VERSION ""

NS_ :

BS_:

BU_: VMCU TPM RCIOM FCIOM FAS ECUspare4 EBS EAS CCIOM BPMU APM

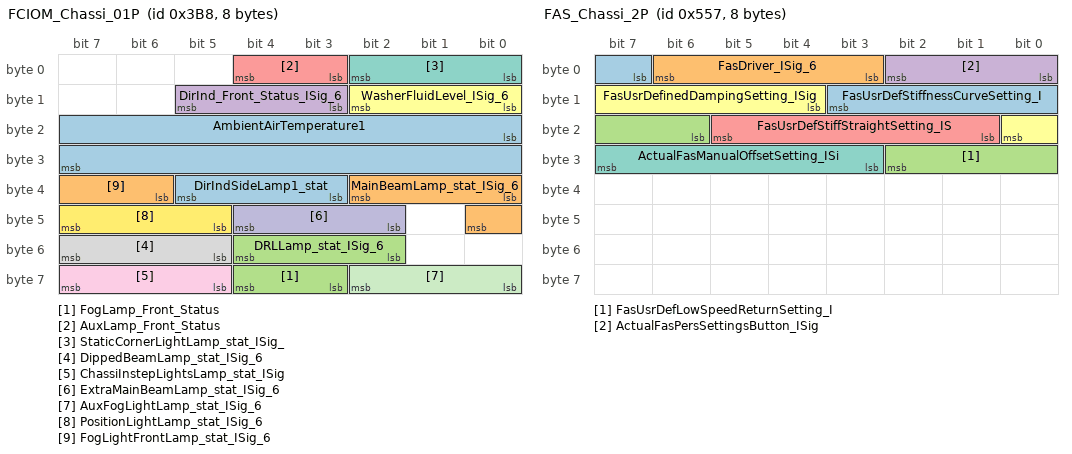
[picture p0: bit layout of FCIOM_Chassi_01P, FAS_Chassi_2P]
BO_ 952 FCIOM_Chassi_01P: 8 FCIOM
 SG_ DirIndSideLamp1_stat : 35|3@1+ (1,0) [0|0] ""  VMCU
 SG_ MainBeamLamp_stat_ISig_6 : 32|3@1+ (1,0) [0|0] ""  VMCU
 SG_ FogLamp_Front_Status : 59|2@1+ (1,0) [0|0] ""  VMCU
 SG_ DirInd_Front_Status_ISig_6 : 11|3@1+ (1,0) [0|0] ""  VMCU
 SG_ AuxLamp_Front_Status : 3|2@1+ (1,0) [0|0] ""  VMCU
 SG_ WasherFluidLevel_ISig_6 : 8|3@1+ (1,0) [0|0] ""  VMCU
 SG_ StaticCornerLightLamp_stat_ISig_ : 0|3@1+ (1,0) [0|0] ""  VMCU
 SG_ DippedBeamLamp_stat_ISig_6 : 53|3@1+ (1,0) [0|0] ""  VMCU
 SG_ ChassiInstepLightsLamp_stat_ISig : 61|3@1+ (1,0) [0|0] ""  VMCU
 SG_ ExtraMainBeamLamp_stat_ISig_6 : 42|3@1+ (1,0) [0|0] ""  VMCU
 SG_ AuxFogLightLamp_stat_ISig_6 : 56|3@1+ (1,0) [0|0] ""  VMCU
 SG_ PositionLightLamp_stat_ISig_6 : 45|3@1+ (1,0) [0|0] ""  VMCU
 SG_ AmbientAirTemperature1 : 16|16@1+ (0.03125,-273) [-273|1774.96875] "DegreeC"  VMCU
 SG_ FogLightFrontLamp_stat_ISig_6 : 38|3@1+ (1,0) [0|0] ""  VMCU
 SG_ DRLLamp_stat_ISig_6 : 50|3@1+ (1,0) [0|0] ""  VMCU

BO_ 1367 FAS_Chassi_2P: 8 FAS
 SG_ FasUsrDefStiffnessCurveSetting_I : 7|5@1+ (1,-10) [-10|21] ""  VMCU
 SG_ FasDriver_ISig_6 : 3|4@1+ (1,0) [0|0] ""  VMCU
 SG_ FasUsrDefLowSpeedReturnSetting_I : 22|5@1+ (1,-10) [-10|21] ""  VMCU
 SG_ ActualFasPersSettingsButton_ISig : 0|3@1+ (1,0) [0|0] ""  VMCU
 SG_ FasUsrDefStiffStraightSetting_IS : 17|5@1+ (1,-10) [-10|21] ""  VMCU
 SG_ FasUsrDefinedDampingSetting_ISig : 12|5@1+ (1,-10) [-10|21] ""  VMCU
 SG_ ActualFasManualOffsetSetting_ISi : 27|5@1+ (1,-10) [-10|21] ""  VMCU

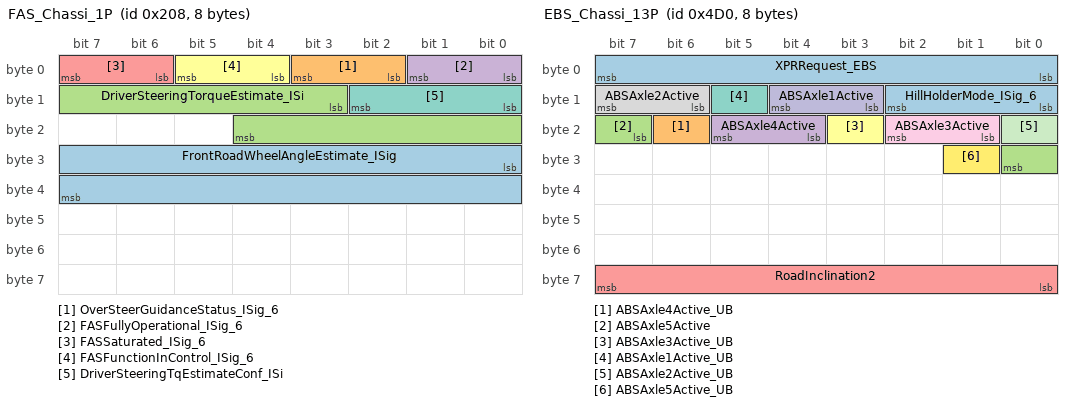
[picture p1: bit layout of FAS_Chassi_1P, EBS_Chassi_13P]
BO_ 520 FAS_Chassi_1P: 8 FAS
 SG_ FrontRoadWheelAngleEstimate_ISig : 24|16@1+ (5E-005,-1.6) [-1.6|1.67675] "rad"  VMCU
 SG_ OverSteerGuidanceStatus_ISig_6 : 2|2@1+ (1,0) [0|0] ""  VMCU
 SG_ DriverSteeringTorqueEstimate_ISi : 11|10@1+ (0.05,-25) [-25|26.15] "Nm"  VMCU
 SG_ FASFullyOperational_ISig_6 : 0|2@1+ (1,0) [0|0] ""  VMCU
 SG_ FASSaturated_ISig_6 : 6|2@1+ (1,0) [0|0] ""  VMCU
 SG_ FASFunctionInControl_ISig_6 : 4|2@1+ (1,0) [0|0] ""  VMCU
 SG_ DriverSteeringTqEstimateConf_ISi : 8|3@1+ (1,0) [0|0] ""  VMCU

BO_ 1232 EBS_Chassi_13P: 8 EBS
 SG_ XPRRequest_EBS : 0|8@1+ (1,0) [0|255] "NotApplicable"  APM
 SG_ ABSAxle4Active_UB : 22|1@1+ (1,0) [0|0] ""  APM
 SG_ ABSAxle5Active : 23|2@1+ (1,0) [0|0] ""  APM
 SG_ ABSAxle4Active : 20|2@1+ (1,0) [0|0] ""  APM
 SG_ RoadInclination2 : 56|8@1+ (0.2,-25) [-25|26] "percent"  VMCU
 SG_ ABSAxle3Active_UB : 19|1@1+ (1,0) [0|0] ""  APM
 SG_ ABSAxle1Active_UB : 13|1@1+ (1,0) [0|0] ""  APM
 SG_ ABSAxle2Active : 14|2@1+ (1,0) [0|0] ""  APM
 SG_ ABSAxle3Active : 17|2@1+ (1,0) [0|0] ""  APM
 SG_ ABSAxle1Active : 11|2@1+ (1,0) [0|0] ""  APM
 SG_ ABSAxle2Active_UB : 16|1@1+ (1,0) [0|0] ""  APM
 SG_ ABSAxle5Active_UB : 25|1@1+ (1,0) [0|0] ""  APM
 SG_ HillHolderMode_ISig_6 : 8|3@1+ (1,0) [0|0] ""  APM

BO_ 1507 EBS_Chassi_12P: 8 EBS
 SG_ ScndFrAxleLtRemainBrakeLining : 0|8@1+ (0.4,0) [0|102] "Percent"  VMCU
 SG_ ScndFrAxleRtRemainBrakeLining : 8|8@1+ (0.4,0) [0|102] "Percent"  VMCU

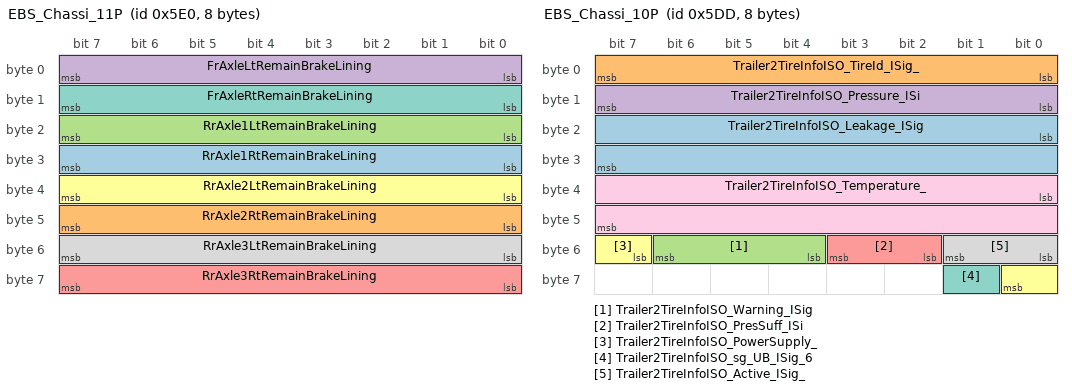
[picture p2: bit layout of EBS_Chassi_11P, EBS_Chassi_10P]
BO_ 1504 EBS_Chassi_11P: 8 EBS
 SG_ RrAxle1RtRemainBrakeLining : 24|8@1+ (0.4,0) [0|102] "Percent"  VMCU
 SG_ RrAxle2RtRemainBrakeLining : 40|8@1+ (0.4,0) [0|102] "Percent"  VMCU
 SG_ RrAxle1LtRemainBrakeLining : 16|8@1+ (0.4,0) [0|102] "Percent"  VMCU
 SG_ FrAxleLtRemainBrakeLining : 0|8@1+ (0.4,0) [0|102] "Percent"  VMCU
 SG_ RrAxle3RtRemainBrakeLining : 56|8@1+ (0.4,0) [0|102] "Percent"  VMCU
 SG_ RrAxle2LtRemainBrakeLining : 32|8@1+ (0.4,0) [0|102] "Percent"  VMCU
 SG_ FrAxleRtRemainBrakeLining : 8|8@1+ (0.4,0) [0|102] "Percent"  VMCU
 SG_ RrAxle3LtRemainBrakeLining : 48|8@1+ (0.4,0) [0|102] "Percent"  VMCU

BO_ 1501 EBS_Chassi_10P: 8 EBS
 SG_ Trailer2TireInfoISO_Leakage_ISig : 16|16@1+ (0.1,0) [0|6553.5] "Pa_per_s"  TPM
 SG_ Trailer2TireInfoISO_TireId_ISig_ : 0|8@1+ (1,0) [0|255] "NotApplicable"  TPM
 SG_ Trailer2TireInfoISO_Warning_ISig : 52|3@1+ (1,0) [0|0] ""  TPM
 SG_ Trailer2TireInfoISO_Pressure_ISi : 8|8@1+ (10,0) [0|2550] "kPa"  TPM
 SG_ Trailer2TireInfoISO_PresSuff_ISi : 50|2@1+ (1,0) [0|0] ""  TPM
 SG_ Trailer2TireInfoISO_PowerSupply_ : 55|2@1+ (1,0) [0|0] ""  TPM
 SG_ Trailer2TireInfoISO_sg_UB_ISig_6 : 57|1@1+ (1,0) [0|0] ""  TPM
 SG_ Trailer2TireInfoISO_Active_ISig_ : 48|2@1+ (1,0) [0|0] ""  TPM
 SG_ Trailer2TireInfoISO_Temperature_ : 32|16@1+ (0.03125,-273) [-273|1774.96875] "DegreeC"  TPM

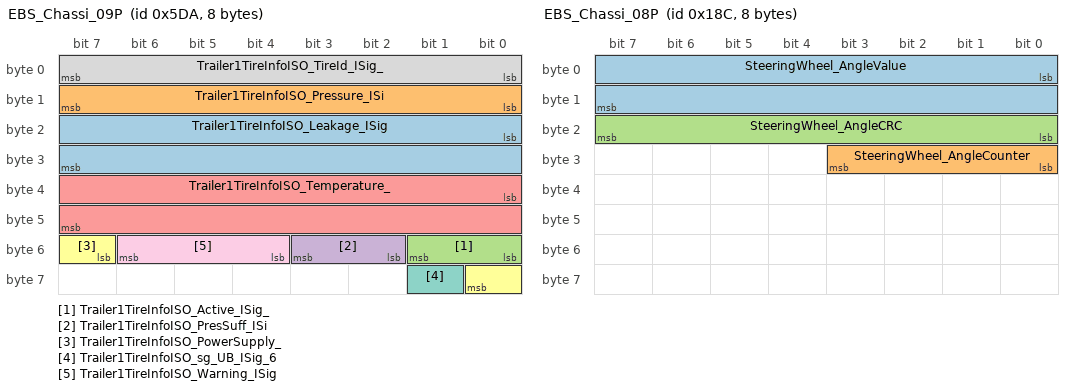
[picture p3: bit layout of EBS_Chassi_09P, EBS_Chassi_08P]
BO_ 1498 EBS_Chassi_09P: 8 EBS
 SG_ Trailer1TireInfoISO_Leakage_ISig : 16|16@1+ (0.1,0) [0|6553.5] "Pa_per_s"  TPM
 SG_ Trailer1TireInfoISO_Pressure_ISi : 8|8@1+ (10,0) [0|2550] "kPa"  TPM
 SG_ Trailer1TireInfoISO_Active_ISig_ : 48|2@1+ (1,0) [0|0] ""  TPM
 SG_ Trailer1TireInfoISO_PresSuff_ISi : 50|2@1+ (1,0) [0|0] ""  TPM
 SG_ Trailer1TireInfoISO_Temperature_ : 32|16@1+ (0.03125,-273) [-273|1774.96875] "DegreeC"  TPM
 SG_ Trailer1TireInfoISO_PowerSupply_ : 55|2@1+ (1,0) [0|0] ""  TPM
 SG_ Trailer1TireInfoISO_sg_UB_ISig_6 : 57|1@1+ (1,0) [0|0] ""  TPM
 SG_ Trailer1TireInfoISO_TireId_ISig_ : 0|8@1+ (1,0) [0|255] "NotApplicable"  TPM
 SG_ Trailer1TireInfoISO_Warning_ISig : 52|3@1+ (1,0) [0|0] ""  TPM

BO_ 396 EBS_Chassi_08P: 8 EBS
 SG_ SteeringWheel_AngleValue : 0|16@1+ (0.0009765625,-31.374) [-31.374|32.6250234375] "rad"  EAS
 SG_ SteeringWheel_AngleCounter : 24|4@1+ (1,0) [0|15] ""  EAS
 SG_ SteeringWheel_AngleCRC : 16|8@1+ (1,0) [0|255] ""  EAS

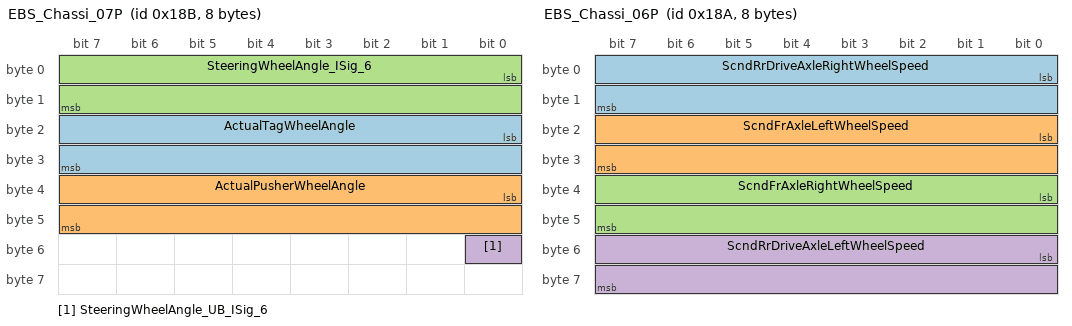
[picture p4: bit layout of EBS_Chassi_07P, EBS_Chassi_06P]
BO_ 395 EBS_Chassi_07P: 8 EBS
 SG_ ActualTagWheelAngle : 16|16@1+ (0.01,-50) [-50|605.35] "deg"  FAS
 SG_ ActualPusherWheelAngle : 32|16@1+ (0.01,-50) [-50|605.35] "deg"  FAS
 SG_ SteeringWheelAngle_ISig_6 : 0|16@1+ (0.0009765625,-31.374) [-31.374|32.6250234375] "rad"  RCIOM,FAS
 SG_ SteeringWheelAngle_UB_ISig_6 : 48|1@1+ (1,0) [0|0] ""  FAS,RCIOM

BO_ 394 EBS_Chassi_06P: 8 EBS
 SG_ ScndRrDriveAxleRightWheelSpeed : 0|16@1+ (0.00390625,0) [0|255.99609375] "Km_per_h"  CCIOM,VMCU,RCIOM
 SG_ ScndFrAxleLeftWheelSpeed : 16|16@1+ (0.00390625,0) [0|255.99609375] "Km_per_h"  FAS,VMCU
 SG_ ScndFrAxleRightWheelSpeed : 32|16@1+ (0.00390625,0) [0|255.99609375] "Km_per_h"  VMCU,FAS
 SG_ ScndRrDriveAxleLeftWheelSpeed : 48|16@1+ (0.00390625,0) [0|255.99609375] "Km_per_h"  CCIOM,VMCU,RCIOM

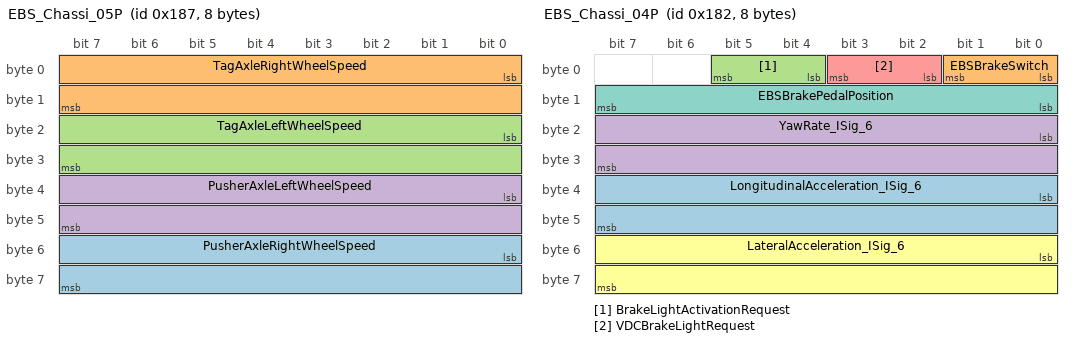
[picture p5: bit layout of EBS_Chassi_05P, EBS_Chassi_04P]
BO_ 391 EBS_Chassi_05P: 8 EBS
 SG_ PusherAxleRightWheelSpeed : 48|16@1+ (0.00390625,0) [0|255.99609375] "Km_per_h"  EAS,VMCU
 SG_ TagAxleRightWheelSpeed : 0|16@1+ (0.00390625,0) [0|255.99609375] "Km_per_h"  EAS,VMCU
 SG_ TagAxleLeftWheelSpeed : 16|16@1+ (0.00390625,0) [0|255.99609375] "Km_per_h"  EAS,VMCU
 SG_ PusherAxleLeftWheelSpeed : 32|16@1+ (0.00390625,0) [0|255.99609375] "Km_per_h"  EAS,VMCU

BO_ 386 EBS_Chassi_04P: 8 EBS
 SG_ LongitudinalAcceleration_ISig_6 : 32|16@1+ (0.00048828125,-15.687) [-15.687|16.31251171875] "m_per_s_squared"  VMCU,RCIOM
 SG_ EBSBrakeSwitch : 0|2@1+ (1,0) [0|0] ""  APM,VMCU
 SG_ BrakeLightActivationRequest : 4|2@1+ (1,0) [0|0] ""  RCIOM
 SG_ YawRate_ISig_6 : 16|16@1+ (0.000122,-3.92) [-3.92|4.07527] "Rad_per_s"  FAS
 SG_ VDCBrakeLightRequest : 2|2@1+ (1,0) [0|0] ""  RCIOM
 SG_ LateralAcceleration_ISig_6 : 48|16@1+ (0.00048828125,-15.687) [-15.687|16.31251171875] "m_per_s_squared"  VMCU,RCIOM,FAS
 SG_ EBSBrakePedalPosition : 8|8@1+ (0.4,0) [0|102] "Percent"  VMCU,APM

BO_ 824 EBS_Chassi_03P: 8 EBS
 SG_ TrailerEBSAmberWarning : 42|2@1+ (1,0) [0|0] ""  RCIOM
 SG_ HSAState_ISig_6 : 4|2@1+ (1,0) [0|0] ""  APM
 SG_ PusherLiftAxleLoweringInhibit : 8|2@1+ (1,0) [0|0] ""  RCIOM
 SG_ TrailersConnected_ISig_6 : 21|3@1+ (1,0) [0|7] "Count"  RCIOM
 SG_ YCBrakeControlActive_ISig_6 : 12|2@1+ (1,0) [0|0] ""  FAS,APM,EAS
 SG_ YCEngineControlActive_ISig_6 : 38|2@1+ (1,0) [0|0] ""  FAS
 SG_ StretchBrake_Stat_ISig_6 : 16|3@1+ (1,0) [0|0] ""  RCIOM
 SG_ Trailer1LiftAxle1Pos_ISig_6 : 14|2@1+ (1,0) [0|0] ""  RCIOM
 SG_ Trailer1LiftAxle2Pos_ISig_6 : 19|2@1+ (1,0) [0|0] ""  RCIOM
 SG_ SteeringWheelAngleComp : 48|16@1+ (0.0009765625,-31.374) [-31.374|32.6250234375] "rad"  FAS
 SG_ FrontParkBrakeOverrideStatus : 10|2@1+ (1,0) [0|0] ""  RCIOM
 SG_ BrakingSystemPressureLim_rqst : 34|2@1+ (1,0) [0|0] ""  CCIOM,APM
 SG_ ROPEngineControlActive_ISig_6 : 36|2@1+ (1,0) [0|0] ""  FAS
 SG_ TrailerControlPressure : 24|8@1+ (5,0) [0|1275] "kPa"  APM,VMCU
 SG_ Trailer1TractionHelp_ISig_6 : 32|2@1+ (1,0) [0|0] ""  RCIOM
 SG_ TagLiftAxleLoweringInhibit : 6|2@1+ (1,0) [0|0] ""  RCIOM
 SG_ ROPBrakeControlActive_ISig_6 : 0|2@1+ (1,0) [0|0] ""  FAS,APM
 SG_ SplitBoxDiffLockActvnFuncReq : 40|2@1+ (1,0) [0|0] ""  VMCU,CCIOM
 SG_ TrailerBrake_Stat : 2|2@1+ (1,0) [0|0] ""  VMCU,RCIOM

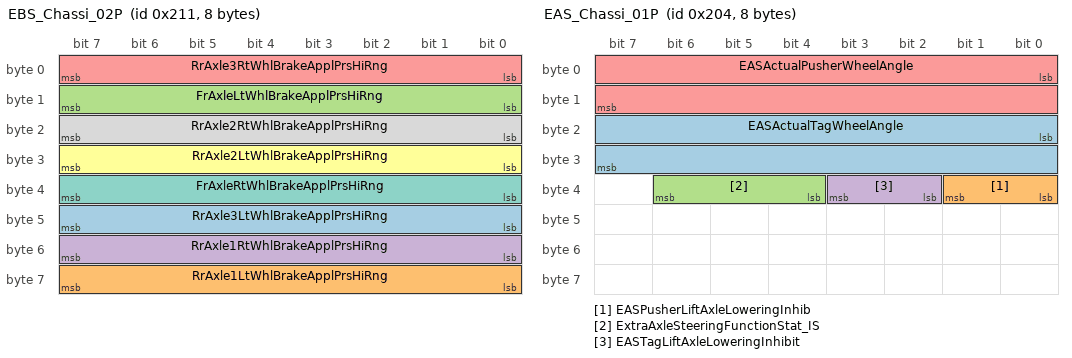
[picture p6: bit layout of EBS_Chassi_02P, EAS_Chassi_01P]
BO_ 529 EBS_Chassi_02P: 8 EBS
 SG_ RrAxle3LtWhlBrakeApplPrsHiRng : 40|8@1+ (5,0) [0|1275] "kPa"  FAS,APM,VMCU
 SG_ RrAxle1LtWhlBrakeApplPrsHiRng : 56|8@1+ (5,0) [0|1275] "kPa"  FAS,APM,VMCU
 SG_ FrAxleLtWhlBrakeApplPrsHiRng : 8|8@1+ (5,0) [0|1275] "kPa"  VMCU,FAS,APM
 SG_ RrAxle1RtWhlBrakeApplPrsHiRng : 48|8@1+ (5,0) [0|1275] "kPa"  VMCU,FAS,APM
 SG_ RrAxle3RtWhlBrakeApplPrsHiRng : 0|8@1+ (5,0) [0|1275] "kPa"  FAS,APM,VMCU
 SG_ RrAxle2LtWhlBrakeApplPrsHiRng : 24|8@1+ (5,0) [0|1275] "kPa"  APM,FAS,VMCU
 SG_ FrAxleRtWhlBrakeApplPrsHiRng : 32|8@1+ (5,0) [0|1275] "kPa"  FAS,VMCU,APM
 SG_ RrAxle2RtWhlBrakeApplPrsHiRng : 16|8@1+ (5,0) [0|1275] "kPa"  APM,VMCU,FAS

BO_ 516 EAS_Chassi_01P: 8 EAS
 SG_ EASActualTagWheelAngle : 16|16@1+ (0.01,-50) [-50|605.35] "deg"  FAS
 SG_ EASPusherLiftAxleLoweringInhib : 32|2@1+ (1,0) [0|0] ""  RCIOM
 SG_ ExtraAxleSteeringFunctionStat_IS : 36|3@1+ (1,0) [0|0] ""  VMCU
 SG_ EASTagLiftAxleLoweringInhibit : 34|2@1+ (1,0) [0|0] ""  RCIOM
 SG_ EASActualPusherWheelAngle : 0|16@1+ (0.01,-50) [-50|605.35] "deg"  FAS

BO_ 2672226850 DiagUUDTRespMsg5_F2_22_Chassi: 8 RCIOM
 SG_ DiagUUDTRespSig5_F2_22_ISig_6 : 0|64@1+ (1,0) [0|0] ""  VMCU

BO_ 2672226848 DiagUUDTRespMsg5_F2_20_Chassi: 8 CCIOM
 SG_ DiagUUDTRespSig5_F2_20_ISig_6 : 0|64@1+ (1,0) [0|0] ""  VMCU

BO_ 2672161314 DiagUUDTRespMsg4_F2_22_Chassi: 8 RCIOM
 SG_ DiagUUDTRespSig4_F2_22_ISig_6 : 0|64@1+ (1,0) [0|0] ""  VMCU

BO_ 2672161312 DiagUUDTRespMsg4_F2_20_Chassi: 8 CCIOM
 SG_ DiagUUDTRespSig4_F2_20_ISig_6 : 0|64@1+ (1,0) [0|0] ""  VMCU

BO_ 2672095778 DiagUUDTRespMsg3_F2_22_Chassi: 8 RCIOM
 SG_ DiagUUDTRespSig3_F2_22_ISig_6 : 0|64@1+ (1,0) [0|0] ""  VMCU

BO_ 2672095776 DiagUUDTRespMsg3_F2_20_Chassi: 8 CCIOM
 SG_ DiagUUDTRespSig3_F2_20_ISig_6 : 0|64@1+ (1,0) [0|0] ""  VMCU

BO_ 2672030242 DiagUUDTRespMsg2_F2_22_Chassi: 8 RCIOM
 SG_ DiagUUDTRespSig2_F2_22_ISig_6 : 0|64@1+ (1,0) [0|0] ""  VMCU

BO_ 2672030240 DiagUUDTRespMsg2_F2_20_Chassi: 8 CCIOM
 SG_ DiagUUDTRespSig2_F2_20_ISig_6 : 0|64@1+ (1,0) [0|0] ""  VMCU

BO_ 2671964786 DiagUUDTRespMsg1_F2_72_Chas: 8 FCIOM
 SG_ DiagUUDTRespSig_F2_72_ISig_6 : 0|64@1+ (1,0) [0|0] ""  VMCU

BO_ 2671964785 DiagUUDTRespMsg1_F2_71_Chas: 8 FCIOM
 SG_ DiagUUDTRespSig_F2_71_ISig_6 : 0|64@1+ (1,0) [0|0] ""  VMCU

BO_ 2671964721 DiagUUDTRespMsg1_F2_31_Chassi: 8 EAS
 SG_ DiagUUDTRespSig_F2_31_ISig_6 : 0|64@1+ (1,0) [0|0] ""  VMCU

BO_ 2671964720 DiagUUDTRespMsg1_F2_30_Chassi: 8 FAS
 SG_ DiagUUDTRespSig_F2_30_ISig_6 : 0|64@1+ (1,0) [0|0] ""  VMCU

BO_ 2671964709 DiagUUDTRespMsg1_F2_25_Chassi: 8 TPM
 SG_ DiagUUDTRespSig_F2_25_ISig_6 : 0|64@1+ (1,0) [0|0] ""  VMCU

BO_ 2671964707 DiagUUDTRespMsg1_F2_23_Chassi: 8 APM
 SG_ DiagUUDTRespSig_F2_23_ISig_6 : 0|64@1+ (1,0) [0|0] ""  VMCU

BO_ 2671964706 DiagUUDTRespMsg1_F2_22_Chassi: 8 RCIOM
 SG_ DiagUUDTRespSig_F2_22_ISig_6 : 0|64@1+ (1,0) [0|0] ""  VMCU

BO_ 2671964705 DiagUUDTRespMsg1_F2_21_Chassi: 8 FCIOM
 SG_ DiagUUDTRespSig_F2_21_ISig_6 : 0|64@1+ (1,0) [0|0] ""  VMCU

BO_ 2671964704 DiagUUDTRespMsg1_F2_20_Chassi: 8 CCIOM
 SG_ DiagUUDTRespSig_F2_20_ISig_6 : 0|64@1+ (1,0) [0|0] ""  VMCU

BO_ 2671964698 DiagUUDTRespMsg1_F2_1A_Chassi: 8 BPMU
 SG_ DiagUUDTRespSig_F2_1A_ISig_6 : 0|64@1+ (1,0) [0|0] ""  VMCU

BO_ 2671834226 DiagRespMsgIntTGW2_F4_72_Chas: 8 FCIOM
 SG_ InternalTesterDiagSig_F4_72_ISig : 0|64@1+ (1,0) [0|0] ""  VMCU

BO_ 2671834225 DiagRespMsgIntTGW2_F4_71_Chas: 8 FCIOM
 SG_ InternalTesterDiagSig_F4_71_ISig : 0|64@1+ (1,0) [0|0] ""  VMCU

BO_ 2671834161 DiagRespMsgIntTGW2_F4_31_Chas: 8 EAS
 SG_ InternalTesterDiagSig_F4_31_ISig : 0|64@1+ (1,0) [0|0] ""  VMCU

BO_ 2671834160 DiagRespMsgIntTGW2_F4_30_Chas: 8 FAS
 SG_ InternalTesterDiagSig_F4_30_ISig : 0|64@1+ (1,0) [0|0] ""  VMCU

BO_ 2671834149 DiagRespMsgIntTGW2_F4_25_Chas: 8 TPM
 SG_ InternalTesterDiagSig_F4_25_ISig : 0|64@1+ (1,0) [0|0] ""  VMCU

BO_ 2671834147 DiagRespMsgIntTGW2_F4_23_Chas: 8 APM
 SG_ InternalTesterDiagSig_F4_23_ISig : 0|64@1+ (1,0) [0|0] ""  VMCU

BO_ 2671834146 DiagRespMsgIntTGW2_F4_22_Chas: 8 RCIOM
 SG_ InternalTesterDiagSig_F4_22_ISig : 0|64@1+ (1,0) [0|0] ""  VMCU

BO_ 2671834145 DiagRespMsgIntTGW2_F4_21_Chas: 8 FCIOM
 SG_ InternalTesterDiagSig_F4_21_ISig : 0|64@1+ (1,0) [0|0] ""  VMCU

BO_ 2671834144 DiagRespMsgIntTGW2_F4_20_Chas: 8 CCIOM
 SG_ InternalTesterDiagSig_F4_20_ISig : 0|64@1+ (1,0) [0|0] ""  VMCU

BO_ 2671834138 DiagRespMsgIntTGW2_F4_1A_Chas: 8 BPMU
 SG_ InternalTesterDiagSig_F4_1A_ISig : 0|64@1+ (1,0) [0|0] ""  VMCU

BO_ 2671833970 DiagRespMsgIntHMIIOM_F3_72_Chas: 8 FCIOM
 SG_ InternalTesterDiagSig_F3_72_ISig : 0|64@1+ (1,0) [0|0] ""  VMCU

BO_ 2671833969 DiagRespMsgIntHMIIOM_F3_71_Chas: 8 FCIOM
 SG_ InternalTesterDiagSig_F3_71_ISig : 0|64@1+ (1,0) [0|0] ""  VMCU

BO_ 2671833905 DiagRespMsgIntHMIIOM_F3_31_Chas: 8 EAS
 SG_ InternalTesterDiagSig_F3_31_ISig : 0|64@1+ (1,0) [0|0] ""  VMCU

BO_ 2671833904 DiagRespMsgIntHMIIOM_F3_30_Chas: 8 FAS
 SG_ InternalTesterDiagSig_F3_30_ISig : 0|64@1+ (1,0) [0|0] ""  VMCU

BO_ 2671833893 DiagRespMsgIntHMIIOM_F3_25_Chas: 8 TPM
 SG_ InternalTesterDiagSig_F3_25_ISig : 0|64@1+ (1,0) [0|0] ""  VMCU

BO_ 2671833891 DiagRespMsgIntHMIIOM_F3_23_Chas: 8 APM
 SG_ InternalTesterDiagSig_F3_23_ISig : 0|64@1+ (1,0) [0|0] ""  VMCU

BO_ 2671833890 DiagRespMsgIntHMIIOM_F3_22_Chas: 8 RCIOM
 SG_ InternalTesterDiagSig_F3_22_ISig : 0|64@1+ (1,0) [0|0] ""  VMCU

BO_ 2671833889 DiagRespMsgIntHMIIOM_F3_21_Chas: 8 FCIOM
 SG_ InternalTesterDiagSig_F3_21_ISig : 0|64@1+ (1,0) [0|0] ""  VMCU

BO_ 2671833888 DiagRespMsgIntHMIIOM_F3_20_Chas: 8 CCIOM
 SG_ InternalTesterDiagSig_F3_20_ISig : 0|64@1+ (1,0) [0|0] ""  VMCU

BO_ 2671833882 DiagRespMsgIntHMIIOM_F3_1A_Chas: 8 BPMU
 SG_ InternalTesterDiagSig_F3_1A_ISig : 0|64@1+ (1,0) [0|0] ""  VMCU

BO_ 2671801076 DiagReqMsgIntTGW2_72_F4_Chas: 8 VMCU
 SG_ InternalTesterDiagSig_72_F4_ISig : 0|64@1+ (1,0) [0|0] ""  FCIOM

BO_ 2671800820 DiagReqMsgIntTGW2_71_F4_Chas: 8 VMCU
 SG_ InternalTesterDiagSig_71_F4_ISig : 0|64@1+ (1,0) [0|0] ""  FCIOM

BO_ 2671784436 DiagReqMsgIntTGW2_31_F4_Chas: 8 VMCU
 SG_ InternalTesterDiagSig_31_F4_ISig : 0|64@1+ (1,0) [0|0] ""  EAS

BO_ 2671784180 DiagReqMsgIntTGW2_30_F4_Chas: 8 VMCU
 SG_ InternalTesterDiagSig_30_F4_ISig : 0|64@1+ (1,0) [0|0] ""  FAS

BO_ 2671781364 DiagReqMsgIntTGW2_25_F4_Chas: 8 VMCU
 SG_ InternalTesterDiagSig_25_F4_ISig : 0|64@1+ (1,0) [0|0] ""  TPM

BO_ 2671780852 DiagReqMsgIntTGW2_23_F4_Chas: 8 VMCU
 SG_ InternalTesterDiagSig_23_F4_ISig : 0|64@1+ (1,0) [0|0] ""  APM

BO_ 2671780596 DiagReqMsgIntTGW2_22_F4_Chas: 8 VMCU
 SG_ InternalTesterDiagSig_22_F4_ISig : 0|64@1+ (1,0) [0|0] ""  RCIOM

BO_ 2671780340 DiagReqMsgIntTGW2_21_F4_Chas: 8 VMCU
 SG_ InternalTesterDiagSig_21_F4_ISig : 0|64@1+ (1,0) [0|0] ""  FCIOM

BO_ 2671780084 DiagReqMsgIntTGW2_20_F4_Chas: 8 VMCU
 SG_ InternalTesterDiagSig_20_F4_ISig : 0|64@1+ (1,0) [0|0] ""  CCIOM

BO_ 2671778548 DiagReqMsgIntTGW2_1A_F4_Chas: 8 VMCU
 SG_ InternalTesterDiagSig_1A_F4_ISig : 0|64@1+ (1,0) [0|0] ""  BPMU

BO_ 2671801075 DiagReqMsgIntHMIIOM_72_F3_Chas: 8 VMCU
 SG_ InternalTesterDiagSig_72_F3_ISig : 0|64@1+ (1,0) [0|0] ""  FCIOM

BO_ 2671800819 DiagReqMsgIntHMIIOM_71_F3_Chas: 8 VMCU
 SG_ InternalTesterDiagSig_71_F3_ISig : 0|64@1+ (1,0) [0|0] ""  FCIOM

BO_ 2671784435 DiagReqMsgIntHMIIOM_31_F3_Chas: 8 VMCU
 SG_ InternalTesterDiagSig_31_F3_ISig : 0|64@1+ (1,0) [0|0] ""  EAS

BO_ 2671784179 DiagReqMsgIntHMIIOM_30_F3_Chas: 8 VMCU
 SG_ InternalTesterDiagSig_30_F3_ISig : 0|64@1+ (1,0) [0|0] ""  FAS

BO_ 2671781363 DiagReqMsgIntHMIIOM_25_F3_Chas: 8 VMCU
 SG_ InternalTesterDiagSig_25_F3_ISig : 0|64@1+ (1,0) [0|0] ""  TPM

BO_ 2671780851 DiagReqMsgIntHMIIOM_23_F3_Chas: 8 VMCU
 SG_ InternalTesterDiagSig_23_F3_ISig : 0|64@1+ (1,0) [0|0] ""  APM

BO_ 2671780595 DiagReqMsgIntHMIIOM_22_F3_Chas: 8 VMCU
 SG_ InternalTesterDiagSig_22_F3_ISig : 0|64@1+ (1,0) [0|0] ""  RCIOM

BO_ 2671780339 DiagReqMsgIntHMIIOM_21_F3_Chas: 8 VMCU
 SG_ InternalTesterDiagSig_21_F3_ISig : 0|64@1+ (1,0) [0|0] ""  FCIOM

BO_ 2671780083 DiagReqMsgIntHMIIOM_20_F3_Chas: 8 VMCU
 SG_ InternalTesterDiagSig_20_F3_ISig : 0|64@1+ (1,0) [0|0] ""  CCIOM

BO_ 2671778547 DiagReqMsgIntHMIIOM_1A_F3_Chas: 8 VMCU
 SG_ InternalTesterDiagSig_1A_F3_ISig : 0|64@1+ (1,0) [0|0] ""  BPMU

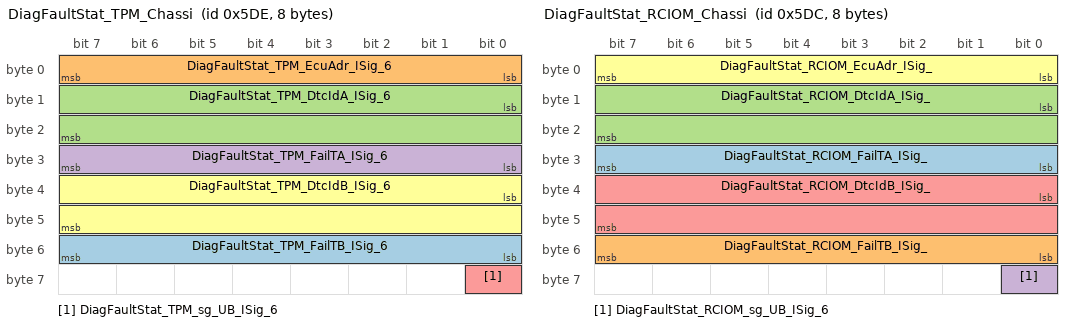
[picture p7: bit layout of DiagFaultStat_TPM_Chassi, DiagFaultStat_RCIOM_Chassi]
BO_ 1502 DiagFaultStat_TPM_Chassi: 8 TPM
 SG_ DiagFaultStat_TPM_FailTB_ISig_6 : 48|8@1+ (1,0) [0|255] ""  VMCU
 SG_ DiagFaultStat_TPM_EcuAdr_ISig_6 : 0|8@1+ (1,0) [0|255] ""  VMCU
 SG_ DiagFaultStat_TPM_DtcIdA_ISig_6 : 8|16@1+ (1,0) [0|65535] ""  VMCU
 SG_ DiagFaultStat_TPM_FailTA_ISig_6 : 24|8@1+ (1,0) [0|255] ""  VMCU
 SG_ DiagFaultStat_TPM_sg_UB_ISig_6 : 56|1@1+ (1,0) [0|0] ""  VMCU
 SG_ DiagFaultStat_TPM_DtcIdB_ISig_6 : 32|16@1+ (1,0) [0|65535] ""  VMCU

BO_ 1500 DiagFaultStat_RCIOM_Chassi: 8 RCIOM
 SG_ DiagFaultStat_RCIOM_FailTA_ISig_ : 24|8@1+ (1,0) [0|255] ""  VMCU
 SG_ DiagFaultStat_RCIOM_FailTB_ISig_ : 48|8@1+ (1,0) [0|255] ""  VMCU
 SG_ DiagFaultStat_RCIOM_DtcIdA_ISig_ : 8|16@1+ (1,0) [0|65535] ""  VMCU
 SG_ DiagFaultStat_RCIOM_sg_UB_ISig_6 : 56|1@1+ (1,0) [0|0] ""  VMCU
 SG_ DiagFaultStat_RCIOM_DtcIdB_ISig_ : 32|16@1+ (1,0) [0|65535] ""  VMCU
 SG_ DiagFaultStat_RCIOM_EcuAdr_ISig_ : 0|8@1+ (1,0) [0|255] ""  VMCU

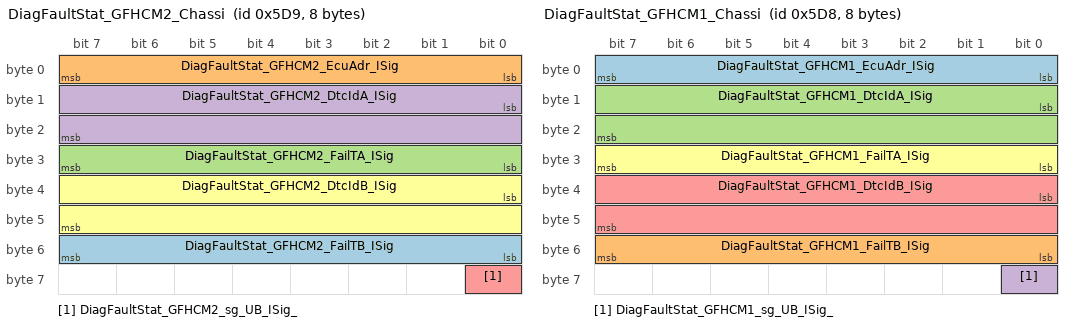
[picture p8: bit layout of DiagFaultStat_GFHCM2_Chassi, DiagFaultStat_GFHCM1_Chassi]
BO_ 1497 DiagFaultStat_GFHCM2_Chassi: 8 FCIOM
 SG_ DiagFaultStat_GFHCM2_FailTB_ISig : 48|8@1+ (1,0) [0|255] ""  VMCU
 SG_ DiagFaultStat_GFHCM2_EcuAdr_ISig : 0|8@1+ (1,0) [0|255] ""  VMCU
 SG_ DiagFaultStat_GFHCM2_FailTA_ISig : 24|8@1+ (1,0) [0|255] ""  VMCU
 SG_ DiagFaultStat_GFHCM2_DtcIdA_ISig : 8|16@1+ (1,0) [0|65535] ""  VMCU
 SG_ DiagFaultStat_GFHCM2_sg_UB_ISig_ : 56|1@1+ (1,0) [0|0] ""  VMCU
 SG_ DiagFaultStat_GFHCM2_DtcIdB_ISig : 32|16@1+ (1,0) [0|65535] ""  VMCU

BO_ 1496 DiagFaultStat_GFHCM1_Chassi: 8 FCIOM
 SG_ DiagFaultStat_GFHCM1_EcuAdr_ISig : 0|8@1+ (1,0) [0|255] ""  VMCU
 SG_ DiagFaultStat_GFHCM1_FailTB_ISig : 48|8@1+ (1,0) [0|255] ""  VMCU
 SG_ DiagFaultStat_GFHCM1_DtcIdA_ISig : 8|16@1+ (1,0) [0|65535] ""  VMCU
 SG_ DiagFaultStat_GFHCM1_sg_UB_ISig_ : 56|1@1+ (1,0) [0|0] ""  VMCU
 SG_ DiagFaultStat_GFHCM1_DtcIdB_ISig : 32|16@1+ (1,0) [0|65535] ""  VMCU
 SG_ DiagFaultStat_GFHCM1_FailTA_ISig : 24|8@1+ (1,0) [0|255] ""  VMCU

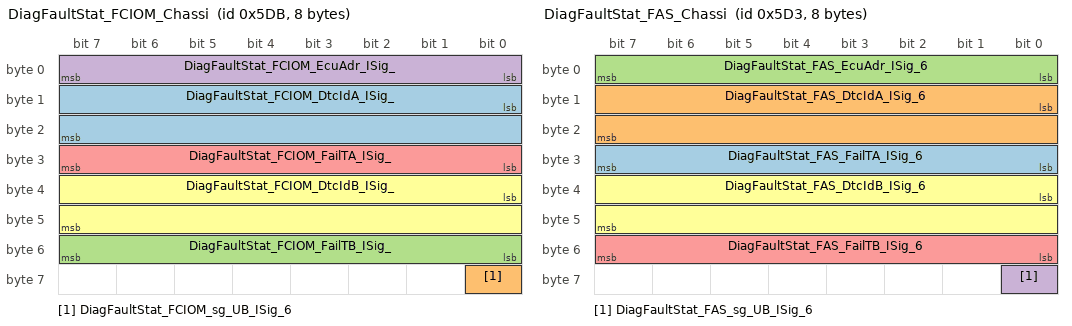
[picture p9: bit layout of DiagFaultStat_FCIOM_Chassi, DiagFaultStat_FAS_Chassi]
BO_ 1499 DiagFaultStat_FCIOM_Chassi: 8 FCIOM
 SG_ DiagFaultStat_FCIOM_DtcIdA_ISig_ : 8|16@1+ (1,0) [0|65535] ""  VMCU
 SG_ DiagFaultStat_FCIOM_sg_UB_ISig_6 : 56|1@1+ (1,0) [0|0] ""  VMCU
 SG_ DiagFaultStat_FCIOM_FailTB_ISig_ : 48|8@1+ (1,0) [0|255] ""  VMCU
 SG_ DiagFaultStat_FCIOM_EcuAdr_ISig_ : 0|8@1+ (1,0) [0|255] ""  VMCU
 SG_ DiagFaultStat_FCIOM_FailTA_ISig_ : 24|8@1+ (1,0) [0|255] ""  VMCU
 SG_ DiagFaultStat_FCIOM_DtcIdB_ISig_ : 32|16@1+ (1,0) [0|65535] ""  VMCU

BO_ 1491 DiagFaultStat_FAS_Chassi: 8 FAS
 SG_ DiagFaultStat_FAS_FailTA_ISig_6 : 24|8@1+ (1,0) [0|255] ""  VMCU
 SG_ DiagFaultStat_FAS_DtcIdA_ISig_6 : 8|16@1+ (1,0) [0|65535] ""  VMCU
 SG_ DiagFaultStat_FAS_EcuAdr_ISig_6 : 0|8@1+ (1,0) [0|255] ""  VMCU
 SG_ DiagFaultStat_FAS_sg_UB_ISig_6 : 56|1@1+ (1,0) [0|0] ""  VMCU
 SG_ DiagFaultStat_FAS_FailTB_ISig_6 : 48|8@1+ (1,0) [0|255] ""  VMCU
 SG_ DiagFaultStat_FAS_DtcIdB_ISig_6 : 32|16@1+ (1,0) [0|65535] ""  VMCU

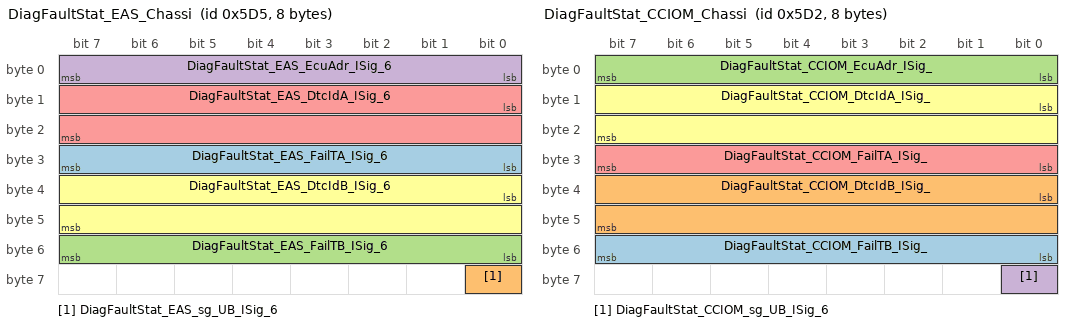
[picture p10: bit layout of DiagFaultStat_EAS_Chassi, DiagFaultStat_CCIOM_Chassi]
BO_ 1493 DiagFaultStat_EAS_Chassi: 8 EAS
 SG_ DiagFaultStat_EAS_FailTA_ISig_6 : 24|8@1+ (1,0) [0|255] ""  VMCU
 SG_ DiagFaultStat_EAS_sg_UB_ISig_6 : 56|1@1+ (1,0) [0|0] ""  VMCU
 SG_ DiagFaultStat_EAS_FailTB_ISig_6 : 48|8@1+ (1,0) [0|255] ""  VMCU
 SG_ DiagFaultStat_EAS_EcuAdr_ISig_6 : 0|8@1+ (1,0) [0|255] ""  VMCU
 SG_ DiagFaultStat_EAS_DtcIdA_ISig_6 : 8|16@1+ (1,0) [0|65535] ""  VMCU
 SG_ DiagFaultStat_EAS_DtcIdB_ISig_6 : 32|16@1+ (1,0) [0|65535] ""  VMCU

BO_ 1490 DiagFaultStat_CCIOM_Chassi: 8 CCIOM
 SG_ DiagFaultStat_CCIOM_FailTB_ISig_ : 48|8@1+ (1,0) [0|255] ""  VMCU
 SG_ DiagFaultStat_CCIOM_DtcIdB_ISig_ : 32|16@1+ (1,0) [0|65535] ""  VMCU
 SG_ DiagFaultStat_CCIOM_EcuAdr_ISig_ : 0|8@1+ (1,0) [0|255] ""  VMCU
 SG_ DiagFaultStat_CCIOM_sg_UB_ISig_6 : 56|1@1+ (1,0) [0|0] ""  VMCU
 SG_ DiagFaultStat_CCIOM_FailTA_ISig_ : 24|8@1+ (1,0) [0|255] ""  VMCU
 SG_ DiagFaultStat_CCIOM_DtcIdA_ISig_ : 8|16@1+ (1,0) [0|65535] ""  VMCU

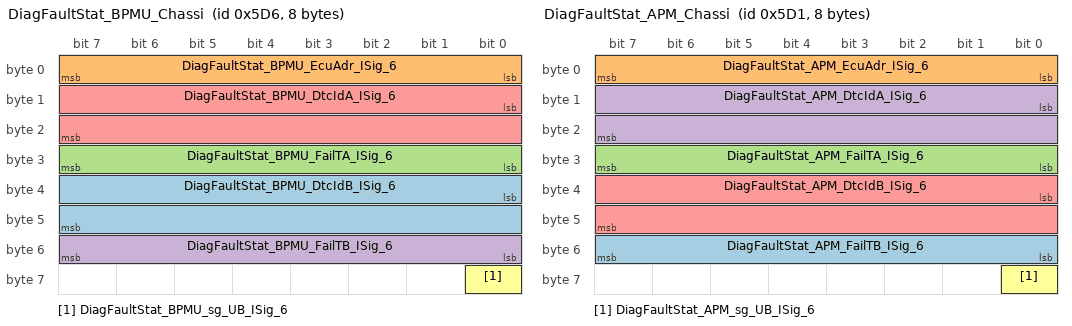
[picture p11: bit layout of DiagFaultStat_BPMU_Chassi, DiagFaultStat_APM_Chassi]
BO_ 1494 DiagFaultStat_BPMU_Chassi: 8 BPMU
 SG_ DiagFaultStat_BPMU_DtcIdB_ISig_6 : 32|16@1+ (1,0) [0|65535] ""  VMCU
 SG_ DiagFaultStat_BPMU_EcuAdr_ISig_6 : 0|8@1+ (1,0) [0|255] ""  VMCU
 SG_ DiagFaultStat_BPMU_FailTA_ISig_6 : 24|8@1+ (1,0) [0|255] ""  VMCU
 SG_ DiagFaultStat_BPMU_FailTB_ISig_6 : 48|8@1+ (1,0) [0|255] ""  VMCU
 SG_ DiagFaultStat_BPMU_DtcIdA_ISig_6 : 8|16@1+ (1,0) [0|65535] ""  VMCU
 SG_ DiagFaultStat_BPMU_sg_UB_ISig_6 : 56|1@1+ (1,0) [0|0] ""  VMCU

BO_ 1489 DiagFaultStat_APM_Chassi: 8 APM
 SG_ DiagFaultStat_APM_FailTB_ISig_6 : 48|8@1+ (1,0) [0|255] ""  VMCU
 SG_ DiagFaultStat_APM_EcuAdr_ISig_6 : 0|8@1+ (1,0) [0|255] ""  VMCU
 SG_ DiagFaultStat_APM_FailTA_ISig_6 : 24|8@1+ (1,0) [0|255] ""  VMCU
 SG_ DiagFaultStat_APM_DtcIdA_ISig_6 : 8|16@1+ (1,0) [0|65535] ""  VMCU
 SG_ DiagFaultStat_APM_DtcIdB_ISig_6 : 32|16@1+ (1,0) [0|65535] ""  VMCU
 SG_ DiagFaultStat_APM_sg_UB_ISig_6 : 56|1@1+ (1,0) [0|0] ""  VMCU

BO_ 1952 Debug9_RCIOM_Chassi: 8 RCIOM
 SG_ Debug_9_RCIOM : 0|64@1+ (1,0) [0|0] "" Vector__XXX

BO_ 1954 Debug9_FAS_Chassi: 8 FAS
 SG_ Debug_9_FAS : 0|64@1+ (1,0) [0|0] "" Vector__XXX

BO_ 1951 Debug9_CCIOM_Chassi: 8 CCIOM
 SG_ Debug_9_CCIOM : 0|64@1+ (1,0) [0|0] "" Vector__XXX

BO_ 1950 Debug9_BPMU_Chassi: 8 BPMU
 SG_ Debug_9_BPMU : 0|64@1+ (1,0) [0|0] "" Vector__XXX

BO_ 1953 Debug9_APM_Chassi: 8 APM
 SG_ Debug_9_APM : 0|64@1+ (1,0) [0|0] "" Vector__XXX

BO_ 1947 Debug8_RCIOM_Chassi: 8 RCIOM
 SG_ Debug_8_RCIOM : 0|64@1+ (1,0) [0|0] "" Vector__XXX

BO_ 1949 Debug8_FAS_Chassi: 8 Vector__XXX
 SG_ Debug_8_FAS : 0|64@1+ (1,0) [0|0] ""  FAS

BO_ 1946 Debug8_CCIOM_Chassi: 8 CCIOM
 SG_ Debug_8_CCIOM : 0|64@1+ (1,0) [0|0] "" Vector__XXX

BO_ 1945 Debug8_BPMU_Chassi: 8 BPMU
 SG_ Debug_8_BPMU : 0|64@1+ (1,0) [0|0] "" Vector__XXX

BO_ 1948 Debug8_APM_Chassi: 8 APM
 SG_ Debug_8_APM : 0|64@1+ (1,0) [0|0] "" Vector__XXX

BO_ 1942 Debug7_RCIOM_Chassi: 8 RCIOM
 SG_ Debug_7_RCIOM : 0|64@1+ (1,0) [0|0] "" Vector__XXX

BO_ 1944 Debug7_FAS_Chassi: 8 Vector__XXX
 SG_ Debug_7_FAS : 0|64@1+ (1,0) [0|0] ""  FAS

BO_ 1941 Debug7_CCIOM_Chassi: 8 CCIOM
 SG_ Debug_7_CCIOM : 0|64@1+ (1,0) [0|0] "" Vector__XXX

BO_ 1940 Debug7_BPMU_Chassi: 8 BPMU
 SG_ Debug_7_BPMU : 0|64@1+ (1,0) [0|0] "" Vector__XXX

BO_ 1943 Debug7_APM_Chassi: 8 APM
 SG_ Debug_7_APM : 0|64@1+ (1,0) [0|0] "" Vector__XXX

BO_ 1937 Debug6_TPM_Chassi: 8 TPM
 SG_ Debug_6_TPM : 0|64@1+ (1,0) [0|0] "" Vector__XXX

BO_ 1935 Debug6_RCIOM_Chassi: 8 RCIOM
 SG_ Debug_6_RCIOM : 0|64@1+ (1,0) [0|0] "" Vector__XXX

CM_ SG_ 1367 FasUsrDefStiffnessCurveSetting_I "21-29 spare
30 Error
31 NotAvailbale";
CM_ SG_ 1367 FasUsrDefLowSpeedReturnSetting_I "21-29 spare
30 Error
31 NotAvailbale";
CM_ SG_ 1367 FasUsrDefStiffStraightSetting_IS "21-29 spare
30 Error
31 NotAvailbale";
CM_ SG_ 1367 FasUsrDefinedDampingSetting_ISig "21-29 spare
30 Error
31 NotAvailbale";
CM_ SG_ 1501 Trailer2TireInfoISO_Leakage_ISig "64256-65023 Spare; 65024-65279 Error; 65280-65535 NotAvailable;";
CM_ SG_ 1501 Trailer2TireInfoISO_Pressure_ISi "251-253 Spare; 254 Error; 255 NotAvailable;";
CM_ SG_ 1501 Trailer2TireInfoISO_Temperature_ "64256-65023 Spare; 65024-65279 Error; 65280-65535 NotAvailable;";
CM_ SG_ 1498 Trailer1TireInfoISO_Leakage_ISig "64256-65023 Spare; 65024-65279 Error; 65280-65535 NotAvailable;";
CM_ SG_ 1498 Trailer1TireInfoISO_Pressure_ISi "251-253 Spare; 254 Error; 255 NotAvailable;";
CM_ SG_ 1498 Trailer1TireInfoISO_Temperature_ "64256-65023 Spare; 65024-65279 Error; 65280-65535 NotAvailable;";
CM_ SG_ 395 ActualTagWheelAngle "65024 - 65279 Error ; 65280 - 65535 Not Available";
CM_ SG_ 395 ActualPusherWheelAngle "65024 - 65279 Error ; 65280 - 65535 Not Available";
CM_ SG_ 395 SteeringWheelAngle_ISig_6 "65024 - 65279 Error ; 65280 - 65535 Not available";
CM_ SG_ 394 ScndRrDriveAxleRightWheelSpeed "65024 - 65279 Error ; 65280 - 65535 Not available";
CM_ SG_ 394 ScndFrAxleLeftWheelSpeed "65024 - 65279 Error ; 65280 - 65535 Not available";
CM_ SG_ 394 ScndFrAxleRightWheelSpeed "65024 - 65279 Error ; 65280 - 65535 Not available";
CM_ SG_ 394 ScndRrDriveAxleLeftWheelSpeed "65024 - 65279 Error ; 65280 - 65535 Not available";
CM_ SG_ 391 PusherAxleRightWheelSpeed "65024 - 65279 Error ; 65280 - 65535 Not available";
CM_ SG_ 391 TagAxleRightWheelSpeed "65024 - 65279 Error ; 65280 - 65535 Not available";
CM_ SG_ 391 TagAxleLeftWheelSpeed "65024 - 65279 Error ; 65280 - 65535 Not available";
CM_ SG_ 391 PusherAxleLeftWheelSpeed "65024 - 65279 Error ; 65280 - 65535 Not available";
CM_ SG_ 386 LongitudinalAcceleration_ISig_6 "65024 - 65279 Error ; 65280 - 65535 Not available";
CM_ SG_ 386 YawRate_ISig_6 "65024 - 65279 Error ; 65280 - 65535 Not available";
CM_ SG_ 386 LateralAcceleration_ISig_6 "65024 - 65279 Error ; 65280 - 65535 Not available";
CM_ SG_ 386 EBSBrakePedalPosition "254 Error ; 255 Not available";
CM_ SG_ 824 TrailersConnected_ISig_6 "6 Error ; 7 Not available";
CM_ SG_ 824 TrailerControlPressure "254 Error ; 255 Not available";
CM_ SG_ 529 RrAxle3LtWhlBrakeApplPrsHiRng "254 Error ; 255 Not available";
CM_ SG_ 529 RrAxle1LtWhlBrakeApplPrsHiRng "254 Error ; 255 Not available";
CM_ SG_ 529 FrAxleLtWhlBrakeApplPrsHiRng "254 Error ; 255 Not available";
CM_ SG_ 529 RrAxle1RtWhlBrakeApplPrsHiRng "254 Error ; 255 Not available";
CM_ SG_ 529 RrAxle3RtWhlBrakeApplPrsHiRng "254 Error ; 255 Not available";
CM_ SG_ 529 RrAxle2LtWhlBrakeApplPrsHiRng "254 Error ; 255 Not available";
CM_ SG_ 529 FrAxleRtWhlBrakeApplPrsHiRng "254 Error ; 255 Not available";
CM_ SG_ 529 RrAxle2RtWhlBrakeApplPrsHiRng "254 Error ; 255 Not available";
BA_DEF_ BO_  "GenMsgStartDelayTime" INT 0 0;
BA_DEF_ BO_  "GenMsgDelayTime" INT 0 0;
BA_DEF_ BO_  "GenMsgCycleTime" INT 0 0;
BA_DEF_ BO_  "GenMsgSendType" ENUM  "Cyclic","NotUsed","NotUsed","NotUsed","NotUsed","NotUsed","NotUsed","IfActive","NoMsgSendType","NotUsed";
BA_DEF_ SG_  "GenSigStartValue" INT 0 0;
BA_DEF_ SG_  "GenSigInactiveValue" INT 0 0;
BA_DEF_ SG_  "GenSigCycleTimeActive" INT 0 0;
BA_DEF_ SG_  "GenSigCycleTime" INT 0 0;
BA_DEF_ SG_  "GenSigSendType" ENUM  "Cyclic","OnWrite","OnWriteWithRepetition","OnChange","OnChangeWithRepetition","IfActive","IfActiveWithRepetition","NoSigSendType","NotUsed","NotUsed","NotUsed","NotUsed","NotUsed";
BA_DEF_ BO_  "VFrameFormat" ENUM  "StandardCAN","ExtendedCAN","reserved","J1939PG";
BA_DEF_ SG_  "SigType" ENUM  "Default","Range","RangeSigned","ASCII","Discrete","Control","ReferencePGN","DTC","StringDelimiter","StringLength","StringLengthControl";
BA_DEF_ SG_  "SeToolVersion_SIGNAL" STRING ;
BA_DEF_ SG_  "SeToolUniqueID_SIGNAL" STRING ;
BA_DEF_ SG_  "SeToolName_SIGNAL" STRING ;
BA_DEF_ SG_  "SeToolItemID_SIGNAL" STRING ;
BA_DEF_ SG_  "SeToolAncestorID_SIGNAL" STRING ;
BA_DEF_ SG_  "Platform_VMCU1_Sig" ENUM  "No","Yes";
BA_DEF_ BO_  "NmAsrMessage" ENUM  "No","Yes";
BA_DEF_ SG_  "NeedsUpdateBit" ENUM  "No","Yes";
BA_DEF_ SG_  "MmAnSignal" ENUM  "No","Yes";
BA_DEF_ SG_  "GenSigMaxLatency" INT 0 65535;
BA_DEF_ SG_  "GenSigILSupport" ENUM  "Yes","No";
BA_DEF_ BO_  "GenMsgRequestable" INT 0 1;
BA_DEF_ BO_  "GenMsgILSupport" ENUM  "No","Yes";
BA_DEF_ BO_  "DiagUUDTResponse" ENUM  "No","Yes";
BA_DEF_ BO_  "DiagState" ENUM  "No","Yes";
BA_DEF_ BO_  "DiagResponse" ENUM  "No","Yes";
BA_DEF_ BO_  "DiagRequest" ENUM  "No","Yes";
BA_DEF_ BO_  "DiagConnection" HEX 0 65535;
BA_DEF_ BO_  "CanTpFcFrameId" HEX 0 2147483647;
BA_DEF_ BO_  "CanTpBs" INT 0 255;
BA_DEF_ SG_  "SystemSignalLongSymbol" STRING ;
BA_DEF_REL_ BU_SG_REL_  "GenSigTimeoutTime" INT 0 65535;
BA_DEF_REL_ BU_SG_REL_  "GenSigFirstTimeoutTime" INT 0 65535;
BA_DEF_DEF_  "GenMsgStartDelayTime" 0;
BA_DEF_DEF_  "GenMsgDelayTime" 0;
BA_DEF_DEF_  "GenMsgCycleTime" 0;
BA_DEF_DEF_  "GenMsgSendType" "Cyclic";
BA_DEF_DEF_  "GenSigStartValue" 0;
BA_DEF_DEF_  "GenSigInactiveValue" 0;
BA_DEF_DEF_  "GenSigCycleTimeActive" 0;
BA_DEF_DEF_  "GenSigCycleTime" 0;
BA_DEF_DEF_  "GenSigSendType" "Cyclic";
BA_DEF_DEF_  "VFrameFormat" "ExtendedCAN";
BA_DEF_DEF_  "SigType" "Default";
BA_DEF_DEF_  "SeToolVersion_SIGNAL" "";
BA_DEF_DEF_  "SeToolUniqueID_SIGNAL" "";
BA_DEF_DEF_  "SeToolName_SIGNAL" "";
BA_DEF_DEF_  "SeToolItemID_SIGNAL" "";
BA_DEF_DEF_  "SeToolAncestorID_SIGNAL" "";
BA_DEF_DEF_  "Platform_VMCU1_Sig" "No";
BA_DEF_DEF_  "NmAsrMessage" "No";
BA_DEF_DEF_  "NeedsUpdateBit" "No";
BA_DEF_DEF_  "MmAnSignal" "No";
BA_DEF_DEF_  "GenSigMaxLatency" 0;
BA_DEF_DEF_  "GenSigILSupport" "Yes";
BA_DEF_DEF_  "GenMsgRequestable" 1;
BA_DEF_DEF_  "GenMsgILSupport" "Yes";
BA_DEF_DEF_  "DiagUUDTResponse" "No";
BA_DEF_DEF_  "DiagState" "No";
BA_DEF_DEF_  "DiagResponse" "No";
BA_DEF_DEF_  "DiagRequest" "No";
BA_DEF_DEF_  "DiagConnection" 0;
BA_DEF_DEF_  "CanTpFcFrameId" 2147483647;
BA_DEF_DEF_  "CanTpBs" 255;
BA_DEF_DEF_REL_ "GenSigTimeoutTime" 0;
BA_DEF_DEF_REL_ "GenSigFirstTimeoutTime" 0;
BA_DEF_DEF_  "SystemSignalLongSymbol" "";
BA_ "VFrameFormat" BO_ 952 0;
BA_ "GenMsgCycleTime" BO_ 952 50;
BA_ "GenMsgStartDelayTime" BO_ 952 10;
BA_ "VFrameFormat" BO_ 1367 0;
BA_ "GenMsgCycleTime" BO_ 1367 1000;
BA_ "GenMsgStartDelayTime" BO_ 1367 50;
BA_ "VFrameFormat" BO_ 520 0;
BA_ "GenMsgCycleTime" BO_ 520 20;
BA_ "GenMsgStartDelayTime" BO_ 520 10;
BA_ "VFrameFormat" BO_ 1232 0;
BA_ "GenMsgCycleTime" BO_ 1232 100;
BA_ "VFrameFormat" BO_ 1507 0;
BA_ "GenMsgCycleTime" BO_ 1507 1000;
BA_ "GenMsgStartDelayTime" BO_ 1507 100;
BA_ "VFrameFormat" BO_ 1504 0;
BA_ "GenMsgCycleTime" BO_ 1504 1000;
BA_ "GenMsgStartDelayTime" BO_ 1504 85;
BA_ "VFrameFormat" BO_ 1501 0;
BA_ "GenMsgCycleTime" BO_ 1501 1000;
BA_ "GenMsgStartDelayTime" BO_ 1501 65;
BA_ "VFrameFormat" BO_ 1498 0;
BA_ "GenMsgCycleTime" BO_ 1498 1000;
BA_ "GenMsgStartDelayTime" BO_ 1498 45;
BA_ "VFrameFormat" BO_ 396 0;
BA_ "GenMsgCycleTime" BO_ 396 10;
BA_ "VFrameFormat" BO_ 395 0;
BA_ "GenMsgCycleTime" BO_ 395 10;
BA_ "GenMsgStartDelayTime" BO_ 395 5;
BA_ "VFrameFormat" BO_ 394 0;
BA_ "GenMsgCycleTime" BO_ 394 10;
BA_ "VFrameFormat" BO_ 391 0;
BA_ "GenMsgCycleTime" BO_ 391 10;
BA_ "GenMsgStartDelayTime" BO_ 391 5;
BA_ "VFrameFormat" BO_ 386 0;
BA_ "GenMsgCycleTime" BO_ 386 10;
BA_ "VFrameFormat" BO_ 824 0;
BA_ "GenMsgCycleTime" BO_ 824 30;
BA_ "VFrameFormat" BO_ 529 0;
BA_ "GenMsgCycleTime" BO_ 529 20;
BA_ "GenMsgStartDelayTime" BO_ 529 15;
BA_ "VFrameFormat" BO_ 516 0;
BA_ "GenMsgCycleTime" BO_ 516 20;
BA_ "DiagConnection" BO_ 2672226850 61986;
BA_ "DiagUUDTResponse" BO_ 2672226850 1;
BA_ "GenMsgILSupport" BO_ 2672226850 0;
BA_ "GenMsgSendType" BO_ 2672226850 8;
BA_ "DiagConnection" BO_ 2672226848 61984;
BA_ "DiagUUDTResponse" BO_ 2672226848 1;
BA_ "GenMsgILSupport" BO_ 2672226848 0;
BA_ "GenMsgSendType" BO_ 2672226848 8;
BA_ "DiagConnection" BO_ 2672161314 61986;
BA_ "DiagUUDTResponse" BO_ 2672161314 1;
BA_ "GenMsgILSupport" BO_ 2672161314 0;
BA_ "GenMsgSendType" BO_ 2672161314 8;
BA_ "DiagConnection" BO_ 2672161312 61984;
BA_ "DiagUUDTResponse" BO_ 2672161312 1;
BA_ "GenMsgILSupport" BO_ 2672161312 0;
BA_ "GenMsgSendType" BO_ 2672161312 8;
BA_ "DiagConnection" BO_ 2672095778 61986;
BA_ "DiagUUDTResponse" BO_ 2672095778 1;
BA_ "GenMsgILSupport" BO_ 2672095778 0;
BA_ "GenMsgSendType" BO_ 2672095778 8;
BA_ "DiagConnection" BO_ 2672095776 61984;
BA_ "DiagUUDTResponse" BO_ 2672095776 1;
BA_ "GenMsgILSupport" BO_ 2672095776 0;
BA_ "GenMsgSendType" BO_ 2672095776 8;
BA_ "DiagConnection" BO_ 2672030242 61986;
BA_ "DiagUUDTResponse" BO_ 2672030242 1;
BA_ "GenMsgILSupport" BO_ 2672030242 0;
BA_ "GenMsgSendType" BO_ 2672030242 8;
BA_ "DiagConnection" BO_ 2672030240 61984;
BA_ "DiagUUDTResponse" BO_ 2672030240 1;
BA_ "GenMsgILSupport" BO_ 2672030240 0;
BA_ "GenMsgSendType" BO_ 2672030240 8;
BA_ "DiagConnection" BO_ 2671964786 62066;
BA_ "DiagUUDTResponse" BO_ 2671964786 1;
BA_ "GenMsgILSupport" BO_ 2671964786 0;
BA_ "GenMsgSendType" BO_ 2671964786 8;
BA_ "DiagConnection" BO_ 2671964785 62065;
BA_ "DiagUUDTResponse" BO_ 2671964785 1;
BA_ "GenMsgILSupport" BO_ 2671964785 0;
BA_ "GenMsgSendType" BO_ 2671964785 8;
BA_ "DiagConnection" BO_ 2671964721 62001;
BA_ "DiagUUDTResponse" BO_ 2671964721 1;
BA_ "GenMsgILSupport" BO_ 2671964721 0;
BA_ "GenMsgSendType" BO_ 2671964721 8;
BA_ "DiagConnection" BO_ 2671964720 62000;
BA_ "DiagUUDTResponse" BO_ 2671964720 1;
BA_ "GenMsgILSupport" BO_ 2671964720 0;
BA_ "GenMsgSendType" BO_ 2671964720 8;
BA_ "DiagConnection" BO_ 2671964709 61989;
BA_ "DiagUUDTResponse" BO_ 2671964709 1;
BA_ "GenMsgILSupport" BO_ 2671964709 0;
BA_ "GenMsgSendType" BO_ 2671964709 8;
BA_ "DiagConnection" BO_ 2671964707 61987;
BA_ "DiagUUDTResponse" BO_ 2671964707 1;
BA_ "GenMsgILSupport" BO_ 2671964707 0;
BA_ "GenMsgSendType" BO_ 2671964707 8;
BA_ "DiagConnection" BO_ 2671964706 61986;
BA_ "DiagUUDTResponse" BO_ 2671964706 1;
BA_ "GenMsgILSupport" BO_ 2671964706 0;
BA_ "GenMsgSendType" BO_ 2671964706 8;
BA_ "DiagConnection" BO_ 2671964705 61985;
BA_ "DiagUUDTResponse" BO_ 2671964705 1;
BA_ "GenMsgILSupport" BO_ 2671964705 0;
BA_ "GenMsgSendType" BO_ 2671964705 8;
BA_ "DiagConnection" BO_ 2671964704 61984;
BA_ "DiagUUDTResponse" BO_ 2671964704 1;
BA_ "GenMsgILSupport" BO_ 2671964704 0;
BA_ "GenMsgSendType" BO_ 2671964704 8;
BA_ "DiagConnection" BO_ 2671964698 61978;
BA_ "DiagUUDTResponse" BO_ 2671964698 1;
BA_ "GenMsgILSupport" BO_ 2671964698 0;
BA_ "GenMsgSendType" BO_ 2671964698 8;
BA_ "DiagConnection" BO_ 2671834226 62578;
BA_ "DiagResponse" BO_ 2671834226 1;
BA_ "GenMsgILSupport" BO_ 2671834226 0;
BA_ "GenMsgSendType" BO_ 2671834226 8;
BA_ "DiagConnection" BO_ 2671834225 62577;
BA_ "DiagResponse" BO_ 2671834225 1;
BA_ "GenMsgILSupport" BO_ 2671834225 0;
BA_ "GenMsgSendType" BO_ 2671834225 8;
BA_ "DiagConnection" BO_ 2671834161 62513;
BA_ "DiagResponse" BO_ 2671834161 1;
BA_ "GenMsgILSupport" BO_ 2671834161 0;
BA_ "GenMsgSendType" BO_ 2671834161 8;
BA_ "DiagConnection" BO_ 2671834160 62512;
BA_ "DiagResponse" BO_ 2671834160 1;
BA_ "GenMsgILSupport" BO_ 2671834160 0;
BA_ "GenMsgSendType" BO_ 2671834160 8;
BA_ "DiagConnection" BO_ 2671834149 62501;
BA_ "DiagResponse" BO_ 2671834149 1;
BA_ "GenMsgILSupport" BO_ 2671834149 0;
BA_ "GenMsgSendType" BO_ 2671834149 8;
BA_ "DiagConnection" BO_ 2671834147 62499;
BA_ "DiagResponse" BO_ 2671834147 1;
BA_ "GenMsgILSupport" BO_ 2671834147 0;
BA_ "GenMsgSendType" BO_ 2671834147 8;
BA_ "DiagConnection" BO_ 2671834146 62498;
BA_ "DiagResponse" BO_ 2671834146 1;
BA_ "GenMsgILSupport" BO_ 2671834146 0;
BA_ "GenMsgSendType" BO_ 2671834146 8;
BA_ "DiagConnection" BO_ 2671834145 62497;
BA_ "DiagResponse" BO_ 2671834145 1;
BA_ "GenMsgILSupport" BO_ 2671834145 0;
BA_ "GenMsgSendType" BO_ 2671834145 8;
BA_ "DiagConnection" BO_ 2671834144 62496;
BA_ "DiagResponse" BO_ 2671834144 1;
BA_ "GenMsgILSupport" BO_ 2671834144 0;
BA_ "GenMsgSendType" BO_ 2671834144 8;
BA_ "DiagConnection" BO_ 2671834138 62490;
BA_ "DiagResponse" BO_ 2671834138 1;
BA_ "GenMsgILSupport" BO_ 2671834138 0;
BA_ "GenMsgSendType" BO_ 2671834138 8;
BA_ "DiagConnection" BO_ 2671833970 62322;
BA_ "DiagResponse" BO_ 2671833970 1;
BA_ "GenMsgILSupport" BO_ 2671833970 0;
BA_ "GenMsgSendType" BO_ 2671833970 8;
BA_ "DiagConnection" BO_ 2671833969 62321;
BA_ "DiagResponse" BO_ 2671833969 1;
BA_ "GenMsgILSupport" BO_ 2671833969 0;
BA_ "GenMsgSendType" BO_ 2671833969 8;
BA_ "DiagConnection" BO_ 2671833905 62257;
BA_ "DiagResponse" BO_ 2671833905 1;
BA_ "GenMsgILSupport" BO_ 2671833905 0;
BA_ "GenMsgSendType" BO_ 2671833905 8;
BA_ "DiagConnection" BO_ 2671833904 62256;
BA_ "DiagResponse" BO_ 2671833904 1;
BA_ "GenMsgILSupport" BO_ 2671833904 0;
BA_ "GenMsgSendType" BO_ 2671833904 8;
BA_ "DiagConnection" BO_ 2671833893 62245;
BA_ "DiagResponse" BO_ 2671833893 1;
BA_ "GenMsgILSupport" BO_ 2671833893 0;
BA_ "GenMsgSendType" BO_ 2671833893 8;
BA_ "DiagConnection" BO_ 2671833891 62243;
BA_ "DiagResponse" BO_ 2671833891 1;
BA_ "GenMsgILSupport" BO_ 2671833891 0;
BA_ "GenMsgSendType" BO_ 2671833891 8;
BA_ "DiagConnection" BO_ 2671833890 62242;
BA_ "DiagResponse" BO_ 2671833890 1;
BA_ "GenMsgILSupport" BO_ 2671833890 0;
BA_ "GenMsgSendType" BO_ 2671833890 8;
BA_ "DiagConnection" BO_ 2671833889 62241;
BA_ "DiagResponse" BO_ 2671833889 1;
BA_ "GenMsgILSupport" BO_ 2671833889 0;
BA_ "GenMsgSendType" BO_ 2671833889 8;
BA_ "DiagConnection" BO_ 2671833888 62240;
BA_ "DiagResponse" BO_ 2671833888 1;
BA_ "GenMsgILSupport" BO_ 2671833888 0;
BA_ "GenMsgSendType" BO_ 2671833888 8;
BA_ "DiagConnection" BO_ 2671833882 62234;
BA_ "DiagResponse" BO_ 2671833882 1;
BA_ "GenMsgILSupport" BO_ 2671833882 0;
BA_ "GenMsgSendType" BO_ 2671833882 8;
BA_ "DiagConnection" BO_ 2671801076 62578;
BA_ "DiagRequest" BO_ 2671801076 1;
BA_ "GenMsgILSupport" BO_ 2671801076 0;
BA_ "GenMsgSendType" BO_ 2671801076 8;
BA_ "DiagConnection" BO_ 2671800820 62577;
BA_ "DiagRequest" BO_ 2671800820 1;
BA_ "GenMsgILSupport" BO_ 2671800820 0;
BA_ "GenMsgSendType" BO_ 2671800820 8;
BA_ "DiagConnection" BO_ 2671784436 62513;
BA_ "DiagRequest" BO_ 2671784436 1;
BA_ "GenMsgILSupport" BO_ 2671784436 0;
BA_ "GenMsgSendType" BO_ 2671784436 8;
BA_ "DiagConnection" BO_ 2671784180 62512;
BA_ "DiagRequest" BO_ 2671784180 1;
BA_ "GenMsgILSupport" BO_ 2671784180 0;
BA_ "GenMsgSendType" BO_ 2671784180 8;
BA_ "DiagConnection" BO_ 2671781364 62501;
BA_ "DiagRequest" BO_ 2671781364 1;
BA_ "GenMsgILSupport" BO_ 2671781364 0;
BA_ "GenMsgSendType" BO_ 2671781364 8;
BA_ "DiagConnection" BO_ 2671780852 62499;
BA_ "DiagRequest" BO_ 2671780852 1;
BA_ "GenMsgILSupport" BO_ 2671780852 0;
BA_ "GenMsgSendType" BO_ 2671780852 8;
BA_ "DiagConnection" BO_ 2671780596 62498;
BA_ "DiagRequest" BO_ 2671780596 1;
BA_ "GenMsgILSupport" BO_ 2671780596 0;
BA_ "GenMsgSendType" BO_ 2671780596 8;
BA_ "DiagConnection" BO_ 2671780340 62497;
BA_ "DiagRequest" BO_ 2671780340 1;
BA_ "GenMsgILSupport" BO_ 2671780340 0;
BA_ "GenMsgSendType" BO_ 2671780340 8;
BA_ "DiagConnection" BO_ 2671780084 62496;
BA_ "DiagRequest" BO_ 2671780084 1;
BA_ "GenMsgILSupport" BO_ 2671780084 0;
BA_ "GenMsgSendType" BO_ 2671780084 8;
BA_ "DiagConnection" BO_ 2671778548 62490;
BA_ "DiagRequest" BO_ 2671778548 1;
BA_ "GenMsgILSupport" BO_ 2671778548 0;
BA_ "GenMsgSendType" BO_ 2671778548 8;
BA_ "DiagConnection" BO_ 2671801075 62322;
BA_ "DiagRequest" BO_ 2671801075 1;
BA_ "GenMsgILSupport" BO_ 2671801075 0;
BA_ "GenMsgSendType" BO_ 2671801075 8;
BA_ "DiagConnection" BO_ 2671800819 62321;
BA_ "DiagRequest" BO_ 2671800819 1;
BA_ "GenMsgILSupport" BO_ 2671800819 0;
BA_ "GenMsgSendType" BO_ 2671800819 8;
BA_ "DiagConnection" BO_ 2671784435 62257;
BA_ "DiagRequest" BO_ 2671784435 1;
BA_ "GenMsgILSupport" BO_ 2671784435 0;
BA_ "GenMsgSendType" BO_ 2671784435 8;
BA_ "DiagConnection" BO_ 2671784179 62256;
BA_ "DiagRequest" BO_ 2671784179 1;
BA_ "GenMsgILSupport" BO_ 2671784179 0;
BA_ "GenMsgSendType" BO_ 2671784179 8;
BA_ "DiagConnection" BO_ 2671781363 62245;
BA_ "DiagRequest" BO_ 2671781363 1;
BA_ "GenMsgILSupport" BO_ 2671781363 0;
BA_ "GenMsgSendType" BO_ 2671781363 8;
BA_ "DiagConnection" BO_ 2671780851 62243;
BA_ "DiagRequest" BO_ 2671780851 1;
BA_ "GenMsgILSupport" BO_ 2671780851 0;
BA_ "GenMsgSendType" BO_ 2671780851 8;
BA_ "DiagConnection" BO_ 2671780595 62242;
BA_ "DiagRequest" BO_ 2671780595 1;
BA_ "GenMsgILSupport" BO_ 2671780595 0;
BA_ "GenMsgSendType" BO_ 2671780595 8;
BA_ "DiagConnection" BO_ 2671780339 62241;
BA_ "DiagRequest" BO_ 2671780339 1;
BA_ "GenMsgILSupport" BO_ 2671780339 0;
BA_ "GenMsgSendType" BO_ 2671780339 8;
BA_ "DiagConnection" BO_ 2671780083 62240;
BA_ "DiagRequest" BO_ 2671780083 1;
BA_ "GenMsgILSupport" BO_ 2671780083 0;
BA_ "GenMsgSendType" BO_ 2671780083 8;
BA_ "DiagConnection" BO_ 2671778547 62234;
BA_ "DiagRequest" BO_ 2671778547 1;
BA_ "GenMsgILSupport" BO_ 2671778547 0;
BA_ "GenMsgSendType" BO_ 2671778547 8;
BA_ "VFrameFormat" BO_ 1502 0;
BA_ "GenMsgCycleTime" BO_ 1502 1000;
BA_ "GenMsgDelayTime" BO_ 1502 90;
BA_ "VFrameFormat" BO_ 1500 0;
BA_ "GenMsgCycleTime" BO_ 1500 1000;
BA_ "GenMsgDelayTime" BO_ 1500 90;
BA_ "GenMsgStartDelayTime" BO_ 1500 5;
BA_ "VFrameFormat" BO_ 1497 0;
BA_ "GenMsgSendType" BO_ 1497 8;
BA_ "GenMsgDelayTime" BO_ 1497 80;
BA_ "VFrameFormat" BO_ 1496 0;
BA_ "GenMsgSendType" BO_ 1496 8;
BA_ "GenMsgDelayTime" BO_ 1496 80;
BA_ "VFrameFormat" BO_ 1499 0;
BA_ "GenMsgCycleTime" BO_ 1499 1000;
BA_ "GenMsgDelayTime" BO_ 1499 90;
BA_ "VFrameFormat" BO_ 1491 0;
BA_ "GenMsgCycleTime" BO_ 1491 1000;
BA_ "GenMsgDelayTime" BO_ 1491 90;
BA_ "VFrameFormat" BO_ 1493 0;
BA_ "GenMsgCycleTime" BO_ 1493 1000;
BA_ "GenMsgDelayTime" BO_ 1493 90;
BA_ "GenMsgStartDelayTime" BO_ 1493 10;
BA_ "VFrameFormat" BO_ 1490 0;
BA_ "GenMsgCycleTime" BO_ 1490 1000;
BA_ "GenMsgDelayTime" BO_ 1490 95;
BA_ "GenMsgStartDelayTime" BO_ 1490 20;
BA_ "VFrameFormat" BO_ 1494 0;
BA_ "GenMsgCycleTime" BO_ 1494 1000;
BA_ "GenMsgDelayTime" BO_ 1494 90;
BA_ "GenMsgStartDelayTime" BO_ 1494 10;
BA_ "VFrameFormat" BO_ 1489 0;
BA_ "GenMsgCycleTime" BO_ 1489 1000;
BA_ "GenMsgDelayTime" BO_ 1489 85;
BA_ "GenMsgStartDelayTime" BO_ 1489 30;
BA_ "VFrameFormat" BO_ 1952 0;
BA_ "GenMsgSendType" BO_ 1952 8;
BA_ "GenMsgDelayTime" BO_ 1952 50;
BA_ "GenMsgStartDelayTime" BO_ 1952 50;
BA_ "VFrameFormat" BO_ 1954 0;
BA_ "GenMsgSendType" BO_ 1954 8;
BA_ "VFrameFormat" BO_ 1951 0;
BA_ "GenMsgSendType" BO_ 1951 8;
BA_ "GenMsgDelayTime" BO_ 1951 50;
BA_ "GenMsgStartDelayTime" BO_ 1951 50;
BA_ "VFrameFormat" BO_ 1950 0;
BA_ "GenMsgSendType" BO_ 1950 8;
BA_ "VFrameFormat" BO_ 1953 0;
BA_ "GenMsgSendType" BO_ 1953 8;
BA_ "GenMsgDelayTime" BO_ 1953 50;
BA_ "GenMsgStartDelayTime" BO_ 1953 50;
BA_ "VFrameFormat" BO_ 1947 0;
BA_ "GenMsgSendType" BO_ 1947 8;
BA_ "GenMsgDelayTime" BO_ 1947 50;
BA_ "GenMsgStartDelayTime" BO_ 1947 50;
BA_ "VFrameFormat" BO_ 1949 0;
BA_ "VFrameFormat" BO_ 1946 0;
BA_ "GenMsgSendType" BO_ 1946 8;
BA_ "GenMsgDelayTime" BO_ 1946 50;
BA_ "GenMsgStartDelayTime" BO_ 1946 50;
BA_ "VFrameFormat" BO_ 1945 0;
BA_ "GenMsgSendType" BO_ 1945 8;
BA_ "VFrameFormat" BO_ 1948 0;
BA_ "GenMsgSendType" BO_ 1948 8;
BA_ "GenMsgDelayTime" BO_ 1948 50;
BA_ "GenMsgStartDelayTime" BO_ 1948 50;
BA_ "VFrameFormat" BO_ 1942 0;
BA_ "GenMsgSendType" BO_ 1942 8;
BA_ "GenMsgDelayTime" BO_ 1942 50;
BA_ "GenMsgStartDelayTime" BO_ 1942 50;
BA_ "VFrameFormat" BO_ 1944 0;
BA_ "VFrameFormat" BO_ 1941 0;
BA_ "GenMsgSendType" BO_ 1941 8;
BA_ "GenMsgDelayTime" BO_ 1941 50;
BA_ "GenMsgStartDelayTime" BO_ 1941 50;
BA_ "VFrameFormat" BO_ 1940 0;
BA_ "GenMsgSendType" BO_ 1940 8;
BA_ "VFrameFormat" BO_ 1943 0;
BA_ "GenMsgSendType" BO_ 1943 8;
BA_ "GenMsgDelayTime" BO_ 1943 50;
BA_ "GenMsgStartDelayTime" BO_ 1943 50;
BA_ "VFrameFormat" BO_ 1937 0;
BA_ "GenMsgSendType" BO_ 1937 8;
BA_ "GenMsgDelayTime" BO_ 1937 50;
BA_ "GenMsgStartDelayTime" BO_ 1937 50;
BA_ "VFrameFormat" BO_ 1935 0;
BA_ "GenMsgSendType" BO_ 1935 8;
BA_ "GenMsgDelayTime" BO_ 1935 50;
BA_ "GenMsgStartDelayTime" BO_ 1935 50;
BA_ "GenSigCycleTime" SG_ 952 DirIndSideLamp1_stat 100;
BA_ "GenSigCycleTimeActive" SG_ 952 DirIndSideLamp1_stat 100;
BA_ "GenSigStartValue" SG_ 952 DirIndSideLamp1_stat 7;
BA_ "Platform_VMCU1_Sig" SG_ 952 DirIndSideLamp1_stat 1;
BA_ "GenSigCycleTime" SG_ 952 MainBeamLamp_stat_ISig_6 100;
BA_ "GenSigCycleTimeActive" SG_ 952 MainBeamLamp_stat_ISig_6 100;
BA_ "GenSigStartValue" SG_ 952 MainBeamLamp_stat_ISig_6 7;
BA_ "GenSigCycleTime" SG_ 952 FogLamp_Front_Status 100;
BA_ "GenSigCycleTimeActive" SG_ 952 FogLamp_Front_Status 100;
BA_ "GenSigStartValue" SG_ 952 FogLamp_Front_Status 3;
BA_ "GenSigMaxLatency" SG_ 952 FogLamp_Front_Status 59;
BA_ "Platform_VMCU1_Sig" SG_ 952 FogLamp_Front_Status 1;
BA_ "SeToolAncestorID_SIGNAL" SG_ 952 FogLamp_Front_Status "x0000001D04166FE4";
BA_ "SeToolItemID_SIGNAL" SG_ 952 FogLamp_Front_Status "x0000001D042E381B";
BA_ "SeToolName_SIGNAL" SG_ 952 FogLamp_Front_Status "FogLamp_Front_Status";
BA_ "SeToolVersion_SIGNAL" SG_ 952 FogLamp_Front_Status "3";
BA_ "GenSigCycleTime" SG_ 952 DirInd_Front_Status_ISig_6 100;
BA_ "GenSigCycleTimeActive" SG_ 952 DirInd_Front_Status_ISig_6 100;
BA_ "GenSigStartValue" SG_ 952 DirInd_Front_Status_ISig_6 7;
BA_ "GenSigMaxLatency" SG_ 952 DirInd_Front_Status_ISig_6 59;
BA_ "Platform_VMCU1_Sig" SG_ 952 DirInd_Front_Status_ISig_6 1;
BA_ "SeToolAncestorID_SIGNAL" SG_ 952 DirInd_Front_Status_ISig_6 "x0000001D041661B2";
BA_ "SeToolItemID_SIGNAL" SG_ 952 DirInd_Front_Status_ISig_6 "x0000001D042DBCE4";
BA_ "SeToolName_SIGNAL" SG_ 952 DirInd_Front_Status_ISig_6 "DirInd_Front_Status";
BA_ "SeToolVersion_SIGNAL" SG_ 952 DirInd_Front_Status_ISig_6 "2";
BA_ "GenSigCycleTime" SG_ 952 AuxLamp_Front_Status 100;
BA_ "GenSigCycleTimeActive" SG_ 952 AuxLamp_Front_Status 100;
BA_ "GenSigStartValue" SG_ 952 AuxLamp_Front_Status 3;
BA_ "GenSigMaxLatency" SG_ 952 AuxLamp_Front_Status 59;
BA_ "Platform_VMCU1_Sig" SG_ 952 AuxLamp_Front_Status 1;
BA_ "SeToolAncestorID_SIGNAL" SG_ 952 AuxLamp_Front_Status "x0000001D04300536";
BA_ "SeToolItemID_SIGNAL" SG_ 952 AuxLamp_Front_Status "x0000001D04300536";
BA_ "SeToolName_SIGNAL" SG_ 952 AuxLamp_Front_Status "AuxLamp_Front_Status";
BA_ "SeToolVersion_SIGNAL" SG_ 952 AuxLamp_Front_Status "1";
BA_ "GenSigCycleTime" SG_ 952 WasherFluidLevel_ISig_6 100;
BA_ "GenSigCycleTimeActive" SG_ 952 WasherFluidLevel_ISig_6 100;
BA_ "GenSigStartValue" SG_ 952 WasherFluidLevel_ISig_6 7;
BA_ "GenSigMaxLatency" SG_ 952 WasherFluidLevel_ISig_6 59;
BA_ "Platform_VMCU1_Sig" SG_ 952 WasherFluidLevel_ISig_6 1;
BA_ "SeToolAncestorID_SIGNAL" SG_ 952 WasherFluidLevel_ISig_6 "x0000001D04104D03";
BA_ "SeToolItemID_SIGNAL" SG_ 952 WasherFluidLevel_ISig_6 "x0000001D0435D527";
BA_ "SeToolName_SIGNAL" SG_ 952 WasherFluidLevel_ISig_6 "WasherFluidLevel";
BA_ "SeToolVersion_SIGNAL" SG_ 952 WasherFluidLevel_ISig_6 "3";
BA_ "GenSigCycleTime" SG_ 952 StaticCornerLightLamp_stat_ISig_ 100;
BA_ "GenSigCycleTimeActive" SG_ 952 StaticCornerLightLamp_stat_ISig_ 100;
BA_ "GenSigInactiveValue" SG_ 952 StaticCornerLightLamp_stat_ISig_ 7;
BA_ "GenSigStartValue" SG_ 952 StaticCornerLightLamp_stat_ISig_ 7;
BA_ "GenSigMaxLatency" SG_ 952 StaticCornerLightLamp_stat_ISig_ 59;
BA_ "Platform_VMCU1_Sig" SG_ 952 StaticCornerLightLamp_stat_ISig_ 1;
BA_ "SystemSignalLongSymbol" SG_ 952 StaticCornerLightLamp_stat_ISig_ "StaticCornerLightLamp_stat_ISig_6";
BA_ "GenSigCycleTime" SG_ 952 DippedBeamLamp_stat_ISig_6 100;
BA_ "GenSigCycleTimeActive" SG_ 952 DippedBeamLamp_stat_ISig_6 100;
BA_ "GenSigInactiveValue" SG_ 952 DippedBeamLamp_stat_ISig_6 7;
BA_ "GenSigStartValue" SG_ 952 DippedBeamLamp_stat_ISig_6 7;
BA_ "GenSigMaxLatency" SG_ 952 DippedBeamLamp_stat_ISig_6 59;
BA_ "Platform_VMCU1_Sig" SG_ 952 DippedBeamLamp_stat_ISig_6 1;
BA_ "GenSigCycleTime" SG_ 952 ChassiInstepLightsLamp_stat_ISig 100;
BA_ "GenSigCycleTimeActive" SG_ 952 ChassiInstepLightsLamp_stat_ISig 100;
BA_ "GenSigInactiveValue" SG_ 952 ChassiInstepLightsLamp_stat_ISig 7;
BA_ "GenSigStartValue" SG_ 952 ChassiInstepLightsLamp_stat_ISig 7;
BA_ "GenSigMaxLatency" SG_ 952 ChassiInstepLightsLamp_stat_ISig 59;
BA_ "Platform_VMCU1_Sig" SG_ 952 ChassiInstepLightsLamp_stat_ISig 1;
BA_ "SystemSignalLongSymbol" SG_ 952 ChassiInstepLightsLamp_stat_ISig "ChassiInstepLightsLamp_stat_ISig_6";
BA_ "GenSigCycleTime" SG_ 952 ExtraMainBeamLamp_stat_ISig_6 100;
BA_ "GenSigCycleTimeActive" SG_ 952 ExtraMainBeamLamp_stat_ISig_6 100;
BA_ "GenSigInactiveValue" SG_ 952 ExtraMainBeamLamp_stat_ISig_6 7;
BA_ "GenSigStartValue" SG_ 952 ExtraMainBeamLamp_stat_ISig_6 7;
BA_ "GenSigMaxLatency" SG_ 952 ExtraMainBeamLamp_stat_ISig_6 59;
BA_ "Platform_VMCU1_Sig" SG_ 952 ExtraMainBeamLamp_stat_ISig_6 1;
BA_ "GenSigCycleTime" SG_ 952 AuxFogLightLamp_stat_ISig_6 100;
BA_ "GenSigCycleTimeActive" SG_ 952 AuxFogLightLamp_stat_ISig_6 100;
BA_ "GenSigInactiveValue" SG_ 952 AuxFogLightLamp_stat_ISig_6 7;
BA_ "GenSigStartValue" SG_ 952 AuxFogLightLamp_stat_ISig_6 7;
BA_ "GenSigMaxLatency" SG_ 952 AuxFogLightLamp_stat_ISig_6 59;
BA_ "Platform_VMCU1_Sig" SG_ 952 AuxFogLightLamp_stat_ISig_6 1;
BA_ "GenSigCycleTime" SG_ 952 PositionLightLamp_stat_ISig_6 100;
BA_ "GenSigCycleTimeActive" SG_ 952 PositionLightLamp_stat_ISig_6 100;
BA_ "GenSigInactiveValue" SG_ 952 PositionLightLamp_stat_ISig_6 7;
BA_ "GenSigStartValue" SG_ 952 PositionLightLamp_stat_ISig_6 7;
BA_ "GenSigMaxLatency" SG_ 952 PositionLightLamp_stat_ISig_6 59;
BA_ "Platform_VMCU1_Sig" SG_ 952 PositionLightLamp_stat_ISig_6 1;
BA_ "GenSigCycleTime" SG_ 952 AmbientAirTemperature1 100;
BA_ "GenSigCycleTimeActive" SG_ 952 AmbientAirTemperature1 100;
BA_ "GenSigStartValue" SG_ 952 AmbientAirTemperature1 65535;
BA_ "GenSigCycleTime" SG_ 952 FogLightFrontLamp_stat_ISig_6 100;
BA_ "GenSigCycleTimeActive" SG_ 952 FogLightFrontLamp_stat_ISig_6 100;
BA_ "GenSigInactiveValue" SG_ 952 FogLightFrontLamp_stat_ISig_6 7;
BA_ "GenSigStartValue" SG_ 952 FogLightFrontLamp_stat_ISig_6 7;
BA_ "GenSigMaxLatency" SG_ 952 FogLightFrontLamp_stat_ISig_6 59;
BA_ "Platform_VMCU1_Sig" SG_ 952 FogLightFrontLamp_stat_ISig_6 1;
BA_ "GenSigCycleTime" SG_ 952 DRLLamp_stat_ISig_6 100;
BA_ "GenSigCycleTimeActive" SG_ 952 DRLLamp_stat_ISig_6 100;
BA_ "GenSigInactiveValue" SG_ 952 DRLLamp_stat_ISig_6 7;
BA_ "GenSigStartValue" SG_ 952 DRLLamp_stat_ISig_6 7;
BA_ "GenSigMaxLatency" SG_ 952 DRLLamp_stat_ISig_6 59;
BA_ "Platform_VMCU1_Sig" SG_ 952 DRLLamp_stat_ISig_6 1;
BA_ "GenSigCycleTime" SG_ 1367 FasUsrDefStiffnessCurveSetting_I 100;
BA_ "GenSigCycleTimeActive" SG_ 1367 FasUsrDefStiffnessCurveSetting_I 100;
BA_ "GenSigStartValue" SG_ 1367 FasUsrDefStiffnessCurveSetting_I 31;
BA_ "GenSigMaxLatency" SG_ 1367 FasUsrDefStiffnessCurveSetting_I 999;
BA_ "SystemSignalLongSymbol" SG_ 1367 FasUsrDefStiffnessCurveSetting_I "FasUsrDefStiffnessCurveSetting_ISig_6";
BA_ "GenSigCycleTime" SG_ 1367 FasDriver_ISig_6 100;
BA_ "GenSigCycleTimeActive" SG_ 1367 FasDriver_ISig_6 100;
BA_ "GenSigStartValue" SG_ 1367 FasDriver_ISig_6 15;
BA_ "GenSigMaxLatency" SG_ 1367 FasDriver_ISig_6 999;
BA_ "GenSigCycleTime" SG_ 1367 FasUsrDefLowSpeedReturnSetting_I 100;
BA_ "GenSigCycleTimeActive" SG_ 1367 FasUsrDefLowSpeedReturnSetting_I 100;
BA_ "GenSigStartValue" SG_ 1367 FasUsrDefLowSpeedReturnSetting_I 31;
BA_ "GenSigMaxLatency" SG_ 1367 FasUsrDefLowSpeedReturnSetting_I 999;
BA_ "SystemSignalLongSymbol" SG_ 1367 FasUsrDefLowSpeedReturnSetting_I "FasUsrDefLowSpeedReturnSetting_ISig_6";
BA_ "GenSigCycleTime" SG_ 1367 ActualFasPersSettingsButton_ISig 100;
BA_ "GenSigCycleTimeActive" SG_ 1367 ActualFasPersSettingsButton_ISig 100;
BA_ "GenSigStartValue" SG_ 1367 ActualFasPersSettingsButton_ISig 7;
BA_ "GenSigMaxLatency" SG_ 1367 ActualFasPersSettingsButton_ISig 999;
BA_ "SystemSignalLongSymbol" SG_ 1367 ActualFasPersSettingsButton_ISig "ActualFasPersSettingsButton_ISig_6";
BA_ "GenSigCycleTime" SG_ 1367 FasUsrDefStiffStraightSetting_IS 100;
BA_ "GenSigCycleTimeActive" SG_ 1367 FasUsrDefStiffStraightSetting_IS 100;
BA_ "GenSigStartValue" SG_ 1367 FasUsrDefStiffStraightSetting_IS 31;
BA_ "GenSigMaxLatency" SG_ 1367 FasUsrDefStiffStraightSetting_IS 999;
BA_ "SystemSignalLongSymbol" SG_ 1367 FasUsrDefStiffStraightSetting_IS "FasUsrDefStiffStraightSetting_ISig_6";
BA_ "GenSigCycleTime" SG_ 1367 FasUsrDefinedDampingSetting_ISig 100;
BA_ "GenSigCycleTimeActive" SG_ 1367 FasUsrDefinedDampingSetting_ISig 100;
BA_ "GenSigStartValue" SG_ 1367 FasUsrDefinedDampingSetting_ISig 31;
BA_ "GenSigMaxLatency" SG_ 1367 FasUsrDefinedDampingSetting_ISig 999;
BA_ "SystemSignalLongSymbol" SG_ 1367 FasUsrDefinedDampingSetting_ISig "FasUsrDefinedDampingSetting_ISig_6";
BA_ "GenSigCycleTime" SG_ 1367 ActualFasManualOffsetSetting_ISi 100;
BA_ "GenSigCycleTimeActive" SG_ 1367 ActualFasManualOffsetSetting_ISi 100;
BA_ "GenSigStartValue" SG_ 1367 ActualFasManualOffsetSetting_ISi 31;
BA_ "GenSigMaxLatency" SG_ 1367 ActualFasManualOffsetSetting_ISi 999;
BA_ "SystemSignalLongSymbol" SG_ 1367 ActualFasManualOffsetSetting_ISi "ActualFasManualOffsetSetting_ISig_6";
BA_ "GenSigCycleTime" SG_ 520 FrontRoadWheelAngleEstimate_ISig 100;
BA_ "GenSigCycleTimeActive" SG_ 520 FrontRoadWheelAngleEstimate_ISig 100;
BA_ "GenSigStartValue" SG_ 520 FrontRoadWheelAngleEstimate_ISig 65535;
BA_ "GenSigMaxLatency" SG_ 520 FrontRoadWheelAngleEstimate_ISig 25;
BA_ "SystemSignalLongSymbol" SG_ 520 FrontRoadWheelAngleEstimate_ISig "FrontRoadWheelAngleEstimate_ISig_6";
BA_ "GenSigCycleTime" SG_ 520 OverSteerGuidanceStatus_ISig_6 100;
BA_ "GenSigCycleTimeActive" SG_ 520 OverSteerGuidanceStatus_ISig_6 100;
BA_ "GenSigStartValue" SG_ 520 OverSteerGuidanceStatus_ISig_6 3;
BA_ "GenSigMaxLatency" SG_ 520 OverSteerGuidanceStatus_ISig_6 25;
BA_ "GenSigCycleTime" SG_ 520 DriverSteeringTorqueEstimate_ISi 100;
BA_ "GenSigCycleTimeActive" SG_ 520 DriverSteeringTorqueEstimate_ISi 100;
BA_ "GenSigStartValue" SG_ 520 DriverSteeringTorqueEstimate_ISi 1023;
BA_ "GenSigMaxLatency" SG_ 520 DriverSteeringTorqueEstimate_ISi 25;
BA_ "SystemSignalLongSymbol" SG_ 520 DriverSteeringTorqueEstimate_ISi "DriverSteeringTorqueEstimate_ISig_6";
BA_ "GenSigCycleTime" SG_ 520 FASFullyOperational_ISig_6 100;
BA_ "GenSigCycleTimeActive" SG_ 520 FASFullyOperational_ISig_6 100;
BA_ "GenSigStartValue" SG_ 520 FASFullyOperational_ISig_6 3;
BA_ "GenSigMaxLatency" SG_ 520 FASFullyOperational_ISig_6 25;
BA_ "GenSigCycleTime" SG_ 520 FASSaturated_ISig_6 100;
BA_ "GenSigCycleTimeActive" SG_ 520 FASSaturated_ISig_6 100;
BA_ "GenSigStartValue" SG_ 520 FASSaturated_ISig_6 3;
BA_ "GenSigMaxLatency" SG_ 520 FASSaturated_ISig_6 25;
BA_ "GenSigCycleTime" SG_ 520 FASFunctionInControl_ISig_6 100;
BA_ "GenSigCycleTimeActive" SG_ 520 FASFunctionInControl_ISig_6 100;
BA_ "GenSigStartValue" SG_ 520 FASFunctionInControl_ISig_6 3;
BA_ "GenSigMaxLatency" SG_ 520 FASFunctionInControl_ISig_6 25;
BA_ "GenSigCycleTime" SG_ 520 DriverSteeringTqEstimateConf_ISi 100;
BA_ "GenSigCycleTimeActive" SG_ 520 DriverSteeringTqEstimateConf_ISi 100;
BA_ "GenSigStartValue" SG_ 520 DriverSteeringTqEstimateConf_ISi 7;
BA_ "GenSigMaxLatency" SG_ 520 DriverSteeringTqEstimateConf_ISi 25;
BA_ "SystemSignalLongSymbol" SG_ 520 DriverSteeringTqEstimateConf_ISi "DriverSteeringTqEstimateConf_ISig_6";
BA_ "GenSigCycleTime" SG_ 1232 XPRRequest_EBS 100;
BA_ "GenSigCycleTimeActive" SG_ 1232 XPRRequest_EBS 100;
BA_ "GenSigStartValue" SG_ 1232 XPRRequest_EBS 255;
BA_ "Platform_VMCU1_Sig" SG_ 1232 XPRRequest_EBS 1;
BA_ "GenSigSendType" SG_ 1232 ABSAxle4Active_UB 7;
BA_ "GenSigCycleTime" SG_ 1232 ABSAxle5Active 100;
BA_ "GenSigCycleTimeActive" SG_ 1232 ABSAxle5Active 100;
BA_ "GenSigStartValue" SG_ 1232 ABSAxle5Active 3;
BA_ "NeedsUpdateBit" SG_ 1232 ABSAxle5Active 1;
BA_ "GenSigCycleTime" SG_ 1232 ABSAxle4Active 100;
BA_ "GenSigCycleTimeActive" SG_ 1232 ABSAxle4Active 100;
BA_ "GenSigStartValue" SG_ 1232 ABSAxle4Active 3;
BA_ "NeedsUpdateBit" SG_ 1232 ABSAxle4Active 1;
BA_ "GenSigCycleTime" SG_ 1232 RoadInclination2 100;
BA_ "GenSigCycleTimeActive" SG_ 1232 RoadInclination2 100;
BA_ "GenSigStartValue" SG_ 1232 RoadInclination2 255;
BA_ "GenSigSendType" SG_ 1232 ABSAxle3Active_UB 7;
BA_ "GenSigSendType" SG_ 1232 ABSAxle1Active_UB 7;
BA_ "GenSigCycleTime" SG_ 1232 ABSAxle2Active 100;
BA_ "GenSigCycleTimeActive" SG_ 1232 ABSAxle2Active 100;
BA_ "GenSigStartValue" SG_ 1232 ABSAxle2Active 3;
BA_ "NeedsUpdateBit" SG_ 1232 ABSAxle2Active 1;
BA_ "GenSigCycleTime" SG_ 1232 ABSAxle3Active 100;
BA_ "GenSigCycleTimeActive" SG_ 1232 ABSAxle3Active 100;
BA_ "GenSigStartValue" SG_ 1232 ABSAxle3Active 3;
BA_ "NeedsUpdateBit" SG_ 1232 ABSAxle3Active 1;
BA_ "GenSigCycleTime" SG_ 1232 ABSAxle1Active 100;
BA_ "GenSigCycleTimeActive" SG_ 1232 ABSAxle1Active 100;
BA_ "GenSigStartValue" SG_ 1232 ABSAxle1Active 3;
BA_ "NeedsUpdateBit" SG_ 1232 ABSAxle1Active 1;
BA_ "GenSigSendType" SG_ 1232 ABSAxle2Active_UB 7;
BA_ "GenSigSendType" SG_ 1232 ABSAxle5Active_UB 7;
BA_ "GenSigCycleTime" SG_ 1232 HillHolderMode_ISig_6 100;
BA_ "GenSigCycleTimeActive" SG_ 1232 HillHolderMode_ISig_6 100;
BA_ "GenSigStartValue" SG_ 1232 HillHolderMode_ISig_6 7;
BA_ "Platform_VMCU1_Sig" SG_ 1232 HillHolderMode_ISig_6 1;
BA_ "GenSigCycleTime" SG_ 1507 ScndFrAxleLtRemainBrakeLining 100;
BA_ "GenSigCycleTimeActive" SG_ 1507 ScndFrAxleLtRemainBrakeLining 100;
BA_ "GenSigStartValue" SG_ 1507 ScndFrAxleLtRemainBrakeLining 255;
BA_ "Platform_VMCU1_Sig" SG_ 1507 ScndFrAxleLtRemainBrakeLining 1;
BA_ "GenSigCycleTime" SG_ 1507 ScndFrAxleRtRemainBrakeLining 100;
BA_ "GenSigCycleTimeActive" SG_ 1507 ScndFrAxleRtRemainBrakeLining 100;
BA_ "GenSigStartValue" SG_ 1507 ScndFrAxleRtRemainBrakeLining 255;
BA_ "Platform_VMCU1_Sig" SG_ 1507 ScndFrAxleRtRemainBrakeLining 1;
BA_ "GenSigCycleTime" SG_ 1504 RrAxle1RtRemainBrakeLining 100;
BA_ "GenSigCycleTimeActive" SG_ 1504 RrAxle1RtRemainBrakeLining 100;
BA_ "GenSigStartValue" SG_ 1504 RrAxle1RtRemainBrakeLining 255;
BA_ "Platform_VMCU1_Sig" SG_ 1504 RrAxle1RtRemainBrakeLining 1;
BA_ "GenSigCycleTime" SG_ 1504 RrAxle2RtRemainBrakeLining 100;
BA_ "GenSigCycleTimeActive" SG_ 1504 RrAxle2RtRemainBrakeLining 100;
BA_ "GenSigStartValue" SG_ 1504 RrAxle2RtRemainBrakeLining 255;
BA_ "Platform_VMCU1_Sig" SG_ 1504 RrAxle2RtRemainBrakeLining 1;
BA_ "GenSigCycleTime" SG_ 1504 RrAxle1LtRemainBrakeLining 100;
BA_ "GenSigCycleTimeActive" SG_ 1504 RrAxle1LtRemainBrakeLining 100;
BA_ "GenSigStartValue" SG_ 1504 RrAxle1LtRemainBrakeLining 255;
BA_ "Platform_VMCU1_Sig" SG_ 1504 RrAxle1LtRemainBrakeLining 1;
BA_ "GenSigCycleTime" SG_ 1504 FrAxleLtRemainBrakeLining 100;
BA_ "GenSigCycleTimeActive" SG_ 1504 FrAxleLtRemainBrakeLining 100;
BA_ "GenSigStartValue" SG_ 1504 FrAxleLtRemainBrakeLining 255;
BA_ "Platform_VMCU1_Sig" SG_ 1504 FrAxleLtRemainBrakeLining 1;
BA_ "GenSigCycleTime" SG_ 1504 RrAxle3RtRemainBrakeLining 100;
BA_ "GenSigCycleTimeActive" SG_ 1504 RrAxle3RtRemainBrakeLining 100;
BA_ "GenSigStartValue" SG_ 1504 RrAxle3RtRemainBrakeLining 255;
BA_ "Platform_VMCU1_Sig" SG_ 1504 RrAxle3RtRemainBrakeLining 1;
BA_ "GenSigCycleTime" SG_ 1504 RrAxle2LtRemainBrakeLining 100;
BA_ "GenSigCycleTimeActive" SG_ 1504 RrAxle2LtRemainBrakeLining 100;
BA_ "GenSigStartValue" SG_ 1504 RrAxle2LtRemainBrakeLining 255;
BA_ "Platform_VMCU1_Sig" SG_ 1504 RrAxle2LtRemainBrakeLining 1;
BA_ "GenSigCycleTime" SG_ 1504 FrAxleRtRemainBrakeLining 100;
BA_ "GenSigCycleTimeActive" SG_ 1504 FrAxleRtRemainBrakeLining 100;
BA_ "GenSigStartValue" SG_ 1504 FrAxleRtRemainBrakeLining 255;
BA_ "Platform_VMCU1_Sig" SG_ 1504 FrAxleRtRemainBrakeLining 1;
BA_ "GenSigCycleTime" SG_ 1504 RrAxle3LtRemainBrakeLining 100;
BA_ "GenSigCycleTimeActive" SG_ 1504 RrAxle3LtRemainBrakeLining 100;
BA_ "GenSigStartValue" SG_ 1504 RrAxle3LtRemainBrakeLining 255;
BA_ "Platform_VMCU1_Sig" SG_ 1504 RrAxle3LtRemainBrakeLining 1;
BA_ "GenSigCycleTime" SG_ 1501 Trailer2TireInfoISO_Leakage_ISig 100;
BA_ "GenSigCycleTimeActive" SG_ 1501 Trailer2TireInfoISO_Leakage_ISig 100;
BA_ "GenSigStartValue" SG_ 1501 Trailer2TireInfoISO_Leakage_ISig 65535;
BA_ "NeedsUpdateBit" SG_ 1501 Trailer2TireInfoISO_Leakage_ISig 1;
BA_ "Platform_VMCU1_Sig" SG_ 1501 Trailer2TireInfoISO_Leakage_ISig 1;
BA_ "SystemSignalLongSymbol" SG_ 1501 Trailer2TireInfoISO_Leakage_ISig "Trailer2TireInfoISO_Leakage_ISig_6";
BA_ "GenSigCycleTime" SG_ 1501 Trailer2TireInfoISO_TireId_ISig_ 100;
BA_ "GenSigCycleTimeActive" SG_ 1501 Trailer2TireInfoISO_TireId_ISig_ 100;
BA_ "NeedsUpdateBit" SG_ 1501 Trailer2TireInfoISO_TireId_ISig_ 1;
BA_ "Platform_VMCU1_Sig" SG_ 1501 Trailer2TireInfoISO_TireId_ISig_ 1;
BA_ "SystemSignalLongSymbol" SG_ 1501 Trailer2TireInfoISO_TireId_ISig_ "Trailer2TireInfoISO_TireId_ISig_6";
BA_ "GenSigCycleTime" SG_ 1501 Trailer2TireInfoISO_Warning_ISig 100;
BA_ "GenSigCycleTimeActive" SG_ 1501 Trailer2TireInfoISO_Warning_ISig 100;
BA_ "GenSigStartValue" SG_ 1501 Trailer2TireInfoISO_Warning_ISig 7;
BA_ "NeedsUpdateBit" SG_ 1501 Trailer2TireInfoISO_Warning_ISig 1;
BA_ "Platform_VMCU1_Sig" SG_ 1501 Trailer2TireInfoISO_Warning_ISig 1;
BA_ "SystemSignalLongSymbol" SG_ 1501 Trailer2TireInfoISO_Warning_ISig "Trailer2TireInfoISO_Warning_ISig_6";
BA_ "GenSigCycleTime" SG_ 1501 Trailer2TireInfoISO_Pressure_ISi 100;
BA_ "GenSigCycleTimeActive" SG_ 1501 Trailer2TireInfoISO_Pressure_ISi 100;
BA_ "GenSigStartValue" SG_ 1501 Trailer2TireInfoISO_Pressure_ISi 255;
BA_ "NeedsUpdateBit" SG_ 1501 Trailer2TireInfoISO_Pressure_ISi 1;
BA_ "Platform_VMCU1_Sig" SG_ 1501 Trailer2TireInfoISO_Pressure_ISi 1;
BA_ "SystemSignalLongSymbol" SG_ 1501 Trailer2TireInfoISO_Pressure_ISi "Trailer2TireInfoISO_Pressure_ISig_6";
BA_ "GenSigCycleTime" SG_ 1501 Trailer2TireInfoISO_PresSuff_ISi 100;
BA_ "GenSigCycleTimeActive" SG_ 1501 Trailer2TireInfoISO_PresSuff_ISi 100;
BA_ "GenSigStartValue" SG_ 1501 Trailer2TireInfoISO_PresSuff_ISi 3;
BA_ "NeedsUpdateBit" SG_ 1501 Trailer2TireInfoISO_PresSuff_ISi 1;
BA_ "Platform_VMCU1_Sig" SG_ 1501 Trailer2TireInfoISO_PresSuff_ISi 1;
BA_ "SystemSignalLongSymbol" SG_ 1501 Trailer2TireInfoISO_PresSuff_ISi "Trailer2TireInfoISO_PresSuff_ISig_6";
BA_ "GenSigCycleTime" SG_ 1501 Trailer2TireInfoISO_PowerSupply_ 100;
BA_ "GenSigCycleTimeActive" SG_ 1501 Trailer2TireInfoISO_PowerSupply_ 100;
BA_ "GenSigStartValue" SG_ 1501 Trailer2TireInfoISO_PowerSupply_ 3;
BA_ "NeedsUpdateBit" SG_ 1501 Trailer2TireInfoISO_PowerSupply_ 1;
BA_ "Platform_VMCU1_Sig" SG_ 1501 Trailer2TireInfoISO_PowerSupply_ 1;
BA_ "SystemSignalLongSymbol" SG_ 1501 Trailer2TireInfoISO_PowerSupply_ "Trailer2TireInfoISO_PowerSupply_ISig_6";
BA_ "GenSigSendType" SG_ 1501 Trailer2TireInfoISO_sg_UB_ISig_6 7;
BA_ "GenSigCycleTime" SG_ 1501 Trailer2TireInfoISO_sg_UB_ISig_6 100;
BA_ "GenSigCycleTimeActive" SG_ 1501 Trailer2TireInfoISO_sg_UB_ISig_6 100;
BA_ "Platform_VMCU1_Sig" SG_ 1501 Trailer2TireInfoISO_sg_UB_ISig_6 1;
BA_ "GenSigCycleTime" SG_ 1501 Trailer2TireInfoISO_Active_ISig_ 100;
BA_ "GenSigCycleTimeActive" SG_ 1501 Trailer2TireInfoISO_Active_ISig_ 100;
BA_ "GenSigStartValue" SG_ 1501 Trailer2TireInfoISO_Active_ISig_ 3;
BA_ "NeedsUpdateBit" SG_ 1501 Trailer2TireInfoISO_Active_ISig_ 1;
BA_ "Platform_VMCU1_Sig" SG_ 1501 Trailer2TireInfoISO_Active_ISig_ 1;
BA_ "SystemSignalLongSymbol" SG_ 1501 Trailer2TireInfoISO_Active_ISig_ "Trailer2TireInfoISO_Active_ISig_6";
BA_ "GenSigCycleTime" SG_ 1501 Trailer2TireInfoISO_Temperature_ 100;
BA_ "GenSigCycleTimeActive" SG_ 1501 Trailer2TireInfoISO_Temperature_ 100;
BA_ "GenSigStartValue" SG_ 1501 Trailer2TireInfoISO_Temperature_ 65535;
BA_ "NeedsUpdateBit" SG_ 1501 Trailer2TireInfoISO_Temperature_ 1;
BA_ "Platform_VMCU1_Sig" SG_ 1501 Trailer2TireInfoISO_Temperature_ 1;
BA_ "SystemSignalLongSymbol" SG_ 1501 Trailer2TireInfoISO_Temperature_ "Trailer2TireInfoISO_Temperature_ISig_6";
BA_ "GenSigCycleTime" SG_ 1498 Trailer1TireInfoISO_Leakage_ISig 100;
BA_ "GenSigCycleTimeActive" SG_ 1498 Trailer1TireInfoISO_Leakage_ISig 100;
BA_ "GenSigStartValue" SG_ 1498 Trailer1TireInfoISO_Leakage_ISig 65535;
BA_ "NeedsUpdateBit" SG_ 1498 Trailer1TireInfoISO_Leakage_ISig 1;
BA_ "Platform_VMCU1_Sig" SG_ 1498 Trailer1TireInfoISO_Leakage_ISig 1;
BA_ "SystemSignalLongSymbol" SG_ 1498 Trailer1TireInfoISO_Leakage_ISig "Trailer1TireInfoISO_Leakage_ISig_6";
BA_ "GenSigCycleTime" SG_ 1498 Trailer1TireInfoISO_Pressure_ISi 100;
BA_ "GenSigCycleTimeActive" SG_ 1498 Trailer1TireInfoISO_Pressure_ISi 100;
BA_ "GenSigStartValue" SG_ 1498 Trailer1TireInfoISO_Pressure_ISi 255;
BA_ "NeedsUpdateBit" SG_ 1498 Trailer1TireInfoISO_Pressure_ISi 1;
BA_ "Platform_VMCU1_Sig" SG_ 1498 Trailer1TireInfoISO_Pressure_ISi 1;
BA_ "SystemSignalLongSymbol" SG_ 1498 Trailer1TireInfoISO_Pressure_ISi "Trailer1TireInfoISO_Pressure_ISig_6";
BA_ "GenSigCycleTime" SG_ 1498 Trailer1TireInfoISO_Active_ISig_ 100;
BA_ "GenSigCycleTimeActive" SG_ 1498 Trailer1TireInfoISO_Active_ISig_ 100;
BA_ "GenSigStartValue" SG_ 1498 Trailer1TireInfoISO_Active_ISig_ 3;
BA_ "NeedsUpdateBit" SG_ 1498 Trailer1TireInfoISO_Active_ISig_ 1;
BA_ "Platform_VMCU1_Sig" SG_ 1498 Trailer1TireInfoISO_Active_ISig_ 1;
BA_ "SystemSignalLongSymbol" SG_ 1498 Trailer1TireInfoISO_Active_ISig_ "Trailer1TireInfoISO_Active_ISig_6";
BA_ "GenSigCycleTime" SG_ 1498 Trailer1TireInfoISO_PresSuff_ISi 100;
BA_ "GenSigCycleTimeActive" SG_ 1498 Trailer1TireInfoISO_PresSuff_ISi 100;
BA_ "GenSigStartValue" SG_ 1498 Trailer1TireInfoISO_PresSuff_ISi 3;
BA_ "NeedsUpdateBit" SG_ 1498 Trailer1TireInfoISO_PresSuff_ISi 1;
BA_ "Platform_VMCU1_Sig" SG_ 1498 Trailer1TireInfoISO_PresSuff_ISi 1;
BA_ "SystemSignalLongSymbol" SG_ 1498 Trailer1TireInfoISO_PresSuff_ISi "Trailer1TireInfoISO_PresSuff_ISig_6";
BA_ "GenSigCycleTime" SG_ 1498 Trailer1TireInfoISO_Temperature_ 100;
BA_ "GenSigCycleTimeActive" SG_ 1498 Trailer1TireInfoISO_Temperature_ 100;
BA_ "GenSigStartValue" SG_ 1498 Trailer1TireInfoISO_Temperature_ 65535;
BA_ "NeedsUpdateBit" SG_ 1498 Trailer1TireInfoISO_Temperature_ 1;
BA_ "Platform_VMCU1_Sig" SG_ 1498 Trailer1TireInfoISO_Temperature_ 1;
BA_ "SystemSignalLongSymbol" SG_ 1498 Trailer1TireInfoISO_Temperature_ "Trailer1TireInfoISO_Temperature_ISig_6";
BA_ "GenSigCycleTime" SG_ 1498 Trailer1TireInfoISO_PowerSupply_ 100;
BA_ "GenSigCycleTimeActive" SG_ 1498 Trailer1TireInfoISO_PowerSupply_ 100;
BA_ "GenSigStartValue" SG_ 1498 Trailer1TireInfoISO_PowerSupply_ 3;
BA_ "NeedsUpdateBit" SG_ 1498 Trailer1TireInfoISO_PowerSupply_ 1;
BA_ "Platform_VMCU1_Sig" SG_ 1498 Trailer1TireInfoISO_PowerSupply_ 1;
BA_ "SystemSignalLongSymbol" SG_ 1498 Trailer1TireInfoISO_PowerSupply_ "Trailer1TireInfoISO_PowerSupply_ISig_6";
BA_ "GenSigSendType" SG_ 1498 Trailer1TireInfoISO_sg_UB_ISig_6 7;
BA_ "GenSigCycleTime" SG_ 1498 Trailer1TireInfoISO_sg_UB_ISig_6 100;
BA_ "GenSigCycleTimeActive" SG_ 1498 Trailer1TireInfoISO_sg_UB_ISig_6 100;
BA_ "Platform_VMCU1_Sig" SG_ 1498 Trailer1TireInfoISO_sg_UB_ISig_6 1;
BA_ "GenSigCycleTime" SG_ 1498 Trailer1TireInfoISO_TireId_ISig_ 100;
BA_ "GenSigCycleTimeActive" SG_ 1498 Trailer1TireInfoISO_TireId_ISig_ 100;
BA_ "NeedsUpdateBit" SG_ 1498 Trailer1TireInfoISO_TireId_ISig_ 1;
BA_ "Platform_VMCU1_Sig" SG_ 1498 Trailer1TireInfoISO_TireId_ISig_ 1;
BA_ "SystemSignalLongSymbol" SG_ 1498 Trailer1TireInfoISO_TireId_ISig_ "Trailer1TireInfoISO_TireId_ISig_6";
BA_ "GenSigCycleTime" SG_ 1498 Trailer1TireInfoISO_Warning_ISig 100;
BA_ "GenSigCycleTimeActive" SG_ 1498 Trailer1TireInfoISO_Warning_ISig 100;
BA_ "GenSigStartValue" SG_ 1498 Trailer1TireInfoISO_Warning_ISig 7;
BA_ "NeedsUpdateBit" SG_ 1498 Trailer1TireInfoISO_Warning_ISig 1;
BA_ "Platform_VMCU1_Sig" SG_ 1498 Trailer1TireInfoISO_Warning_ISig 1;
BA_ "SystemSignalLongSymbol" SG_ 1498 Trailer1TireInfoISO_Warning_ISig "Trailer1TireInfoISO_Warning_ISig_6";
BA_ "GenSigCycleTime" SG_ 396 SteeringWheel_AngleValue 100;
BA_ "GenSigCycleTimeActive" SG_ 396 SteeringWheel_AngleValue 100;
BA_ "GenSigStartValue" SG_ 396 SteeringWheel_AngleValue 65535;
BA_ "Platform_VMCU1_Sig" SG_ 396 SteeringWheel_AngleValue 1;
BA_ "GenSigCycleTime" SG_ 396 SteeringWheel_AngleCounter 100;
BA_ "GenSigCycleTimeActive" SG_ 396 SteeringWheel_AngleCounter 100;
BA_ "Platform_VMCU1_Sig" SG_ 396 SteeringWheel_AngleCounter 1;
BA_ "GenSigCycleTime" SG_ 396 SteeringWheel_AngleCRC 100;
BA_ "GenSigCycleTimeActive" SG_ 396 SteeringWheel_AngleCRC 100;
BA_ "Platform_VMCU1_Sig" SG_ 396 SteeringWheel_AngleCRC 1;
BA_ "GenSigCycleTime" SG_ 395 ActualTagWheelAngle 100;
BA_ "GenSigCycleTimeActive" SG_ 395 ActualTagWheelAngle 100;
BA_ "GenSigStartValue" SG_ 395 ActualTagWheelAngle 65535;
BA_ "GenSigMaxLatency" SG_ 395 ActualTagWheelAngle 23;
BA_ "Platform_VMCU1_Sig" SG_ 395 ActualTagWheelAngle 1;
BA_ "GenSigCycleTime" SG_ 395 ActualPusherWheelAngle 100;
BA_ "GenSigCycleTimeActive" SG_ 395 ActualPusherWheelAngle 100;
BA_ "GenSigStartValue" SG_ 395 ActualPusherWheelAngle 65535;
BA_ "GenSigMaxLatency" SG_ 395 ActualPusherWheelAngle 23;
BA_ "Platform_VMCU1_Sig" SG_ 395 ActualPusherWheelAngle 1;
BA_ "GenSigCycleTime" SG_ 395 SteeringWheelAngle_ISig_6 100;
BA_ "GenSigCycleTimeActive" SG_ 395 SteeringWheelAngle_ISig_6 100;
BA_ "GenSigStartValue" SG_ 395 SteeringWheelAngle_ISig_6 65535;
BA_ "GenSigMaxLatency" SG_ 395 SteeringWheelAngle_ISig_6 23;
BA_ "NeedsUpdateBit" SG_ 395 SteeringWheelAngle_ISig_6 1;
BA_ "Platform_VMCU1_Sig" SG_ 395 SteeringWheelAngle_ISig_6 1;
BA_ "SeToolAncestorID_SIGNAL" SG_ 395 SteeringWheelAngle_ISig_6 "x0000001D041258E9";
BA_ "SeToolItemID_SIGNAL" SG_ 395 SteeringWheelAngle_ISig_6 "x0000001D041258E9";
BA_ "SeToolName_SIGNAL" SG_ 395 SteeringWheelAngle_ISig_6 "SteeringWheelAngle";
BA_ "SeToolVersion_SIGNAL" SG_ 395 SteeringWheelAngle_ISig_6 "1";
BA_ "GenSigSendType" SG_ 395 SteeringWheelAngle_UB_ISig_6 7;
BA_ "Platform_VMCU1_Sig" SG_ 395 SteeringWheelAngle_UB_ISig_6 1;
BA_ "GenSigCycleTime" SG_ 394 ScndRrDriveAxleRightWheelSpeed 100;
BA_ "GenSigCycleTimeActive" SG_ 394 ScndRrDriveAxleRightWheelSpeed 100;
BA_ "GenSigStartValue" SG_ 394 ScndRrDriveAxleRightWheelSpeed 65535;
BA_ "GenSigMaxLatency" SG_ 394 ScndRrDriveAxleRightWheelSpeed 22;
BA_ "Platform_VMCU1_Sig" SG_ 394 ScndRrDriveAxleRightWheelSpeed 1;
BA_ "SeToolAncestorID_SIGNAL" SG_ 394 ScndRrDriveAxleRightWheelSpeed "x0000001D0410DA90";
BA_ "SeToolItemID_SIGNAL" SG_ 394 ScndRrDriveAxleRightWheelSpeed "x0000001D0410DA90";
BA_ "SeToolName_SIGNAL" SG_ 394 ScndRrDriveAxleRightWheelSpeed "2ndRearDriveAxleRightWheelSpeed";
BA_ "SeToolVersion_SIGNAL" SG_ 394 ScndRrDriveAxleRightWheelSpeed "1";
BA_ "GenSigCycleTime" SG_ 394 ScndFrAxleLeftWheelSpeed 100;
BA_ "GenSigCycleTimeActive" SG_ 394 ScndFrAxleLeftWheelSpeed 100;
BA_ "GenSigStartValue" SG_ 394 ScndFrAxleLeftWheelSpeed 65535;
BA_ "GenSigMaxLatency" SG_ 394 ScndFrAxleLeftWheelSpeed 22;
BA_ "Platform_VMCU1_Sig" SG_ 394 ScndFrAxleLeftWheelSpeed 1;
BA_ "GenSigCycleTime" SG_ 394 ScndFrAxleRightWheelSpeed 100;
BA_ "GenSigCycleTimeActive" SG_ 394 ScndFrAxleRightWheelSpeed 100;
BA_ "GenSigStartValue" SG_ 394 ScndFrAxleRightWheelSpeed 65535;
BA_ "GenSigMaxLatency" SG_ 394 ScndFrAxleRightWheelSpeed 22;
BA_ "Platform_VMCU1_Sig" SG_ 394 ScndFrAxleRightWheelSpeed 1;
BA_ "GenSigCycleTime" SG_ 394 ScndRrDriveAxleLeftWheelSpeed 100;
BA_ "GenSigCycleTimeActive" SG_ 394 ScndRrDriveAxleLeftWheelSpeed 100;
BA_ "GenSigStartValue" SG_ 394 ScndRrDriveAxleLeftWheelSpeed 65535;
BA_ "GenSigMaxLatency" SG_ 394 ScndRrDriveAxleLeftWheelSpeed 22;
BA_ "Platform_VMCU1_Sig" SG_ 394 ScndRrDriveAxleLeftWheelSpeed 1;
BA_ "SeToolAncestorID_SIGNAL" SG_ 394 ScndRrDriveAxleLeftWheelSpeed "x0000001D0410DA8E";
BA_ "SeToolItemID_SIGNAL" SG_ 394 ScndRrDriveAxleLeftWheelSpeed "x0000001D0410DA8E";
BA_ "SeToolName_SIGNAL" SG_ 394 ScndRrDriveAxleLeftWheelSpeed "2ndRearDriveAxleLeftWheelSpeed";
BA_ "SeToolVersion_SIGNAL" SG_ 394 ScndRrDriveAxleLeftWheelSpeed "1";
BA_ "GenSigCycleTime" SG_ 391 PusherAxleRightWheelSpeed 100;
BA_ "GenSigCycleTimeActive" SG_ 391 PusherAxleRightWheelSpeed 100;
BA_ "GenSigStartValue" SG_ 391 PusherAxleRightWheelSpeed 65535;
BA_ "GenSigMaxLatency" SG_ 391 PusherAxleRightWheelSpeed 21;
BA_ "Platform_VMCU1_Sig" SG_ 391 PusherAxleRightWheelSpeed 1;
BA_ "GenSigCycleTime" SG_ 391 TagAxleRightWheelSpeed 100;
BA_ "GenSigCycleTimeActive" SG_ 391 TagAxleRightWheelSpeed 100;
BA_ "GenSigStartValue" SG_ 391 TagAxleRightWheelSpeed 65535;
BA_ "GenSigMaxLatency" SG_ 391 TagAxleRightWheelSpeed 21;
BA_ "Platform_VMCU1_Sig" SG_ 391 TagAxleRightWheelSpeed 1;
BA_ "GenSigCycleTime" SG_ 391 TagAxleLeftWheelSpeed 100;
BA_ "GenSigCycleTimeActive" SG_ 391 TagAxleLeftWheelSpeed 100;
BA_ "GenSigStartValue" SG_ 391 TagAxleLeftWheelSpeed 65535;
BA_ "GenSigMaxLatency" SG_ 391 TagAxleLeftWheelSpeed 21;
BA_ "Platform_VMCU1_Sig" SG_ 391 TagAxleLeftWheelSpeed 1;
BA_ "GenSigCycleTime" SG_ 391 PusherAxleLeftWheelSpeed 100;
BA_ "GenSigCycleTimeActive" SG_ 391 PusherAxleLeftWheelSpeed 100;
BA_ "GenSigStartValue" SG_ 391 PusherAxleLeftWheelSpeed 65535;
BA_ "GenSigMaxLatency" SG_ 391 PusherAxleLeftWheelSpeed 21;
BA_ "Platform_VMCU1_Sig" SG_ 391 PusherAxleLeftWheelSpeed 1;
BA_ "GenSigCycleTime" SG_ 386 LongitudinalAcceleration_ISig_6 100;
BA_ "GenSigCycleTimeActive" SG_ 386 LongitudinalAcceleration_ISig_6 100;
BA_ "GenSigStartValue" SG_ 386 LongitudinalAcceleration_ISig_6 65535;
BA_ "GenSigMaxLatency" SG_ 386 LongitudinalAcceleration_ISig_6 20;
BA_ "Platform_VMCU1_Sig" SG_ 386 LongitudinalAcceleration_ISig_6 1;
BA_ "GenSigCycleTime" SG_ 386 EBSBrakeSwitch 100;
BA_ "GenSigCycleTimeActive" SG_ 386 EBSBrakeSwitch 100;
BA_ "GenSigStartValue" SG_ 386 EBSBrakeSwitch 3;
BA_ "GenSigMaxLatency" SG_ 386 EBSBrakeSwitch 20;
BA_ "Platform_VMCU1_Sig" SG_ 386 EBSBrakeSwitch 1;
BA_ "GenSigCycleTime" SG_ 386 BrakeLightActivationRequest 100;
BA_ "GenSigCycleTimeActive" SG_ 386 BrakeLightActivationRequest 100;
BA_ "GenSigStartValue" SG_ 386 BrakeLightActivationRequest 3;
BA_ "Platform_VMCU1_Sig" SG_ 386 BrakeLightActivationRequest 1;
BA_ "SeToolAncestorID_SIGNAL" SG_ 386 BrakeLightActivationRequest "x0000001D042C7C20";
BA_ "SeToolItemID_SIGNAL" SG_ 386 BrakeLightActivationRequest "x0000001D042C7C20";
BA_ "SeToolName_SIGNAL" SG_ 386 BrakeLightActivationRequest "BrakeLightActivationRequest";
BA_ "SeToolVersion_SIGNAL" SG_ 386 BrakeLightActivationRequest "1";
BA_ "GenSigCycleTime" SG_ 386 YawRate_ISig_6 100;
BA_ "GenSigCycleTimeActive" SG_ 386 YawRate_ISig_6 100;
BA_ "GenSigStartValue" SG_ 386 YawRate_ISig_6 65535;
BA_ "GenSigMaxLatency" SG_ 386 YawRate_ISig_6 20;
BA_ "Platform_VMCU1_Sig" SG_ 386 YawRate_ISig_6 1;
BA_ "SeToolAncestorID_SIGNAL" SG_ 386 YawRate_ISig_6 "x0000001D04146F42";
BA_ "SeToolItemID_SIGNAL" SG_ 386 YawRate_ISig_6 "x0000001D04146F42";
BA_ "SeToolName_SIGNAL" SG_ 386 YawRate_ISig_6 "YawRate";
BA_ "SeToolVersion_SIGNAL" SG_ 386 YawRate_ISig_6 "1";
BA_ "GenSigCycleTime" SG_ 386 VDCBrakeLightRequest 100;
BA_ "GenSigCycleTimeActive" SG_ 386 VDCBrakeLightRequest 100;
BA_ "GenSigStartValue" SG_ 386 VDCBrakeLightRequest 3;
BA_ "GenSigMaxLatency" SG_ 386 VDCBrakeLightRequest 20;
BA_ "Platform_VMCU1_Sig" SG_ 386 VDCBrakeLightRequest 1;
BA_ "GenSigCycleTime" SG_ 386 LateralAcceleration_ISig_6 100;
BA_ "GenSigCycleTimeActive" SG_ 386 LateralAcceleration_ISig_6 100;
BA_ "GenSigStartValue" SG_ 386 LateralAcceleration_ISig_6 65535;
BA_ "GenSigMaxLatency" SG_ 386 LateralAcceleration_ISig_6 20;
BA_ "Platform_VMCU1_Sig" SG_ 386 LateralAcceleration_ISig_6 1;
BA_ "GenSigCycleTime" SG_ 386 EBSBrakePedalPosition 100;
BA_ "GenSigCycleTimeActive" SG_ 386 EBSBrakePedalPosition 100;
BA_ "GenSigStartValue" SG_ 386 EBSBrakePedalPosition 255;
BA_ "GenSigMaxLatency" SG_ 386 EBSBrakePedalPosition 20;
BA_ "Platform_VMCU1_Sig" SG_ 386 EBSBrakePedalPosition 1;
BA_ "GenSigCycleTime" SG_ 824 TrailerEBSAmberWarning 100;
BA_ "GenSigCycleTimeActive" SG_ 824 TrailerEBSAmberWarning 100;
BA_ "GenSigStartValue" SG_ 824 TrailerEBSAmberWarning 3;
BA_ "Platform_VMCU1_Sig" SG_ 824 TrailerEBSAmberWarning 1;
BA_ "GenSigCycleTime" SG_ 824 HSAState_ISig_6 100;
BA_ "GenSigCycleTimeActive" SG_ 824 HSAState_ISig_6 100;
BA_ "GenSigStartValue" SG_ 824 HSAState_ISig_6 3;
BA_ "GenSigMaxLatency" SG_ 824 HSAState_ISig_6 35;
BA_ "Platform_VMCU1_Sig" SG_ 824 HSAState_ISig_6 1;
BA_ "GenSigCycleTime" SG_ 824 PusherLiftAxleLoweringInhibit 100;
BA_ "GenSigCycleTimeActive" SG_ 824 PusherLiftAxleLoweringInhibit 100;
BA_ "GenSigStartValue" SG_ 824 PusherLiftAxleLoweringInhibit 3;
BA_ "GenSigMaxLatency" SG_ 824 PusherLiftAxleLoweringInhibit 35;
BA_ "Platform_VMCU1_Sig" SG_ 824 PusherLiftAxleLoweringInhibit 1;
BA_ "GenSigCycleTime" SG_ 824 TrailersConnected_ISig_6 100;
BA_ "GenSigCycleTimeActive" SG_ 824 TrailersConnected_ISig_6 100;
BA_ "GenSigInactiveValue" SG_ 824 TrailersConnected_ISig_6 7;
BA_ "GenSigStartValue" SG_ 824 TrailersConnected_ISig_6 7;
BA_ "GenSigMaxLatency" SG_ 824 TrailersConnected_ISig_6 35;
BA_ "Platform_VMCU1_Sig" SG_ 824 TrailersConnected_ISig_6 1;
BA_ "GenSigCycleTime" SG_ 824 YCBrakeControlActive_ISig_6 100;
BA_ "GenSigCycleTimeActive" SG_ 824 YCBrakeControlActive_ISig_6 100;
BA_ "GenSigStartValue" SG_ 824 YCBrakeControlActive_ISig_6 3;
BA_ "GenSigMaxLatency" SG_ 824 YCBrakeControlActive_ISig_6 35;
BA_ "Platform_VMCU1_Sig" SG_ 824 YCBrakeControlActive_ISig_6 1;
BA_ "GenSigCycleTime" SG_ 824 YCEngineControlActive_ISig_6 100;
BA_ "GenSigCycleTimeActive" SG_ 824 YCEngineControlActive_ISig_6 100;
BA_ "GenSigStartValue" SG_ 824 YCEngineControlActive_ISig_6 3;
BA_ "Platform_VMCU1_Sig" SG_ 824 YCEngineControlActive_ISig_6 1;
BA_ "GenSigCycleTime" SG_ 824 StretchBrake_Stat_ISig_6 100;
BA_ "GenSigCycleTimeActive" SG_ 824 StretchBrake_Stat_ISig_6 100;
BA_ "GenSigStartValue" SG_ 824 StretchBrake_Stat_ISig_6 7;
BA_ "GenSigMaxLatency" SG_ 824 StretchBrake_Stat_ISig_6 35;
BA_ "Platform_VMCU1_Sig" SG_ 824 StretchBrake_Stat_ISig_6 1;
BA_ "GenSigCycleTime" SG_ 824 Trailer1LiftAxle1Pos_ISig_6 100;
BA_ "GenSigCycleTimeActive" SG_ 824 Trailer1LiftAxle1Pos_ISig_6 100;
BA_ "GenSigStartValue" SG_ 824 Trailer1LiftAxle1Pos_ISig_6 3;
BA_ "GenSigCycleTime" SG_ 824 Trailer1LiftAxle2Pos_ISig_6 100;
BA_ "GenSigCycleTimeActive" SG_ 824 Trailer1LiftAxle2Pos_ISig_6 100;
BA_ "GenSigStartValue" SG_ 824 Trailer1LiftAxle2Pos_ISig_6 3;
BA_ "GenSigMaxLatency" SG_ 824 Trailer1LiftAxle2Pos_ISig_6 35;
BA_ "Platform_VMCU1_Sig" SG_ 824 Trailer1LiftAxle2Pos_ISig_6 1;
BA_ "GenSigCycleTime" SG_ 824 SteeringWheelAngleComp 100;
BA_ "GenSigCycleTimeActive" SG_ 824 SteeringWheelAngleComp 100;
BA_ "GenSigStartValue" SG_ 824 SteeringWheelAngleComp 65535;
BA_ "Platform_VMCU1_Sig" SG_ 824 SteeringWheelAngleComp 1;
BA_ "GenSigCycleTime" SG_ 824 FrontParkBrakeOverrideStatus 100;
BA_ "GenSigCycleTimeActive" SG_ 824 FrontParkBrakeOverrideStatus 100;
BA_ "GenSigStartValue" SG_ 824 FrontParkBrakeOverrideStatus 3;
BA_ "GenSigMaxLatency" SG_ 824 FrontParkBrakeOverrideStatus 35;
BA_ "Platform_VMCU1_Sig" SG_ 824 FrontParkBrakeOverrideStatus 1;
BA_ "SeToolAncestorID_SIGNAL" SG_ 824 FrontParkBrakeOverrideStatus "x0000001D04131A22";
BA_ "SeToolItemID_SIGNAL" SG_ 824 FrontParkBrakeOverrideStatus "x0000001D04131A22";
BA_ "SeToolName_SIGNAL" SG_ 824 FrontParkBrakeOverrideStatus "FrontParkBrakeOverrideStatus";
BA_ "SeToolVersion_SIGNAL" SG_ 824 FrontParkBrakeOverrideStatus "1";
BA_ "GenSigCycleTime" SG_ 824 BrakingSystemPressureLim_rqst 100;
BA_ "GenSigCycleTimeActive" SG_ 824 BrakingSystemPressureLim_rqst 100;
BA_ "GenSigStartValue" SG_ 824 BrakingSystemPressureLim_rqst 3;
BA_ "GenSigMaxLatency" SG_ 824 BrakingSystemPressureLim_rqst 107;
BA_ "Platform_VMCU1_Sig" SG_ 824 BrakingSystemPressureLim_rqst 1;
BA_ "SeToolAncestorID_SIGNAL" SG_ 824 BrakingSystemPressureLim_rqst "x0000001D042E3933";
BA_ "SeToolItemID_SIGNAL" SG_ 824 BrakingSystemPressureLim_rqst "x0000001D042E3933";
BA_ "SeToolName_SIGNAL" SG_ 824 BrakingSystemPressureLim_rqst "BrakingSystemPressureLimitation_rqst";
BA_ "SeToolVersion_SIGNAL" SG_ 824 BrakingSystemPressureLim_rqst "1";
BA_ "GenSigCycleTime" SG_ 824 ROPEngineControlActive_ISig_6 100;
BA_ "GenSigCycleTimeActive" SG_ 824 ROPEngineControlActive_ISig_6 100;
BA_ "GenSigStartValue" SG_ 824 ROPEngineControlActive_ISig_6 3;
BA_ "Platform_VMCU1_Sig" SG_ 824 ROPEngineControlActive_ISig_6 1;
BA_ "GenSigCycleTime" SG_ 824 TrailerControlPressure 100;
BA_ "GenSigCycleTimeActive" SG_ 824 TrailerControlPressure 100;
BA_ "GenSigStartValue" SG_ 824 TrailerControlPressure 255;
BA_ "GenSigMaxLatency" SG_ 824 TrailerControlPressure 35;
BA_ "Platform_VMCU1_Sig" SG_ 824 TrailerControlPressure 1;
BA_ "GenSigCycleTime" SG_ 824 Trailer1TractionHelp_ISig_6 100;
BA_ "GenSigCycleTimeActive" SG_ 824 Trailer1TractionHelp_ISig_6 100;
BA_ "GenSigStartValue" SG_ 824 Trailer1TractionHelp_ISig_6 3;
BA_ "GenSigMaxLatency" SG_ 824 Trailer1TractionHelp_ISig_6 35;
BA_ "Platform_VMCU1_Sig" SG_ 824 Trailer1TractionHelp_ISig_6 1;
BA_ "GenSigCycleTime" SG_ 824 TagLiftAxleLoweringInhibit 100;
BA_ "GenSigCycleTimeActive" SG_ 824 TagLiftAxleLoweringInhibit 100;
BA_ "GenSigStartValue" SG_ 824 TagLiftAxleLoweringInhibit 3;
BA_ "GenSigMaxLatency" SG_ 824 TagLiftAxleLoweringInhibit 35;
BA_ "Platform_VMCU1_Sig" SG_ 824 TagLiftAxleLoweringInhibit 1;
BA_ "GenSigCycleTime" SG_ 824 ROPBrakeControlActive_ISig_6 100;
BA_ "GenSigCycleTimeActive" SG_ 824 ROPBrakeControlActive_ISig_6 100;
BA_ "GenSigStartValue" SG_ 824 ROPBrakeControlActive_ISig_6 3;
BA_ "GenSigMaxLatency" SG_ 824 ROPBrakeControlActive_ISig_6 35;
BA_ "Platform_VMCU1_Sig" SG_ 824 ROPBrakeControlActive_ISig_6 1;
BA_ "GenSigCycleTime" SG_ 824 SplitBoxDiffLockActvnFuncReq 100;
BA_ "GenSigCycleTimeActive" SG_ 824 SplitBoxDiffLockActvnFuncReq 100;
BA_ "GenSigStartValue" SG_ 824 SplitBoxDiffLockActvnFuncReq 3;
BA_ "Platform_VMCU1_Sig" SG_ 824 SplitBoxDiffLockActvnFuncReq 1;
BA_ "GenSigCycleTime" SG_ 824 TrailerBrake_Stat 100;
BA_ "GenSigCycleTimeActive" SG_ 824 TrailerBrake_Stat 100;
BA_ "GenSigStartValue" SG_ 824 TrailerBrake_Stat 3;
BA_ "GenSigMaxLatency" SG_ 824 TrailerBrake_Stat 35;
BA_ "Platform_VMCU1_Sig" SG_ 824 TrailerBrake_Stat 1;
BA_ "GenSigCycleTime" SG_ 529 RrAxle3LtWhlBrakeApplPrsHiRng 100;
BA_ "GenSigCycleTimeActive" SG_ 529 RrAxle3LtWhlBrakeApplPrsHiRng 100;
BA_ "GenSigStartValue" SG_ 529 RrAxle3LtWhlBrakeApplPrsHiRng 255;
BA_ "GenSigMaxLatency" SG_ 529 RrAxle3LtWhlBrakeApplPrsHiRng 108;
BA_ "Platform_VMCU1_Sig" SG_ 529 RrAxle3LtWhlBrakeApplPrsHiRng 1;
BA_ "SeToolAncestorID_SIGNAL" SG_ 529 RrAxle3LtWhlBrakeApplPrsHiRng "x0000001D04151BFF";
BA_ "SeToolItemID_SIGNAL" SG_ 529 RrAxle3LtWhlBrakeApplPrsHiRng "x0000001D04151BFF";
BA_ "SeToolName_SIGNAL" SG_ 529 RrAxle3LtWhlBrakeApplPrsHiRng "BrakeApplicationPressureHighRangeRearAxle#3LeftWheel";
BA_ "SeToolVersion_SIGNAL" SG_ 529 RrAxle3LtWhlBrakeApplPrsHiRng "1";
BA_ "GenSigCycleTime" SG_ 529 RrAxle1LtWhlBrakeApplPrsHiRng 100;
BA_ "GenSigCycleTimeActive" SG_ 529 RrAxle1LtWhlBrakeApplPrsHiRng 100;
BA_ "GenSigStartValue" SG_ 529 RrAxle1LtWhlBrakeApplPrsHiRng 255;
BA_ "GenSigMaxLatency" SG_ 529 RrAxle1LtWhlBrakeApplPrsHiRng 108;
BA_ "Platform_VMCU1_Sig" SG_ 529 RrAxle1LtWhlBrakeApplPrsHiRng 1;
BA_ "SeToolAncestorID_SIGNAL" SG_ 529 RrAxle1LtWhlBrakeApplPrsHiRng "x0000001D04151B77";
BA_ "SeToolItemID_SIGNAL" SG_ 529 RrAxle1LtWhlBrakeApplPrsHiRng "x0000001D04151B77";
BA_ "SeToolName_SIGNAL" SG_ 529 RrAxle1LtWhlBrakeApplPrsHiRng "BrakeApplicationPressureHighRangeRearAxle#1LeftWheel";
BA_ "SeToolVersion_SIGNAL" SG_ 529 RrAxle1LtWhlBrakeApplPrsHiRng "1";
BA_ "GenSigCycleTime" SG_ 529 FrAxleLtWhlBrakeApplPrsHiRng 100;
BA_ "GenSigCycleTimeActive" SG_ 529 FrAxleLtWhlBrakeApplPrsHiRng 100;
BA_ "GenSigStartValue" SG_ 529 FrAxleLtWhlBrakeApplPrsHiRng 255;
BA_ "GenSigMaxLatency" SG_ 529 FrAxleLtWhlBrakeApplPrsHiRng 108;
BA_ "Platform_VMCU1_Sig" SG_ 529 FrAxleLtWhlBrakeApplPrsHiRng 1;
BA_ "SeToolAncestorID_SIGNAL" SG_ 529 FrAxleLtWhlBrakeApplPrsHiRng "x0000001D04151B29";
BA_ "SeToolItemID_SIGNAL" SG_ 529 FrAxleLtWhlBrakeApplPrsHiRng "x0000001D04151B29";
BA_ "SeToolName_SIGNAL" SG_ 529 FrAxleLtWhlBrakeApplPrsHiRng "BrakeApplicationPressureHighRangeFrontAxleLeftWheel";
BA_ "SeToolVersion_SIGNAL" SG_ 529 FrAxleLtWhlBrakeApplPrsHiRng "1";
BA_ "GenSigCycleTime" SG_ 529 RrAxle1RtWhlBrakeApplPrsHiRng 100;
BA_ "GenSigCycleTimeActive" SG_ 529 RrAxle1RtWhlBrakeApplPrsHiRng 100;
BA_ "GenSigStartValue" SG_ 529 RrAxle1RtWhlBrakeApplPrsHiRng 255;
BA_ "GenSigMaxLatency" SG_ 529 RrAxle1RtWhlBrakeApplPrsHiRng 108;
BA_ "Platform_VMCU1_Sig" SG_ 529 RrAxle1RtWhlBrakeApplPrsHiRng 1;
BA_ "SeToolAncestorID_SIGNAL" SG_ 529 RrAxle1RtWhlBrakeApplPrsHiRng "x0000001D04151B89";
BA_ "SeToolItemID_SIGNAL" SG_ 529 RrAxle1RtWhlBrakeApplPrsHiRng "x0000001D04151B89";
BA_ "SeToolName_SIGNAL" SG_ 529 RrAxle1RtWhlBrakeApplPrsHiRng "BrakeApplicationPressureHighRangeRearAxle#1RightWheel";
BA_ "SeToolVersion_SIGNAL" SG_ 529 RrAxle1RtWhlBrakeApplPrsHiRng "1";
BA_ "GenSigCycleTime" SG_ 529 RrAxle3RtWhlBrakeApplPrsHiRng 100;
BA_ "GenSigCycleTimeActive" SG_ 529 RrAxle3RtWhlBrakeApplPrsHiRng 100;
BA_ "GenSigStartValue" SG_ 529 RrAxle3RtWhlBrakeApplPrsHiRng 255;
BA_ "GenSigMaxLatency" SG_ 529 RrAxle3RtWhlBrakeApplPrsHiRng 108;
BA_ "Platform_VMCU1_Sig" SG_ 529 RrAxle3RtWhlBrakeApplPrsHiRng 1;
BA_ "SeToolAncestorID_SIGNAL" SG_ 529 RrAxle3RtWhlBrakeApplPrsHiRng "x0000001D04151C2C";
BA_ "SeToolItemID_SIGNAL" SG_ 529 RrAxle3RtWhlBrakeApplPrsHiRng "x0000001D04151C2C";
BA_ "SeToolName_SIGNAL" SG_ 529 RrAxle3RtWhlBrakeApplPrsHiRng "BrakeApplicationPressureHighRangeRearAxle#3RightWheel";
BA_ "SeToolVersion_SIGNAL" SG_ 529 RrAxle3RtWhlBrakeApplPrsHiRng "1";
BA_ "GenSigCycleTime" SG_ 529 RrAxle2LtWhlBrakeApplPrsHiRng 100;
BA_ "GenSigCycleTimeActive" SG_ 529 RrAxle2LtWhlBrakeApplPrsHiRng 100;
BA_ "GenSigStartValue" SG_ 529 RrAxle2LtWhlBrakeApplPrsHiRng 255;
BA_ "GenSigMaxLatency" SG_ 529 RrAxle2LtWhlBrakeApplPrsHiRng 108;
BA_ "Platform_VMCU1_Sig" SG_ 529 RrAxle2LtWhlBrakeApplPrsHiRng 1;
BA_ "SeToolAncestorID_SIGNAL" SG_ 529 RrAxle2LtWhlBrakeApplPrsHiRng "x0000001D04151BA3";
BA_ "SeToolItemID_SIGNAL" SG_ 529 RrAxle2LtWhlBrakeApplPrsHiRng "x0000001D04151BA3";
BA_ "SeToolName_SIGNAL" SG_ 529 RrAxle2LtWhlBrakeApplPrsHiRng "BrakeApplicationPressureHighRangeRearAxle#2LeftWheel";
BA_ "SeToolVersion_SIGNAL" SG_ 529 RrAxle2LtWhlBrakeApplPrsHiRng "1";
BA_ "GenSigCycleTime" SG_ 529 FrAxleRtWhlBrakeApplPrsHiRng 100;
BA_ "GenSigCycleTimeActive" SG_ 529 FrAxleRtWhlBrakeApplPrsHiRng 100;
BA_ "GenSigStartValue" SG_ 529 FrAxleRtWhlBrakeApplPrsHiRng 255;
BA_ "GenSigMaxLatency" SG_ 529 FrAxleRtWhlBrakeApplPrsHiRng 108;
BA_ "Platform_VMCU1_Sig" SG_ 529 FrAxleRtWhlBrakeApplPrsHiRng 1;
BA_ "SeToolAncestorID_SIGNAL" SG_ 529 FrAxleRtWhlBrakeApplPrsHiRng "x0000001D04151B57";
BA_ "SeToolItemID_SIGNAL" SG_ 529 FrAxleRtWhlBrakeApplPrsHiRng "x0000001D04151B57";
BA_ "SeToolName_SIGNAL" SG_ 529 FrAxleRtWhlBrakeApplPrsHiRng "BrakeApplicationPressureHighRangeFrontAxleRightWheel";
BA_ "SeToolVersion_SIGNAL" SG_ 529 FrAxleRtWhlBrakeApplPrsHiRng "1";
BA_ "GenSigCycleTime" SG_ 529 RrAxle2RtWhlBrakeApplPrsHiRng 100;
BA_ "GenSigCycleTimeActive" SG_ 529 RrAxle2RtWhlBrakeApplPrsHiRng 100;
BA_ "GenSigStartValue" SG_ 529 RrAxle2RtWhlBrakeApplPrsHiRng 255;
BA_ "GenSigMaxLatency" SG_ 529 RrAxle2RtWhlBrakeApplPrsHiRng 108;
BA_ "Platform_VMCU1_Sig" SG_ 529 RrAxle2RtWhlBrakeApplPrsHiRng 1;
BA_ "SeToolAncestorID_SIGNAL" SG_ 529 RrAxle2RtWhlBrakeApplPrsHiRng "x0000001D04151BB0";
BA_ "SeToolItemID_SIGNAL" SG_ 529 RrAxle2RtWhlBrakeApplPrsHiRng "x0000001D04151BB0";
BA_ "SeToolName_SIGNAL" SG_ 529 RrAxle2RtWhlBrakeApplPrsHiRng "BrakeApplicationPressureHighRangeRearAxle#2RightWheel";
BA_ "SeToolVersion_SIGNAL" SG_ 529 RrAxle2RtWhlBrakeApplPrsHiRng "1";
BA_ "GenSigCycleTime" SG_ 516 EASActualTagWheelAngle 100;
BA_ "GenSigCycleTimeActive" SG_ 516 EASActualTagWheelAngle 100;
BA_ "GenSigStartValue" SG_ 516 EASActualTagWheelAngle 65535;
BA_ "Platform_VMCU1_Sig" SG_ 516 EASActualTagWheelAngle 1;
BA_ "GenSigCycleTime" SG_ 516 EASPusherLiftAxleLoweringInhib 100;
BA_ "GenSigCycleTimeActive" SG_ 516 EASPusherLiftAxleLoweringInhib 100;
BA_ "GenSigStartValue" SG_ 516 EASPusherLiftAxleLoweringInhib 3;
BA_ "Platform_VMCU1_Sig" SG_ 516 EASPusherLiftAxleLoweringInhib 1;
BA_ "GenSigCycleTime" SG_ 516 ExtraAxleSteeringFunctionStat_IS 100;
BA_ "GenSigCycleTimeActive" SG_ 516 ExtraAxleSteeringFunctionStat_IS 100;
BA_ "GenSigStartValue" SG_ 516 ExtraAxleSteeringFunctionStat_IS 7;
BA_ "Platform_VMCU1_Sig" SG_ 516 ExtraAxleSteeringFunctionStat_IS 1;
BA_ "SystemSignalLongSymbol" SG_ 516 ExtraAxleSteeringFunctionStat_IS "ExtraAxleSteeringFunctionStat_ISig_6";
BA_ "GenSigCycleTime" SG_ 516 EASTagLiftAxleLoweringInhibit 100;
BA_ "GenSigCycleTimeActive" SG_ 516 EASTagLiftAxleLoweringInhibit 100;
BA_ "GenSigStartValue" SG_ 516 EASTagLiftAxleLoweringInhibit 3;
BA_ "Platform_VMCU1_Sig" SG_ 516 EASTagLiftAxleLoweringInhibit 1;
BA_ "GenSigCycleTime" SG_ 516 EASActualPusherWheelAngle 100;
BA_ "GenSigCycleTimeActive" SG_ 516 EASActualPusherWheelAngle 100;
BA_ "GenSigStartValue" SG_ 516 EASActualPusherWheelAngle 65535;
BA_ "Platform_VMCU1_Sig" SG_ 516 EASActualPusherWheelAngle 1;
BA_ "GenSigSendType" SG_ 2672226850 DiagUUDTRespSig5_F2_22_ISig_6 7;
BA_ "Platform_VMCU1_Sig" SG_ 2672226850 DiagUUDTRespSig5_F2_22_ISig_6 1;
BA_ "GenSigSendType" SG_ 2672226848 DiagUUDTRespSig5_F2_20_ISig_6 7;
BA_ "Platform_VMCU1_Sig" SG_ 2672226848 DiagUUDTRespSig5_F2_20_ISig_6 1;
BA_ "GenSigSendType" SG_ 2672161314 DiagUUDTRespSig4_F2_22_ISig_6 7;
BA_ "Platform_VMCU1_Sig" SG_ 2672161314 DiagUUDTRespSig4_F2_22_ISig_6 1;
BA_ "GenSigSendType" SG_ 2672161312 DiagUUDTRespSig4_F2_20_ISig_6 7;
BA_ "Platform_VMCU1_Sig" SG_ 2672161312 DiagUUDTRespSig4_F2_20_ISig_6 1;
BA_ "GenSigSendType" SG_ 2672095778 DiagUUDTRespSig3_F2_22_ISig_6 7;
BA_ "Platform_VMCU1_Sig" SG_ 2672095778 DiagUUDTRespSig3_F2_22_ISig_6 1;
BA_ "GenSigSendType" SG_ 2672095776 DiagUUDTRespSig3_F2_20_ISig_6 7;
BA_ "Platform_VMCU1_Sig" SG_ 2672095776 DiagUUDTRespSig3_F2_20_ISig_6 1;
BA_ "GenSigSendType" SG_ 2672030242 DiagUUDTRespSig2_F2_22_ISig_6 7;
BA_ "Platform_VMCU1_Sig" SG_ 2672030242 DiagUUDTRespSig2_F2_22_ISig_6 1;
BA_ "GenSigSendType" SG_ 2672030240 DiagUUDTRespSig2_F2_20_ISig_6 7;
BA_ "Platform_VMCU1_Sig" SG_ 2672030240 DiagUUDTRespSig2_F2_20_ISig_6 1;
BA_ "GenSigSendType" SG_ 2671964786 DiagUUDTRespSig_F2_72_ISig_6 7;
BA_ "GenSigSendType" SG_ 2671964785 DiagUUDTRespSig_F2_71_ISig_6 7;
BA_ "GenSigSendType" SG_ 2671964721 DiagUUDTRespSig_F2_31_ISig_6 7;
BA_ "Platform_VMCU1_Sig" SG_ 2671964721 DiagUUDTRespSig_F2_31_ISig_6 1;
BA_ "GenSigSendType" SG_ 2671964720 DiagUUDTRespSig_F2_30_ISig_6 7;
BA_ "Platform_VMCU1_Sig" SG_ 2671964720 DiagUUDTRespSig_F2_30_ISig_6 1;
BA_ "GenSigSendType" SG_ 2671964709 DiagUUDTRespSig_F2_25_ISig_6 7;
BA_ "Platform_VMCU1_Sig" SG_ 2671964709 DiagUUDTRespSig_F2_25_ISig_6 1;
BA_ "GenSigSendType" SG_ 2671964707 DiagUUDTRespSig_F2_23_ISig_6 7;
BA_ "Platform_VMCU1_Sig" SG_ 2671964707 DiagUUDTRespSig_F2_23_ISig_6 1;
BA_ "GenSigSendType" SG_ 2671964706 DiagUUDTRespSig_F2_22_ISig_6 7;
BA_ "Platform_VMCU1_Sig" SG_ 2671964706 DiagUUDTRespSig_F2_22_ISig_6 1;
BA_ "GenSigSendType" SG_ 2671964705 DiagUUDTRespSig_F2_21_ISig_6 7;
BA_ "Platform_VMCU1_Sig" SG_ 2671964705 DiagUUDTRespSig_F2_21_ISig_6 1;
BA_ "GenSigSendType" SG_ 2671964704 DiagUUDTRespSig_F2_20_ISig_6 7;
BA_ "Platform_VMCU1_Sig" SG_ 2671964704 DiagUUDTRespSig_F2_20_ISig_6 1;
BA_ "GenSigSendType" SG_ 2671964698 DiagUUDTRespSig_F2_1A_ISig_6 7;
BA_ "GenSigSendType" SG_ 2671834226 InternalTesterDiagSig_F4_72_ISig 7;
BA_ "SystemSignalLongSymbol" SG_ 2671834226 InternalTesterDiagSig_F4_72_ISig "InternalTesterDiagSig_F4_72_ISig_6";
BA_ "GenSigSendType" SG_ 2671834225 InternalTesterDiagSig_F4_71_ISig 7;
BA_ "SystemSignalLongSymbol" SG_ 2671834225 InternalTesterDiagSig_F4_71_ISig "InternalTesterDiagSig_F4_71_ISig_6";
BA_ "GenSigSendType" SG_ 2671834161 InternalTesterDiagSig_F4_31_ISig 7;
BA_ "Platform_VMCU1_Sig" SG_ 2671834161 InternalTesterDiagSig_F4_31_ISig 1;
BA_ "SystemSignalLongSymbol" SG_ 2671834161 InternalTesterDiagSig_F4_31_ISig "InternalTesterDiagSig_F4_31_ISig_6";
BA_ "GenSigSendType" SG_ 2671834160 InternalTesterDiagSig_F4_30_ISig 7;
BA_ "Platform_VMCU1_Sig" SG_ 2671834160 InternalTesterDiagSig_F4_30_ISig 1;
BA_ "SystemSignalLongSymbol" SG_ 2671834160 InternalTesterDiagSig_F4_30_ISig "InternalTesterDiagSig_F4_30_ISig_6";
BA_ "GenSigSendType" SG_ 2671834149 InternalTesterDiagSig_F4_25_ISig 7;
BA_ "Platform_VMCU1_Sig" SG_ 2671834149 InternalTesterDiagSig_F4_25_ISig 1;
BA_ "SystemSignalLongSymbol" SG_ 2671834149 InternalTesterDiagSig_F4_25_ISig "InternalTesterDiagSig_F4_25_ISig_6";
BA_ "GenSigSendType" SG_ 2671834147 InternalTesterDiagSig_F4_23_ISig 7;
BA_ "Platform_VMCU1_Sig" SG_ 2671834147 InternalTesterDiagSig_F4_23_ISig 1;
BA_ "SystemSignalLongSymbol" SG_ 2671834147 InternalTesterDiagSig_F4_23_ISig "InternalTesterDiagSig_F4_23_ISig_6";
BA_ "GenSigSendType" SG_ 2671834146 InternalTesterDiagSig_F4_22_ISig 7;
BA_ "Platform_VMCU1_Sig" SG_ 2671834146 InternalTesterDiagSig_F4_22_ISig 1;
BA_ "SystemSignalLongSymbol" SG_ 2671834146 InternalTesterDiagSig_F4_22_ISig "InternalTesterDiagSig_F4_22_ISig_6";
BA_ "GenSigSendType" SG_ 2671834145 InternalTesterDiagSig_F4_21_ISig 7;
BA_ "Platform_VMCU1_Sig" SG_ 2671834145 InternalTesterDiagSig_F4_21_ISig 1;
BA_ "SystemSignalLongSymbol" SG_ 2671834145 InternalTesterDiagSig_F4_21_ISig "InternalTesterDiagSig_F4_21_ISig_6";
BA_ "GenSigSendType" SG_ 2671834144 InternalTesterDiagSig_F4_20_ISig 7;
BA_ "Platform_VMCU1_Sig" SG_ 2671834144 InternalTesterDiagSig_F4_20_ISig 1;
BA_ "SystemSignalLongSymbol" SG_ 2671834144 InternalTesterDiagSig_F4_20_ISig "InternalTesterDiagSig_F4_20_ISig_6";
BA_ "GenSigSendType" SG_ 2671834138 InternalTesterDiagSig_F4_1A_ISig 7;
BA_ "SystemSignalLongSymbol" SG_ 2671834138 InternalTesterDiagSig_F4_1A_ISig "InternalTesterDiagSig_F4_1A_ISig_6";
BA_ "GenSigSendType" SG_ 2671833970 InternalTesterDiagSig_F3_72_ISig 7;
BA_ "SystemSignalLongSymbol" SG_ 2671833970 InternalTesterDiagSig_F3_72_ISig "InternalTesterDiagSig_F3_72_ISig_6";
BA_ "GenSigSendType" SG_ 2671833969 InternalTesterDiagSig_F3_71_ISig 7;
BA_ "SystemSignalLongSymbol" SG_ 2671833969 InternalTesterDiagSig_F3_71_ISig "InternalTesterDiagSig_F3_71_ISig_6";
BA_ "GenSigSendType" SG_ 2671833905 InternalTesterDiagSig_F3_31_ISig 7;
BA_ "Platform_VMCU1_Sig" SG_ 2671833905 InternalTesterDiagSig_F3_31_ISig 1;
BA_ "SystemSignalLongSymbol" SG_ 2671833905 InternalTesterDiagSig_F3_31_ISig "InternalTesterDiagSig_F3_31_ISig_6";
BA_ "GenSigSendType" SG_ 2671833904 InternalTesterDiagSig_F3_30_ISig 7;
BA_ "Platform_VMCU1_Sig" SG_ 2671833904 InternalTesterDiagSig_F3_30_ISig 1;
BA_ "SystemSignalLongSymbol" SG_ 2671833904 InternalTesterDiagSig_F3_30_ISig "InternalTesterDiagSig_F3_30_ISig_6";
BA_ "GenSigSendType" SG_ 2671833893 InternalTesterDiagSig_F3_25_ISig 7;
BA_ "Platform_VMCU1_Sig" SG_ 2671833893 InternalTesterDiagSig_F3_25_ISig 1;
BA_ "SystemSignalLongSymbol" SG_ 2671833893 InternalTesterDiagSig_F3_25_ISig "InternalTesterDiagSig_F3_25_ISig_6";
BA_ "GenSigSendType" SG_ 2671833891 InternalTesterDiagSig_F3_23_ISig 7;
BA_ "Platform_VMCU1_Sig" SG_ 2671833891 InternalTesterDiagSig_F3_23_ISig 1;
BA_ "SystemSignalLongSymbol" SG_ 2671833891 InternalTesterDiagSig_F3_23_ISig "InternalTesterDiagSig_F3_23_ISig_6";
BA_ "GenSigSendType" SG_ 2671833890 InternalTesterDiagSig_F3_22_ISig 7;
BA_ "Platform_VMCU1_Sig" SG_ 2671833890 InternalTesterDiagSig_F3_22_ISig 1;
BA_ "SystemSignalLongSymbol" SG_ 2671833890 InternalTesterDiagSig_F3_22_ISig "InternalTesterDiagSig_F3_22_ISig_6";
BA_ "GenSigSendType" SG_ 2671833889 InternalTesterDiagSig_F3_21_ISig 7;
BA_ "Platform_VMCU1_Sig" SG_ 2671833889 InternalTesterDiagSig_F3_21_ISig 1;
BA_ "SystemSignalLongSymbol" SG_ 2671833889 InternalTesterDiagSig_F3_21_ISig "InternalTesterDiagSig_F3_21_ISig_6";
BA_ "GenSigSendType" SG_ 2671833888 InternalTesterDiagSig_F3_20_ISig 7;
BA_ "Platform_VMCU1_Sig" SG_ 2671833888 InternalTesterDiagSig_F3_20_ISig 1;
BA_ "SystemSignalLongSymbol" SG_ 2671833888 InternalTesterDiagSig_F3_20_ISig "InternalTesterDiagSig_F3_20_ISig_6";
BA_ "GenSigSendType" SG_ 2671833882 InternalTesterDiagSig_F3_1A_ISig 7;
BA_ "SystemSignalLongSymbol" SG_ 2671833882 InternalTesterDiagSig_F3_1A_ISig "InternalTesterDiagSig_F3_1A_ISig_6";
BA_ "GenSigSendType" SG_ 2671801076 InternalTesterDiagSig_72_F4_ISig 7;
BA_ "SystemSignalLongSymbol" SG_ 2671801076 InternalTesterDiagSig_72_F4_ISig "InternalTesterDiagSig_72_F4_ISig_6";
BA_ "GenSigSendType" SG_ 2671800820 InternalTesterDiagSig_71_F4_ISig 7;
BA_ "SystemSignalLongSymbol" SG_ 2671800820 InternalTesterDiagSig_71_F4_ISig "InternalTesterDiagSig_71_F4_ISig_6";
BA_ "GenSigSendType" SG_ 2671784436 InternalTesterDiagSig_31_F4_ISig 7;
BA_ "Platform_VMCU1_Sig" SG_ 2671784436 InternalTesterDiagSig_31_F4_ISig 1;
BA_ "SystemSignalLongSymbol" SG_ 2671784436 InternalTesterDiagSig_31_F4_ISig "InternalTesterDiagSig_31_F4_ISig_6";
BA_ "GenSigSendType" SG_ 2671784180 InternalTesterDiagSig_30_F4_ISig 7;
BA_ "Platform_VMCU1_Sig" SG_ 2671784180 InternalTesterDiagSig_30_F4_ISig 1;
BA_ "SystemSignalLongSymbol" SG_ 2671784180 InternalTesterDiagSig_30_F4_ISig "InternalTesterDiagSig_30_F4_ISig_6";
BA_ "GenSigSendType" SG_ 2671781364 InternalTesterDiagSig_25_F4_ISig 7;
BA_ "Platform_VMCU1_Sig" SG_ 2671781364 InternalTesterDiagSig_25_F4_ISig 1;
BA_ "SystemSignalLongSymbol" SG_ 2671781364 InternalTesterDiagSig_25_F4_ISig "InternalTesterDiagSig_25_F4_ISig_6";
BA_ "GenSigSendType" SG_ 2671780852 InternalTesterDiagSig_23_F4_ISig 7;
BA_ "Platform_VMCU1_Sig" SG_ 2671780852 InternalTesterDiagSig_23_F4_ISig 1;
BA_ "SystemSignalLongSymbol" SG_ 2671780852 InternalTesterDiagSig_23_F4_ISig "InternalTesterDiagSig_23_F4_ISig_6";
BA_ "GenSigSendType" SG_ 2671780596 InternalTesterDiagSig_22_F4_ISig 7;
BA_ "Platform_VMCU1_Sig" SG_ 2671780596 InternalTesterDiagSig_22_F4_ISig 1;
BA_ "SystemSignalLongSymbol" SG_ 2671780596 InternalTesterDiagSig_22_F4_ISig "InternalTesterDiagSig_22_F4_ISig_6";
BA_ "GenSigSendType" SG_ 2671780340 InternalTesterDiagSig_21_F4_ISig 7;
BA_ "Platform_VMCU1_Sig" SG_ 2671780340 InternalTesterDiagSig_21_F4_ISig 1;
BA_ "SystemSignalLongSymbol" SG_ 2671780340 InternalTesterDiagSig_21_F4_ISig "InternalTesterDiagSig_21_F4_ISig_6";
BA_ "GenSigSendType" SG_ 2671780084 InternalTesterDiagSig_20_F4_ISig 7;
BA_ "Platform_VMCU1_Sig" SG_ 2671780084 InternalTesterDiagSig_20_F4_ISig 1;
BA_ "SystemSignalLongSymbol" SG_ 2671780084 InternalTesterDiagSig_20_F4_ISig "InternalTesterDiagSig_20_F4_ISig_6";
BA_ "GenSigSendType" SG_ 2671778548 InternalTesterDiagSig_1A_F4_ISig 7;
BA_ "SystemSignalLongSymbol" SG_ 2671778548 InternalTesterDiagSig_1A_F4_ISig "InternalTesterDiagSig_1A_F4_ISig_6";
BA_ "GenSigSendType" SG_ 2671801075 InternalTesterDiagSig_72_F3_ISig 7;
BA_ "SystemSignalLongSymbol" SG_ 2671801075 InternalTesterDiagSig_72_F3_ISig "InternalTesterDiagSig_72_F3_ISig_6";
BA_ "GenSigSendType" SG_ 2671800819 InternalTesterDiagSig_71_F3_ISig 7;
BA_ "SystemSignalLongSymbol" SG_ 2671800819 InternalTesterDiagSig_71_F3_ISig "InternalTesterDiagSig_71_F3_ISig_6";
BA_ "GenSigSendType" SG_ 2671784435 InternalTesterDiagSig_31_F3_ISig 7;
BA_ "Platform_VMCU1_Sig" SG_ 2671784435 InternalTesterDiagSig_31_F3_ISig 1;
BA_ "SystemSignalLongSymbol" SG_ 2671784435 InternalTesterDiagSig_31_F3_ISig "InternalTesterDiagSig_31_F3_ISig_6";
BA_ "GenSigSendType" SG_ 2671784179 InternalTesterDiagSig_30_F3_ISig 7;
BA_ "Platform_VMCU1_Sig" SG_ 2671784179 InternalTesterDiagSig_30_F3_ISig 1;
BA_ "SystemSignalLongSymbol" SG_ 2671784179 InternalTesterDiagSig_30_F3_ISig "InternalTesterDiagSig_30_F3_ISig_6";
BA_ "GenSigSendType" SG_ 2671781363 InternalTesterDiagSig_25_F3_ISig 7;
BA_ "Platform_VMCU1_Sig" SG_ 2671781363 InternalTesterDiagSig_25_F3_ISig 1;
BA_ "SystemSignalLongSymbol" SG_ 2671781363 InternalTesterDiagSig_25_F3_ISig "InternalTesterDiagSig_25_F3_ISig_6";
BA_ "GenSigSendType" SG_ 2671780851 InternalTesterDiagSig_23_F3_ISig 7;
BA_ "Platform_VMCU1_Sig" SG_ 2671780851 InternalTesterDiagSig_23_F3_ISig 1;
BA_ "SystemSignalLongSymbol" SG_ 2671780851 InternalTesterDiagSig_23_F3_ISig "InternalTesterDiagSig_23_F3_ISig_6";
BA_ "GenSigSendType" SG_ 2671780595 InternalTesterDiagSig_22_F3_ISig 7;
BA_ "Platform_VMCU1_Sig" SG_ 2671780595 InternalTesterDiagSig_22_F3_ISig 1;
BA_ "SystemSignalLongSymbol" SG_ 2671780595 InternalTesterDiagSig_22_F3_ISig "InternalTesterDiagSig_22_F3_ISig_6";
BA_ "GenSigSendType" SG_ 2671780339 InternalTesterDiagSig_21_F3_ISig 7;
BA_ "Platform_VMCU1_Sig" SG_ 2671780339 InternalTesterDiagSig_21_F3_ISig 1;
BA_ "SystemSignalLongSymbol" SG_ 2671780339 InternalTesterDiagSig_21_F3_ISig "InternalTesterDiagSig_21_F3_ISig_6";
BA_ "GenSigSendType" SG_ 2671780083 InternalTesterDiagSig_20_F3_ISig 7;
BA_ "Platform_VMCU1_Sig" SG_ 2671780083 InternalTesterDiagSig_20_F3_ISig 1;
BA_ "SystemSignalLongSymbol" SG_ 2671780083 InternalTesterDiagSig_20_F3_ISig "InternalTesterDiagSig_20_F3_ISig_6";
BA_ "GenSigSendType" SG_ 2671778547 InternalTesterDiagSig_1A_F3_ISig 7;
BA_ "SystemSignalLongSymbol" SG_ 2671778547 InternalTesterDiagSig_1A_F3_ISig "InternalTesterDiagSig_1A_F3_ISig_6";
BA_ "GenSigSendType" SG_ 1502 DiagFaultStat_TPM_FailTB_ISig_6 3;
BA_ "NeedsUpdateBit" SG_ 1502 DiagFaultStat_TPM_FailTB_ISig_6 1;
BA_ "Platform_VMCU1_Sig" SG_ 1502 DiagFaultStat_TPM_FailTB_ISig_6 1;
BA_ "GenSigSendType" SG_ 1502 DiagFaultStat_TPM_EcuAdr_ISig_6 3;
BA_ "GenSigStartValue" SG_ 1502 DiagFaultStat_TPM_EcuAdr_ISig_6 255;
BA_ "NeedsUpdateBit" SG_ 1502 DiagFaultStat_TPM_EcuAdr_ISig_6 1;
BA_ "Platform_VMCU1_Sig" SG_ 1502 DiagFaultStat_TPM_EcuAdr_ISig_6 1;
BA_ "GenSigSendType" SG_ 1502 DiagFaultStat_TPM_DtcIdA_ISig_6 3;
BA_ "NeedsUpdateBit" SG_ 1502 DiagFaultStat_TPM_DtcIdA_ISig_6 1;
BA_ "Platform_VMCU1_Sig" SG_ 1502 DiagFaultStat_TPM_DtcIdA_ISig_6 1;
BA_ "GenSigSendType" SG_ 1502 DiagFaultStat_TPM_FailTA_ISig_6 3;
BA_ "NeedsUpdateBit" SG_ 1502 DiagFaultStat_TPM_FailTA_ISig_6 1;
BA_ "Platform_VMCU1_Sig" SG_ 1502 DiagFaultStat_TPM_FailTA_ISig_6 1;
BA_ "GenSigSendType" SG_ 1502 DiagFaultStat_TPM_sg_UB_ISig_6 7;
BA_ "Platform_VMCU1_Sig" SG_ 1502 DiagFaultStat_TPM_sg_UB_ISig_6 1;
BA_ "GenSigSendType" SG_ 1502 DiagFaultStat_TPM_DtcIdB_ISig_6 3;
BA_ "NeedsUpdateBit" SG_ 1502 DiagFaultStat_TPM_DtcIdB_ISig_6 1;
BA_ "Platform_VMCU1_Sig" SG_ 1502 DiagFaultStat_TPM_DtcIdB_ISig_6 1;
BA_ "GenSigSendType" SG_ 1500 DiagFaultStat_RCIOM_FailTA_ISig_ 3;
BA_ "NeedsUpdateBit" SG_ 1500 DiagFaultStat_RCIOM_FailTA_ISig_ 1;
BA_ "Platform_VMCU1_Sig" SG_ 1500 DiagFaultStat_RCIOM_FailTA_ISig_ 1;
BA_ "SystemSignalLongSymbol" SG_ 1500 DiagFaultStat_RCIOM_FailTA_ISig_ "DiagFaultStat_RCIOM_FailTA_ISig_6";
BA_ "GenSigSendType" SG_ 1500 DiagFaultStat_RCIOM_FailTB_ISig_ 3;
BA_ "NeedsUpdateBit" SG_ 1500 DiagFaultStat_RCIOM_FailTB_ISig_ 1;
BA_ "Platform_VMCU1_Sig" SG_ 1500 DiagFaultStat_RCIOM_FailTB_ISig_ 1;
BA_ "SystemSignalLongSymbol" SG_ 1500 DiagFaultStat_RCIOM_FailTB_ISig_ "DiagFaultStat_RCIOM_FailTB_ISig_6";
BA_ "GenSigSendType" SG_ 1500 DiagFaultStat_RCIOM_DtcIdA_ISig_ 3;
BA_ "NeedsUpdateBit" SG_ 1500 DiagFaultStat_RCIOM_DtcIdA_ISig_ 1;
BA_ "Platform_VMCU1_Sig" SG_ 1500 DiagFaultStat_RCIOM_DtcIdA_ISig_ 1;
BA_ "SystemSignalLongSymbol" SG_ 1500 DiagFaultStat_RCIOM_DtcIdA_ISig_ "DiagFaultStat_RCIOM_DtcIdA_ISig_6";
BA_ "GenSigSendType" SG_ 1500 DiagFaultStat_RCIOM_sg_UB_ISig_6 7;
BA_ "Platform_VMCU1_Sig" SG_ 1500 DiagFaultStat_RCIOM_sg_UB_ISig_6 1;
BA_ "GenSigSendType" SG_ 1500 DiagFaultStat_RCIOM_DtcIdB_ISig_ 3;
BA_ "NeedsUpdateBit" SG_ 1500 DiagFaultStat_RCIOM_DtcIdB_ISig_ 1;
BA_ "Platform_VMCU1_Sig" SG_ 1500 DiagFaultStat_RCIOM_DtcIdB_ISig_ 1;
BA_ "SystemSignalLongSymbol" SG_ 1500 DiagFaultStat_RCIOM_DtcIdB_ISig_ "DiagFaultStat_RCIOM_DtcIdB_ISig_6";
BA_ "GenSigSendType" SG_ 1500 DiagFaultStat_RCIOM_EcuAdr_ISig_ 3;
BA_ "GenSigStartValue" SG_ 1500 DiagFaultStat_RCIOM_EcuAdr_ISig_ 255;
BA_ "NeedsUpdateBit" SG_ 1500 DiagFaultStat_RCIOM_EcuAdr_ISig_ 1;
BA_ "Platform_VMCU1_Sig" SG_ 1500 DiagFaultStat_RCIOM_EcuAdr_ISig_ 1;
BA_ "SystemSignalLongSymbol" SG_ 1500 DiagFaultStat_RCIOM_EcuAdr_ISig_ "DiagFaultStat_RCIOM_EcuAdr_ISig_6";
BA_ "GenSigSendType" SG_ 1497 DiagFaultStat_GFHCM2_FailTB_ISig 3;
BA_ "NeedsUpdateBit" SG_ 1497 DiagFaultStat_GFHCM2_FailTB_ISig 1;
BA_ "SystemSignalLongSymbol" SG_ 1497 DiagFaultStat_GFHCM2_FailTB_ISig "DiagFaultStat_GFHCM2_FailTB_ISig_6";
BA_ "GenSigSendType" SG_ 1497 DiagFaultStat_GFHCM2_EcuAdr_ISig 3;
BA_ "GenSigStartValue" SG_ 1497 DiagFaultStat_GFHCM2_EcuAdr_ISig 255;
BA_ "NeedsUpdateBit" SG_ 1497 DiagFaultStat_GFHCM2_EcuAdr_ISig 1;
BA_ "SystemSignalLongSymbol" SG_ 1497 DiagFaultStat_GFHCM2_EcuAdr_ISig "DiagFaultStat_GFHCM2_EcuAdr_ISig_6";
BA_ "GenSigSendType" SG_ 1497 DiagFaultStat_GFHCM2_FailTA_ISig 3;
BA_ "NeedsUpdateBit" SG_ 1497 DiagFaultStat_GFHCM2_FailTA_ISig 1;
BA_ "SystemSignalLongSymbol" SG_ 1497 DiagFaultStat_GFHCM2_FailTA_ISig "DiagFaultStat_GFHCM2_FailTA_ISig_6";
BA_ "GenSigSendType" SG_ 1497 DiagFaultStat_GFHCM2_DtcIdA_ISig 3;
BA_ "NeedsUpdateBit" SG_ 1497 DiagFaultStat_GFHCM2_DtcIdA_ISig 1;
BA_ "SystemSignalLongSymbol" SG_ 1497 DiagFaultStat_GFHCM2_DtcIdA_ISig "DiagFaultStat_GFHCM2_DtcIdA_ISig_6";
BA_ "GenSigSendType" SG_ 1497 DiagFaultStat_GFHCM2_sg_UB_ISig_ 7;
BA_ "SystemSignalLongSymbol" SG_ 1497 DiagFaultStat_GFHCM2_sg_UB_ISig_ "DiagFaultStat_GFHCM2_sg_UB_ISig_6";
BA_ "GenSigSendType" SG_ 1497 DiagFaultStat_GFHCM2_DtcIdB_ISig 3;
BA_ "NeedsUpdateBit" SG_ 1497 DiagFaultStat_GFHCM2_DtcIdB_ISig 1;
BA_ "SystemSignalLongSymbol" SG_ 1497 DiagFaultStat_GFHCM2_DtcIdB_ISig "DiagFaultStat_GFHCM2_DtcIdB_ISig_6";
BA_ "GenSigSendType" SG_ 1496 DiagFaultStat_GFHCM1_EcuAdr_ISig 3;
BA_ "GenSigStartValue" SG_ 1496 DiagFaultStat_GFHCM1_EcuAdr_ISig 255;
BA_ "NeedsUpdateBit" SG_ 1496 DiagFaultStat_GFHCM1_EcuAdr_ISig 1;
BA_ "SystemSignalLongSymbol" SG_ 1496 DiagFaultStat_GFHCM1_EcuAdr_ISig "DiagFaultStat_GFHCM1_EcuAdr_ISig_6";
BA_ "GenSigSendType" SG_ 1496 DiagFaultStat_GFHCM1_FailTB_ISig 3;
BA_ "NeedsUpdateBit" SG_ 1496 DiagFaultStat_GFHCM1_FailTB_ISig 1;
BA_ "SystemSignalLongSymbol" SG_ 1496 DiagFaultStat_GFHCM1_FailTB_ISig "DiagFaultStat_GFHCM1_FailTB_ISig_6";
BA_ "GenSigSendType" SG_ 1496 DiagFaultStat_GFHCM1_DtcIdA_ISig 3;
BA_ "NeedsUpdateBit" SG_ 1496 DiagFaultStat_GFHCM1_DtcIdA_ISig 1;
BA_ "SystemSignalLongSymbol" SG_ 1496 DiagFaultStat_GFHCM1_DtcIdA_ISig "DiagFaultStat_GFHCM1_DtcIdA_ISig_6";
BA_ "GenSigSendType" SG_ 1496 DiagFaultStat_GFHCM1_sg_UB_ISig_ 7;
BA_ "SystemSignalLongSymbol" SG_ 1496 DiagFaultStat_GFHCM1_sg_UB_ISig_ "DiagFaultStat_GFHCM1_sg_UB_ISig_6";
BA_ "GenSigSendType" SG_ 1496 DiagFaultStat_GFHCM1_DtcIdB_ISig 3;
BA_ "NeedsUpdateBit" SG_ 1496 DiagFaultStat_GFHCM1_DtcIdB_ISig 1;
BA_ "SystemSignalLongSymbol" SG_ 1496 DiagFaultStat_GFHCM1_DtcIdB_ISig "DiagFaultStat_GFHCM1_DtcIdB_ISig_6";
BA_ "GenSigSendType" SG_ 1496 DiagFaultStat_GFHCM1_FailTA_ISig 3;
BA_ "NeedsUpdateBit" SG_ 1496 DiagFaultStat_GFHCM1_FailTA_ISig 1;
BA_ "SystemSignalLongSymbol" SG_ 1496 DiagFaultStat_GFHCM1_FailTA_ISig "DiagFaultStat_GFHCM1_FailTA_ISig_6";
BA_ "GenSigSendType" SG_ 1499 DiagFaultStat_FCIOM_DtcIdA_ISig_ 3;
BA_ "NeedsUpdateBit" SG_ 1499 DiagFaultStat_FCIOM_DtcIdA_ISig_ 1;
BA_ "Platform_VMCU1_Sig" SG_ 1499 DiagFaultStat_FCIOM_DtcIdA_ISig_ 1;
BA_ "SystemSignalLongSymbol" SG_ 1499 DiagFaultStat_FCIOM_DtcIdA_ISig_ "DiagFaultStat_FCIOM_DtcIdA_ISig_6";
BA_ "GenSigSendType" SG_ 1499 DiagFaultStat_FCIOM_sg_UB_ISig_6 7;
BA_ "Platform_VMCU1_Sig" SG_ 1499 DiagFaultStat_FCIOM_sg_UB_ISig_6 1;
BA_ "GenSigSendType" SG_ 1499 DiagFaultStat_FCIOM_FailTB_ISig_ 3;
BA_ "NeedsUpdateBit" SG_ 1499 DiagFaultStat_FCIOM_FailTB_ISig_ 1;
BA_ "Platform_VMCU1_Sig" SG_ 1499 DiagFaultStat_FCIOM_FailTB_ISig_ 1;
BA_ "SystemSignalLongSymbol" SG_ 1499 DiagFaultStat_FCIOM_FailTB_ISig_ "DiagFaultStat_FCIOM_FailTB_ISig_6";
BA_ "GenSigSendType" SG_ 1499 DiagFaultStat_FCIOM_EcuAdr_ISig_ 3;
BA_ "GenSigStartValue" SG_ 1499 DiagFaultStat_FCIOM_EcuAdr_ISig_ 255;
BA_ "NeedsUpdateBit" SG_ 1499 DiagFaultStat_FCIOM_EcuAdr_ISig_ 1;
BA_ "Platform_VMCU1_Sig" SG_ 1499 DiagFaultStat_FCIOM_EcuAdr_ISig_ 1;
BA_ "SystemSignalLongSymbol" SG_ 1499 DiagFaultStat_FCIOM_EcuAdr_ISig_ "DiagFaultStat_FCIOM_EcuAdr_ISig_6";
BA_ "GenSigSendType" SG_ 1499 DiagFaultStat_FCIOM_FailTA_ISig_ 3;
BA_ "NeedsUpdateBit" SG_ 1499 DiagFaultStat_FCIOM_FailTA_ISig_ 1;
BA_ "Platform_VMCU1_Sig" SG_ 1499 DiagFaultStat_FCIOM_FailTA_ISig_ 1;
BA_ "SystemSignalLongSymbol" SG_ 1499 DiagFaultStat_FCIOM_FailTA_ISig_ "DiagFaultStat_FCIOM_FailTA_ISig_6";
BA_ "GenSigSendType" SG_ 1499 DiagFaultStat_FCIOM_DtcIdB_ISig_ 3;
BA_ "NeedsUpdateBit" SG_ 1499 DiagFaultStat_FCIOM_DtcIdB_ISig_ 1;
BA_ "Platform_VMCU1_Sig" SG_ 1499 DiagFaultStat_FCIOM_DtcIdB_ISig_ 1;
BA_ "SystemSignalLongSymbol" SG_ 1499 DiagFaultStat_FCIOM_DtcIdB_ISig_ "DiagFaultStat_FCIOM_DtcIdB_ISig_6";
BA_ "GenSigSendType" SG_ 1491 DiagFaultStat_FAS_FailTA_ISig_6 3;
BA_ "NeedsUpdateBit" SG_ 1491 DiagFaultStat_FAS_FailTA_ISig_6 1;
BA_ "Platform_VMCU1_Sig" SG_ 1491 DiagFaultStat_FAS_FailTA_ISig_6 1;
BA_ "GenSigSendType" SG_ 1491 DiagFaultStat_FAS_DtcIdA_ISig_6 3;
BA_ "NeedsUpdateBit" SG_ 1491 DiagFaultStat_FAS_DtcIdA_ISig_6 1;
BA_ "Platform_VMCU1_Sig" SG_ 1491 DiagFaultStat_FAS_DtcIdA_ISig_6 1;
BA_ "GenSigSendType" SG_ 1491 DiagFaultStat_FAS_EcuAdr_ISig_6 3;
BA_ "GenSigStartValue" SG_ 1491 DiagFaultStat_FAS_EcuAdr_ISig_6 255;
BA_ "NeedsUpdateBit" SG_ 1491 DiagFaultStat_FAS_EcuAdr_ISig_6 1;
BA_ "Platform_VMCU1_Sig" SG_ 1491 DiagFaultStat_FAS_EcuAdr_ISig_6 1;
BA_ "GenSigSendType" SG_ 1491 DiagFaultStat_FAS_sg_UB_ISig_6 7;
BA_ "Platform_VMCU1_Sig" SG_ 1491 DiagFaultStat_FAS_sg_UB_ISig_6 1;
BA_ "GenSigSendType" SG_ 1491 DiagFaultStat_FAS_FailTB_ISig_6 3;
BA_ "NeedsUpdateBit" SG_ 1491 DiagFaultStat_FAS_FailTB_ISig_6 1;
BA_ "Platform_VMCU1_Sig" SG_ 1491 DiagFaultStat_FAS_FailTB_ISig_6 1;
BA_ "GenSigSendType" SG_ 1491 DiagFaultStat_FAS_DtcIdB_ISig_6 3;
BA_ "NeedsUpdateBit" SG_ 1491 DiagFaultStat_FAS_DtcIdB_ISig_6 1;
BA_ "Platform_VMCU1_Sig" SG_ 1491 DiagFaultStat_FAS_DtcIdB_ISig_6 1;
BA_ "GenSigSendType" SG_ 1493 DiagFaultStat_EAS_FailTA_ISig_6 3;
BA_ "NeedsUpdateBit" SG_ 1493 DiagFaultStat_EAS_FailTA_ISig_6 1;
BA_ "Platform_VMCU1_Sig" SG_ 1493 DiagFaultStat_EAS_FailTA_ISig_6 1;
BA_ "GenSigSendType" SG_ 1493 DiagFaultStat_EAS_sg_UB_ISig_6 7;
BA_ "Platform_VMCU1_Sig" SG_ 1493 DiagFaultStat_EAS_sg_UB_ISig_6 1;
BA_ "GenSigSendType" SG_ 1493 DiagFaultStat_EAS_FailTB_ISig_6 3;
BA_ "NeedsUpdateBit" SG_ 1493 DiagFaultStat_EAS_FailTB_ISig_6 1;
BA_ "Platform_VMCU1_Sig" SG_ 1493 DiagFaultStat_EAS_FailTB_ISig_6 1;
BA_ "GenSigSendType" SG_ 1493 DiagFaultStat_EAS_EcuAdr_ISig_6 3;
BA_ "GenSigStartValue" SG_ 1493 DiagFaultStat_EAS_EcuAdr_ISig_6 255;
BA_ "NeedsUpdateBit" SG_ 1493 DiagFaultStat_EAS_EcuAdr_ISig_6 1;
BA_ "Platform_VMCU1_Sig" SG_ 1493 DiagFaultStat_EAS_EcuAdr_ISig_6 1;
BA_ "GenSigSendType" SG_ 1493 DiagFaultStat_EAS_DtcIdA_ISig_6 3;
BA_ "NeedsUpdateBit" SG_ 1493 DiagFaultStat_EAS_DtcIdA_ISig_6 1;
BA_ "Platform_VMCU1_Sig" SG_ 1493 DiagFaultStat_EAS_DtcIdA_ISig_6 1;
BA_ "GenSigSendType" SG_ 1493 DiagFaultStat_EAS_DtcIdB_ISig_6 3;
BA_ "NeedsUpdateBit" SG_ 1493 DiagFaultStat_EAS_DtcIdB_ISig_6 1;
BA_ "Platform_VMCU1_Sig" SG_ 1493 DiagFaultStat_EAS_DtcIdB_ISig_6 1;
BA_ "GenSigSendType" SG_ 1490 DiagFaultStat_CCIOM_FailTB_ISig_ 3;
BA_ "NeedsUpdateBit" SG_ 1490 DiagFaultStat_CCIOM_FailTB_ISig_ 1;
BA_ "Platform_VMCU1_Sig" SG_ 1490 DiagFaultStat_CCIOM_FailTB_ISig_ 1;
BA_ "SystemSignalLongSymbol" SG_ 1490 DiagFaultStat_CCIOM_FailTB_ISig_ "DiagFaultStat_CCIOM_FailTB_ISig_6";
BA_ "GenSigSendType" SG_ 1490 DiagFaultStat_CCIOM_DtcIdB_ISig_ 3;
BA_ "NeedsUpdateBit" SG_ 1490 DiagFaultStat_CCIOM_DtcIdB_ISig_ 1;
BA_ "Platform_VMCU1_Sig" SG_ 1490 DiagFaultStat_CCIOM_DtcIdB_ISig_ 1;
BA_ "SystemSignalLongSymbol" SG_ 1490 DiagFaultStat_CCIOM_DtcIdB_ISig_ "DiagFaultStat_CCIOM_DtcIdB_ISig_6";
BA_ "GenSigSendType" SG_ 1490 DiagFaultStat_CCIOM_EcuAdr_ISig_ 3;
BA_ "GenSigStartValue" SG_ 1490 DiagFaultStat_CCIOM_EcuAdr_ISig_ 255;
BA_ "NeedsUpdateBit" SG_ 1490 DiagFaultStat_CCIOM_EcuAdr_ISig_ 1;
BA_ "Platform_VMCU1_Sig" SG_ 1490 DiagFaultStat_CCIOM_EcuAdr_ISig_ 1;
BA_ "SystemSignalLongSymbol" SG_ 1490 DiagFaultStat_CCIOM_EcuAdr_ISig_ "DiagFaultStat_CCIOM_EcuAdr_ISig_6";
BA_ "GenSigSendType" SG_ 1490 DiagFaultStat_CCIOM_sg_UB_ISig_6 7;
BA_ "Platform_VMCU1_Sig" SG_ 1490 DiagFaultStat_CCIOM_sg_UB_ISig_6 1;
BA_ "GenSigSendType" SG_ 1490 DiagFaultStat_CCIOM_FailTA_ISig_ 3;
BA_ "NeedsUpdateBit" SG_ 1490 DiagFaultStat_CCIOM_FailTA_ISig_ 1;
BA_ "Platform_VMCU1_Sig" SG_ 1490 DiagFaultStat_CCIOM_FailTA_ISig_ 1;
BA_ "SystemSignalLongSymbol" SG_ 1490 DiagFaultStat_CCIOM_FailTA_ISig_ "DiagFaultStat_CCIOM_FailTA_ISig_6";
BA_ "GenSigSendType" SG_ 1490 DiagFaultStat_CCIOM_DtcIdA_ISig_ 3;
BA_ "NeedsUpdateBit" SG_ 1490 DiagFaultStat_CCIOM_DtcIdA_ISig_ 1;
BA_ "Platform_VMCU1_Sig" SG_ 1490 DiagFaultStat_CCIOM_DtcIdA_ISig_ 1;
BA_ "SystemSignalLongSymbol" SG_ 1490 DiagFaultStat_CCIOM_DtcIdA_ISig_ "DiagFaultStat_CCIOM_DtcIdA_ISig_6";
BA_ "GenSigSendType" SG_ 1494 DiagFaultStat_BPMU_DtcIdB_ISig_6 3;
BA_ "NeedsUpdateBit" SG_ 1494 DiagFaultStat_BPMU_DtcIdB_ISig_6 1;
BA_ "GenSigSendType" SG_ 1494 DiagFaultStat_BPMU_EcuAdr_ISig_6 3;
BA_ "GenSigStartValue" SG_ 1494 DiagFaultStat_BPMU_EcuAdr_ISig_6 255;
BA_ "NeedsUpdateBit" SG_ 1494 DiagFaultStat_BPMU_EcuAdr_ISig_6 1;
BA_ "GenSigSendType" SG_ 1494 DiagFaultStat_BPMU_FailTA_ISig_6 3;
BA_ "NeedsUpdateBit" SG_ 1494 DiagFaultStat_BPMU_FailTA_ISig_6 1;
BA_ "GenSigSendType" SG_ 1494 DiagFaultStat_BPMU_FailTB_ISig_6 3;
BA_ "NeedsUpdateBit" SG_ 1494 DiagFaultStat_BPMU_FailTB_ISig_6 1;
BA_ "GenSigSendType" SG_ 1494 DiagFaultStat_BPMU_DtcIdA_ISig_6 3;
BA_ "NeedsUpdateBit" SG_ 1494 DiagFaultStat_BPMU_DtcIdA_ISig_6 1;
BA_ "GenSigSendType" SG_ 1494 DiagFaultStat_BPMU_sg_UB_ISig_6 7;
BA_ "GenSigSendType" SG_ 1489 DiagFaultStat_APM_FailTB_ISig_6 3;
BA_ "NeedsUpdateBit" SG_ 1489 DiagFaultStat_APM_FailTB_ISig_6 1;
BA_ "Platform_VMCU1_Sig" SG_ 1489 DiagFaultStat_APM_FailTB_ISig_6 1;
BA_ "GenSigSendType" SG_ 1489 DiagFaultStat_APM_EcuAdr_ISig_6 3;
BA_ "GenSigStartValue" SG_ 1489 DiagFaultStat_APM_EcuAdr_ISig_6 255;
BA_ "NeedsUpdateBit" SG_ 1489 DiagFaultStat_APM_EcuAdr_ISig_6 1;
BA_ "Platform_VMCU1_Sig" SG_ 1489 DiagFaultStat_APM_EcuAdr_ISig_6 1;
BA_ "GenSigSendType" SG_ 1489 DiagFaultStat_APM_FailTA_ISig_6 3;
BA_ "NeedsUpdateBit" SG_ 1489 DiagFaultStat_APM_FailTA_ISig_6 1;
BA_ "Platform_VMCU1_Sig" SG_ 1489 DiagFaultStat_APM_FailTA_ISig_6 1;
BA_ "GenSigSendType" SG_ 1489 DiagFaultStat_APM_DtcIdA_ISig_6 3;
BA_ "NeedsUpdateBit" SG_ 1489 DiagFaultStat_APM_DtcIdA_ISig_6 1;
BA_ "Platform_VMCU1_Sig" SG_ 1489 DiagFaultStat_APM_DtcIdA_ISig_6 1;
BA_ "GenSigSendType" SG_ 1489 DiagFaultStat_APM_DtcIdB_ISig_6 3;
BA_ "NeedsUpdateBit" SG_ 1489 DiagFaultStat_APM_DtcIdB_ISig_6 1;
BA_ "Platform_VMCU1_Sig" SG_ 1489 DiagFaultStat_APM_DtcIdB_ISig_6 1;
BA_ "GenSigSendType" SG_ 1489 DiagFaultStat_APM_sg_UB_ISig_6 7;
BA_ "Platform_VMCU1_Sig" SG_ 1489 DiagFaultStat_APM_sg_UB_ISig_6 1;
BA_ "GenSigSendType" SG_ 1952 Debug_9_RCIOM 1;
BA_ "GenSigMaxLatency" SG_ 1952 Debug_9_RCIOM 59;
BA_ "Platform_VMCU1_Sig" SG_ 1952 Debug_9_RCIOM 1;
BA_ "GenSigSendType" SG_ 1954 Debug_9_FAS 1;
BA_ "GenSigMaxLatency" SG_ 1954 Debug_9_FAS 59;
BA_ "Platform_VMCU1_Sig" SG_ 1954 Debug_9_FAS 1;
BA_ "GenSigSendType" SG_ 1951 Debug_9_CCIOM 1;
BA_ "GenSigMaxLatency" SG_ 1951 Debug_9_CCIOM 59;
BA_ "Platform_VMCU1_Sig" SG_ 1951 Debug_9_CCIOM 1;
BA_ "GenSigSendType" SG_ 1950 Debug_9_BPMU 1;
BA_ "Platform_VMCU1_Sig" SG_ 1950 Debug_9_BPMU 1;
BA_ "GenSigSendType" SG_ 1953 Debug_9_APM 1;
BA_ "GenSigMaxLatency" SG_ 1953 Debug_9_APM 55;
BA_ "Platform_VMCU1_Sig" SG_ 1953 Debug_9_APM 1;
BA_ "GenSigSendType" SG_ 1947 Debug_8_RCIOM 1;
BA_ "GenSigMaxLatency" SG_ 1947 Debug_8_RCIOM 59;
BA_ "Platform_VMCU1_Sig" SG_ 1947 Debug_8_RCIOM 1;
BA_ "GenSigSendType" SG_ 1949 Debug_8_FAS 1;
BA_ "Platform_VMCU1_Sig" SG_ 1949 Debug_8_FAS 1;
BA_ "GenSigSendType" SG_ 1946 Debug_8_CCIOM 1;
BA_ "GenSigMaxLatency" SG_ 1946 Debug_8_CCIOM 59;
BA_ "Platform_VMCU1_Sig" SG_ 1946 Debug_8_CCIOM 1;
BA_ "GenSigSendType" SG_ 1945 Debug_8_BPMU 1;
BA_ "Platform_VMCU1_Sig" SG_ 1945 Debug_8_BPMU 1;
BA_ "GenSigSendType" SG_ 1948 Debug_8_APM 1;
BA_ "GenSigMaxLatency" SG_ 1948 Debug_8_APM 55;
BA_ "Platform_VMCU1_Sig" SG_ 1948 Debug_8_APM 1;
BA_ "GenSigSendType" SG_ 1942 Debug_7_RCIOM 1;
BA_ "GenSigMaxLatency" SG_ 1942 Debug_7_RCIOM 59;
BA_ "Platform_VMCU1_Sig" SG_ 1942 Debug_7_RCIOM 1;
BA_ "GenSigSendType" SG_ 1944 Debug_7_FAS 1;
BA_ "Platform_VMCU1_Sig" SG_ 1944 Debug_7_FAS 1;
BA_ "GenSigSendType" SG_ 1941 Debug_7_CCIOM 1;
BA_ "GenSigMaxLatency" SG_ 1941 Debug_7_CCIOM 59;
BA_ "Platform_VMCU1_Sig" SG_ 1941 Debug_7_CCIOM 1;
BA_ "GenSigSendType" SG_ 1940 Debug_7_BPMU 1;
BA_ "Platform_VMCU1_Sig" SG_ 1940 Debug_7_BPMU 1;
BA_ "GenSigSendType" SG_ 1943 Debug_7_APM 1;
BA_ "GenSigMaxLatency" SG_ 1943 Debug_7_APM 55;
BA_ "Platform_VMCU1_Sig" SG_ 1943 Debug_7_APM 1;
BA_ "GenSigSendType" SG_ 1937 Debug_6_TPM 1;
BA_ "GenSigMaxLatency" SG_ 1937 Debug_6_TPM 59;
BA_ "Platform_VMCU1_Sig" SG_ 1937 Debug_6_TPM 1;
BA_ "GenSigSendType" SG_ 1935 Debug_6_RCIOM 1;
BA_ "GenSigMaxLatency" SG_ 1935 Debug_6_RCIOM 58;
BA_ "Platform_VMCU1_Sig" SG_ 1935 Debug_6_RCIOM 1;
BA_REL_ "GenSigFirstTimeoutTime" BU_SG_REL_ VMCU SG_ 952 DirIndSideLamp1_stat 3000;
BA_REL_ "GenSigTimeoutTime" BU_SG_REL_ VMCU SG_ 952 DirIndSideLamp1_stat 300;
BA_REL_ "GenSigFirstTimeoutTime" BU_SG_REL_ VMCU SG_ 952 MainBeamLamp_stat_ISig_6 3000;
BA_REL_ "GenSigTimeoutTime" BU_SG_REL_ VMCU SG_ 952 MainBeamLamp_stat_ISig_6 300;
BA_REL_ "GenSigFirstTimeoutTime" BU_SG_REL_ VMCU SG_ 952 FogLamp_Front_Status 3000;
BA_REL_ "GenSigTimeoutTime" BU_SG_REL_ VMCU SG_ 952 FogLamp_Front_Status 300;
BA_REL_ "GenSigFirstTimeoutTime" BU_SG_REL_ VMCU SG_ 952 DirInd_Front_Status_ISig_6 3000;
BA_REL_ "GenSigTimeoutTime" BU_SG_REL_ VMCU SG_ 952 DirInd_Front_Status_ISig_6 300;
BA_REL_ "GenSigFirstTimeoutTime" BU_SG_REL_ VMCU SG_ 952 AuxLamp_Front_Status 3000;
BA_REL_ "GenSigTimeoutTime" BU_SG_REL_ VMCU SG_ 952 AuxLamp_Front_Status 300;
BA_REL_ "GenSigFirstTimeoutTime" BU_SG_REL_ VMCU SG_ 952 WasherFluidLevel_ISig_6 3000;
BA_REL_ "GenSigTimeoutTime" BU_SG_REL_ VMCU SG_ 952 WasherFluidLevel_ISig_6 300;
BA_REL_ "GenSigFirstTimeoutTime" BU_SG_REL_ VMCU SG_ 952 StaticCornerLightLamp_stat_ISig_ 3000;
BA_REL_ "GenSigTimeoutTime" BU_SG_REL_ VMCU SG_ 952 StaticCornerLightLamp_stat_ISig_ 300;
BA_REL_ "GenSigFirstTimeoutTime" BU_SG_REL_ VMCU SG_ 952 DippedBeamLamp_stat_ISig_6 3000;
BA_REL_ "GenSigTimeoutTime" BU_SG_REL_ VMCU SG_ 952 DippedBeamLamp_stat_ISig_6 300;
BA_REL_ "GenSigFirstTimeoutTime" BU_SG_REL_ VMCU SG_ 952 ChassiInstepLightsLamp_stat_ISig 3000;
BA_REL_ "GenSigTimeoutTime" BU_SG_REL_ VMCU SG_ 952 ChassiInstepLightsLamp_stat_ISig 300;
BA_REL_ "GenSigFirstTimeoutTime" BU_SG_REL_ VMCU SG_ 952 ExtraMainBeamLamp_stat_ISig_6 3000;
BA_REL_ "GenSigTimeoutTime" BU_SG_REL_ VMCU SG_ 952 ExtraMainBeamLamp_stat_ISig_6 300;
BA_REL_ "GenSigFirstTimeoutTime" BU_SG_REL_ VMCU SG_ 952 AuxFogLightLamp_stat_ISig_6 3000;
BA_REL_ "GenSigTimeoutTime" BU_SG_REL_ VMCU SG_ 952 AuxFogLightLamp_stat_ISig_6 300;
BA_REL_ "GenSigFirstTimeoutTime" BU_SG_REL_ VMCU SG_ 952 PositionLightLamp_stat_ISig_6 3000;
BA_REL_ "GenSigTimeoutTime" BU_SG_REL_ VMCU SG_ 952 PositionLightLamp_stat_ISig_6 300;
BA_REL_ "GenSigFirstTimeoutTime" BU_SG_REL_ VMCU SG_ 952 AmbientAirTemperature1 3000;
BA_REL_ "GenSigTimeoutTime" BU_SG_REL_ VMCU SG_ 952 AmbientAirTemperature1 300;
BA_REL_ "GenSigFirstTimeoutTime" BU_SG_REL_ VMCU SG_ 952 FogLightFrontLamp_stat_ISig_6 3000;
BA_REL_ "GenSigTimeoutTime" BU_SG_REL_ VMCU SG_ 952 FogLightFrontLamp_stat_ISig_6 300;
BA_REL_ "GenSigFirstTimeoutTime" BU_SG_REL_ VMCU SG_ 952 DRLLamp_stat_ISig_6 3000;
BA_REL_ "GenSigTimeoutTime" BU_SG_REL_ VMCU SG_ 952 DRLLamp_stat_ISig_6 300;
BA_REL_ "GenSigFirstTimeoutTime" BU_SG_REL_ VMCU SG_ 1367 FasUsrDefStiffnessCurveSetting_I 24000;
BA_REL_ "GenSigTimeoutTime" BU_SG_REL_ VMCU SG_ 1367 FasUsrDefStiffnessCurveSetting_I 6000;
BA_REL_ "GenSigFirstTimeoutTime" BU_SG_REL_ VMCU SG_ 1367 FasDriver_ISig_6 24000;
BA_REL_ "GenSigTimeoutTime" BU_SG_REL_ VMCU SG_ 1367 FasDriver_ISig_6 6000;
BA_REL_ "GenSigFirstTimeoutTime" BU_SG_REL_ VMCU SG_ 1367 FasUsrDefLowSpeedReturnSetting_I 24000;
BA_REL_ "GenSigTimeoutTime" BU_SG_REL_ VMCU SG_ 1367 FasUsrDefLowSpeedReturnSetting_I 6000;
BA_REL_ "GenSigFirstTimeoutTime" BU_SG_REL_ VMCU SG_ 1367 ActualFasPersSettingsButton_ISig 24000;
BA_REL_ "GenSigTimeoutTime" BU_SG_REL_ VMCU SG_ 1367 ActualFasPersSettingsButton_ISig 6000;
BA_REL_ "GenSigFirstTimeoutTime" BU_SG_REL_ VMCU SG_ 1367 FasUsrDefStiffStraightSetting_IS 24000;
BA_REL_ "GenSigTimeoutTime" BU_SG_REL_ VMCU SG_ 1367 FasUsrDefStiffStraightSetting_IS 6000;
BA_REL_ "GenSigFirstTimeoutTime" BU_SG_REL_ VMCU SG_ 1367 FasUsrDefinedDampingSetting_ISig 24000;
BA_REL_ "GenSigTimeoutTime" BU_SG_REL_ VMCU SG_ 1367 FasUsrDefinedDampingSetting_ISig 6000;
BA_REL_ "GenSigFirstTimeoutTime" BU_SG_REL_ VMCU SG_ 1367 ActualFasManualOffsetSetting_ISi 24000;
BA_REL_ "GenSigTimeoutTime" BU_SG_REL_ VMCU SG_ 1367 ActualFasManualOffsetSetting_ISi 6000;
BA_REL_ "GenSigFirstTimeoutTime" BU_SG_REL_ VMCU SG_ 520 FrontRoadWheelAngleEstimate_ISig 3000;
BA_REL_ "GenSigTimeoutTime" BU_SG_REL_ VMCU SG_ 520 FrontRoadWheelAngleEstimate_ISig 120;
BA_REL_ "GenSigFirstTimeoutTime" BU_SG_REL_ VMCU SG_ 520 OverSteerGuidanceStatus_ISig_6 3000;
BA_REL_ "GenSigTimeoutTime" BU_SG_REL_ VMCU SG_ 520 OverSteerGuidanceStatus_ISig_6 120;
BA_REL_ "GenSigFirstTimeoutTime" BU_SG_REL_ VMCU SG_ 520 DriverSteeringTorqueEstimate_ISi 3000;
BA_REL_ "GenSigTimeoutTime" BU_SG_REL_ VMCU SG_ 520 DriverSteeringTorqueEstimate_ISi 120;
BA_REL_ "GenSigFirstTimeoutTime" BU_SG_REL_ VMCU SG_ 520 FASFullyOperational_ISig_6 3000;
BA_REL_ "GenSigTimeoutTime" BU_SG_REL_ VMCU SG_ 520 FASFullyOperational_ISig_6 120;
BA_REL_ "GenSigFirstTimeoutTime" BU_SG_REL_ VMCU SG_ 520 FASSaturated_ISig_6 3000;
BA_REL_ "GenSigTimeoutTime" BU_SG_REL_ VMCU SG_ 520 FASSaturated_ISig_6 120;
BA_REL_ "GenSigFirstTimeoutTime" BU_SG_REL_ VMCU SG_ 520 FASFunctionInControl_ISig_6 3000;
BA_REL_ "GenSigTimeoutTime" BU_SG_REL_ VMCU SG_ 520 FASFunctionInControl_ISig_6 120;
BA_REL_ "GenSigFirstTimeoutTime" BU_SG_REL_ VMCU SG_ 520 DriverSteeringTqEstimateConf_ISi 3000;
BA_REL_ "GenSigTimeoutTime" BU_SG_REL_ VMCU SG_ 520 DriverSteeringTqEstimateConf_ISi 120;
BA_REL_ "GenSigFirstTimeoutTime" BU_SG_REL_ APM SG_ 1232 XPRRequest_EBS 3000;
BA_REL_ "GenSigTimeoutTime" BU_SG_REL_ APM SG_ 1232 XPRRequest_EBS 600;
BA_REL_ "GenSigFirstTimeoutTime" BU_SG_REL_ APM SG_ 1232 ABSAxle5Active 3000;
BA_REL_ "GenSigTimeoutTime" BU_SG_REL_ APM SG_ 1232 ABSAxle5Active 600;
BA_REL_ "GenSigFirstTimeoutTime" BU_SG_REL_ APM SG_ 1232 ABSAxle4Active 3000;
BA_REL_ "GenSigTimeoutTime" BU_SG_REL_ APM SG_ 1232 ABSAxle4Active 600;
BA_REL_ "GenSigFirstTimeoutTime" BU_SG_REL_ VMCU SG_ 1232 RoadInclination2 3000;
BA_REL_ "GenSigTimeoutTime" BU_SG_REL_ VMCU SG_ 1232 RoadInclination2 600;
BA_REL_ "GenSigFirstTimeoutTime" BU_SG_REL_ APM SG_ 1232 ABSAxle2Active 3000;
BA_REL_ "GenSigTimeoutTime" BU_SG_REL_ APM SG_ 1232 ABSAxle2Active 600;
BA_REL_ "GenSigFirstTimeoutTime" BU_SG_REL_ APM SG_ 1232 ABSAxle3Active 3000;
BA_REL_ "GenSigTimeoutTime" BU_SG_REL_ APM SG_ 1232 ABSAxle3Active 600;
BA_REL_ "GenSigFirstTimeoutTime" BU_SG_REL_ APM SG_ 1232 ABSAxle1Active 3000;
BA_REL_ "GenSigTimeoutTime" BU_SG_REL_ APM SG_ 1232 ABSAxle1Active 600;
BA_REL_ "GenSigFirstTimeoutTime" BU_SG_REL_ APM SG_ 1232 HillHolderMode_ISig_6 3000;
BA_REL_ "GenSigTimeoutTime" BU_SG_REL_ APM SG_ 1232 HillHolderMode_ISig_6 600;
BA_REL_ "GenSigFirstTimeoutTime" BU_SG_REL_ VMCU SG_ 1507 ScndFrAxleLtRemainBrakeLining 24000;
BA_REL_ "GenSigTimeoutTime" BU_SG_REL_ VMCU SG_ 1507 ScndFrAxleLtRemainBrakeLining 6000;
BA_REL_ "GenSigFirstTimeoutTime" BU_SG_REL_ VMCU SG_ 1507 ScndFrAxleRtRemainBrakeLining 24000;
BA_REL_ "GenSigTimeoutTime" BU_SG_REL_ VMCU SG_ 1507 ScndFrAxleRtRemainBrakeLining 6000;
BA_REL_ "GenSigFirstTimeoutTime" BU_SG_REL_ VMCU SG_ 1504 RrAxle1RtRemainBrakeLining 24000;
BA_REL_ "GenSigTimeoutTime" BU_SG_REL_ VMCU SG_ 1504 RrAxle1RtRemainBrakeLining 6000;
BA_REL_ "GenSigFirstTimeoutTime" BU_SG_REL_ VMCU SG_ 1504 RrAxle2RtRemainBrakeLining 24000;
BA_REL_ "GenSigTimeoutTime" BU_SG_REL_ VMCU SG_ 1504 RrAxle2RtRemainBrakeLining 6000;
BA_REL_ "GenSigFirstTimeoutTime" BU_SG_REL_ VMCU SG_ 1504 RrAxle1LtRemainBrakeLining 24000;
BA_REL_ "GenSigTimeoutTime" BU_SG_REL_ VMCU SG_ 1504 RrAxle1LtRemainBrakeLining 6000;
BA_REL_ "GenSigFirstTimeoutTime" BU_SG_REL_ VMCU SG_ 1504 FrAxleLtRemainBrakeLining 24000;
BA_REL_ "GenSigTimeoutTime" BU_SG_REL_ VMCU SG_ 1504 FrAxleLtRemainBrakeLining 6000;
BA_REL_ "GenSigFirstTimeoutTime" BU_SG_REL_ VMCU SG_ 1504 RrAxle3RtRemainBrakeLining 24000;
BA_REL_ "GenSigTimeoutTime" BU_SG_REL_ VMCU SG_ 1504 RrAxle3RtRemainBrakeLining 6000;
BA_REL_ "GenSigFirstTimeoutTime" BU_SG_REL_ VMCU SG_ 1504 RrAxle2LtRemainBrakeLining 24000;
BA_REL_ "GenSigTimeoutTime" BU_SG_REL_ VMCU SG_ 1504 RrAxle2LtRemainBrakeLining 6000;
BA_REL_ "GenSigFirstTimeoutTime" BU_SG_REL_ VMCU SG_ 1504 FrAxleRtRemainBrakeLining 24000;
BA_REL_ "GenSigTimeoutTime" BU_SG_REL_ VMCU SG_ 1504 FrAxleRtRemainBrakeLining 6000;
BA_REL_ "GenSigFirstTimeoutTime" BU_SG_REL_ VMCU SG_ 1504 RrAxle3LtRemainBrakeLining 24000;
BA_REL_ "GenSigTimeoutTime" BU_SG_REL_ VMCU SG_ 1504 RrAxle3LtRemainBrakeLining 6000;
BA_REL_ "GenSigFirstTimeoutTime" BU_SG_REL_ TPM SG_ 1501 Trailer2TireInfoISO_Leakage_ISig 24000;
BA_REL_ "GenSigTimeoutTime" BU_SG_REL_ TPM SG_ 1501 Trailer2TireInfoISO_Leakage_ISig 6000;
BA_REL_ "GenSigFirstTimeoutTime" BU_SG_REL_ TPM SG_ 1501 Trailer2TireInfoISO_TireId_ISig_ 24000;
BA_REL_ "GenSigTimeoutTime" BU_SG_REL_ TPM SG_ 1501 Trailer2TireInfoISO_TireId_ISig_ 6000;
BA_REL_ "GenSigFirstTimeoutTime" BU_SG_REL_ TPM SG_ 1501 Trailer2TireInfoISO_Warning_ISig 24000;
BA_REL_ "GenSigTimeoutTime" BU_SG_REL_ TPM SG_ 1501 Trailer2TireInfoISO_Warning_ISig 6000;
BA_REL_ "GenSigFirstTimeoutTime" BU_SG_REL_ TPM SG_ 1501 Trailer2TireInfoISO_Pressure_ISi 24000;
BA_REL_ "GenSigTimeoutTime" BU_SG_REL_ TPM SG_ 1501 Trailer2TireInfoISO_Pressure_ISi 6000;
BA_REL_ "GenSigFirstTimeoutTime" BU_SG_REL_ TPM SG_ 1501 Trailer2TireInfoISO_PresSuff_ISi 24000;
BA_REL_ "GenSigTimeoutTime" BU_SG_REL_ TPM SG_ 1501 Trailer2TireInfoISO_PresSuff_ISi 6000;
BA_REL_ "GenSigFirstTimeoutTime" BU_SG_REL_ TPM SG_ 1501 Trailer2TireInfoISO_PowerSupply_ 24000;
BA_REL_ "GenSigTimeoutTime" BU_SG_REL_ TPM SG_ 1501 Trailer2TireInfoISO_PowerSupply_ 6000;
BA_REL_ "GenSigFirstTimeoutTime" BU_SG_REL_ TPM SG_ 1501 Trailer2TireInfoISO_Active_ISig_ 24000;
BA_REL_ "GenSigTimeoutTime" BU_SG_REL_ TPM SG_ 1501 Trailer2TireInfoISO_Active_ISig_ 6000;
BA_REL_ "GenSigFirstTimeoutTime" BU_SG_REL_ TPM SG_ 1501 Trailer2TireInfoISO_Temperature_ 24000;
BA_REL_ "GenSigTimeoutTime" BU_SG_REL_ TPM SG_ 1501 Trailer2TireInfoISO_Temperature_ 6000;
BA_REL_ "GenSigFirstTimeoutTime" BU_SG_REL_ TPM SG_ 1498 Trailer1TireInfoISO_Leakage_ISig 24000;
BA_REL_ "GenSigTimeoutTime" BU_SG_REL_ TPM SG_ 1498 Trailer1TireInfoISO_Leakage_ISig 6000;
BA_REL_ "GenSigFirstTimeoutTime" BU_SG_REL_ TPM SG_ 1498 Trailer1TireInfoISO_Pressure_ISi 24000;
BA_REL_ "GenSigTimeoutTime" BU_SG_REL_ TPM SG_ 1498 Trailer1TireInfoISO_Pressure_ISi 6000;
BA_REL_ "GenSigFirstTimeoutTime" BU_SG_REL_ TPM SG_ 1498 Trailer1TireInfoISO_Active_ISig_ 24000;
BA_REL_ "GenSigTimeoutTime" BU_SG_REL_ TPM SG_ 1498 Trailer1TireInfoISO_Active_ISig_ 6000;
BA_REL_ "GenSigFirstTimeoutTime" BU_SG_REL_ TPM SG_ 1498 Trailer1TireInfoISO_PresSuff_ISi 24000;
BA_REL_ "GenSigTimeoutTime" BU_SG_REL_ TPM SG_ 1498 Trailer1TireInfoISO_PresSuff_ISi 6000;
BA_REL_ "GenSigFirstTimeoutTime" BU_SG_REL_ TPM SG_ 1498 Trailer1TireInfoISO_Temperature_ 24000;
BA_REL_ "GenSigTimeoutTime" BU_SG_REL_ TPM SG_ 1498 Trailer1TireInfoISO_Temperature_ 6000;
BA_REL_ "GenSigFirstTimeoutTime" BU_SG_REL_ TPM SG_ 1498 Trailer1TireInfoISO_PowerSupply_ 24000;
BA_REL_ "GenSigTimeoutTime" BU_SG_REL_ TPM SG_ 1498 Trailer1TireInfoISO_PowerSupply_ 6000;
BA_REL_ "GenSigFirstTimeoutTime" BU_SG_REL_ TPM SG_ 1498 Trailer1TireInfoISO_TireId_ISig_ 24000;
BA_REL_ "GenSigTimeoutTime" BU_SG_REL_ TPM SG_ 1498 Trailer1TireInfoISO_TireId_ISig_ 6000;
BA_REL_ "GenSigFirstTimeoutTime" BU_SG_REL_ TPM SG_ 1498 Trailer1TireInfoISO_Warning_ISig 24000;
BA_REL_ "GenSigTimeoutTime" BU_SG_REL_ TPM SG_ 1498 Trailer1TireInfoISO_Warning_ISig 6000;
BA_REL_ "GenSigFirstTimeoutTime" BU_SG_REL_ EAS SG_ 396 SteeringWheel_AngleValue 3000;
BA_REL_ "GenSigTimeoutTime" BU_SG_REL_ EAS SG_ 396 SteeringWheel_AngleValue 60;
BA_REL_ "GenSigFirstTimeoutTime" BU_SG_REL_ EAS SG_ 396 SteeringWheel_AngleCounter 3000;
BA_REL_ "GenSigTimeoutTime" BU_SG_REL_ EAS SG_ 396 SteeringWheel_AngleCounter 60;
BA_REL_ "GenSigFirstTimeoutTime" BU_SG_REL_ EAS SG_ 396 SteeringWheel_AngleCRC 3000;
BA_REL_ "GenSigTimeoutTime" BU_SG_REL_ EAS SG_ 396 SteeringWheel_AngleCRC 60;
BA_REL_ "GenSigFirstTimeoutTime" BU_SG_REL_ FAS SG_ 395 ActualTagWheelAngle 3000;
BA_REL_ "GenSigTimeoutTime" BU_SG_REL_ FAS SG_ 395 ActualTagWheelAngle 60;
BA_REL_ "GenSigFirstTimeoutTime" BU_SG_REL_ FAS SG_ 395 ActualPusherWheelAngle 3000;
BA_REL_ "GenSigTimeoutTime" BU_SG_REL_ FAS SG_ 395 ActualPusherWheelAngle 60;
BA_REL_ "GenSigFirstTimeoutTime" BU_SG_REL_ RCIOM SG_ 395 SteeringWheelAngle_ISig_6 3000;
BA_REL_ "GenSigTimeoutTime" BU_SG_REL_ RCIOM SG_ 395 SteeringWheelAngle_ISig_6 500;
BA_REL_ "GenSigFirstTimeoutTime" BU_SG_REL_ FAS SG_ 395 SteeringWheelAngle_ISig_6 3000;
BA_REL_ "GenSigTimeoutTime" BU_SG_REL_ FAS SG_ 395 SteeringWheelAngle_ISig_6 500;
BA_REL_ "GenSigFirstTimeoutTime" BU_SG_REL_ CCIOM SG_ 394 ScndRrDriveAxleRightWheelSpeed 3000;
BA_REL_ "GenSigTimeoutTime" BU_SG_REL_ CCIOM SG_ 394 ScndRrDriveAxleRightWheelSpeed 60;
BA_REL_ "GenSigFirstTimeoutTime" BU_SG_REL_ VMCU SG_ 394 ScndRrDriveAxleRightWheelSpeed 3000;
BA_REL_ "GenSigTimeoutTime" BU_SG_REL_ VMCU SG_ 394 ScndRrDriveAxleRightWheelSpeed 60;
BA_REL_ "GenSigFirstTimeoutTime" BU_SG_REL_ RCIOM SG_ 394 ScndRrDriveAxleRightWheelSpeed 3000;
BA_REL_ "GenSigTimeoutTime" BU_SG_REL_ RCIOM SG_ 394 ScndRrDriveAxleRightWheelSpeed 60;
BA_REL_ "GenSigFirstTimeoutTime" BU_SG_REL_ FAS SG_ 394 ScndFrAxleLeftWheelSpeed 3000;
BA_REL_ "GenSigTimeoutTime" BU_SG_REL_ FAS SG_ 394 ScndFrAxleLeftWheelSpeed 60;
BA_REL_ "GenSigFirstTimeoutTime" BU_SG_REL_ VMCU SG_ 394 ScndFrAxleLeftWheelSpeed 3000;
BA_REL_ "GenSigTimeoutTime" BU_SG_REL_ VMCU SG_ 394 ScndFrAxleLeftWheelSpeed 60;
BA_REL_ "GenSigFirstTimeoutTime" BU_SG_REL_ VMCU SG_ 394 ScndFrAxleRightWheelSpeed 3000;
BA_REL_ "GenSigTimeoutTime" BU_SG_REL_ VMCU SG_ 394 ScndFrAxleRightWheelSpeed 60;
BA_REL_ "GenSigFirstTimeoutTime" BU_SG_REL_ FAS SG_ 394 ScndFrAxleRightWheelSpeed 3000;
BA_REL_ "GenSigTimeoutTime" BU_SG_REL_ FAS SG_ 394 ScndFrAxleRightWheelSpeed 60;
BA_REL_ "GenSigFirstTimeoutTime" BU_SG_REL_ CCIOM SG_ 394 ScndRrDriveAxleLeftWheelSpeed 3000;
BA_REL_ "GenSigTimeoutTime" BU_SG_REL_ CCIOM SG_ 394 ScndRrDriveAxleLeftWheelSpeed 60;
BA_REL_ "GenSigFirstTimeoutTime" BU_SG_REL_ VMCU SG_ 394 ScndRrDriveAxleLeftWheelSpeed 3000;
BA_REL_ "GenSigTimeoutTime" BU_SG_REL_ VMCU SG_ 394 ScndRrDriveAxleLeftWheelSpeed 60;
BA_REL_ "GenSigFirstTimeoutTime" BU_SG_REL_ RCIOM SG_ 394 ScndRrDriveAxleLeftWheelSpeed 3000;
BA_REL_ "GenSigTimeoutTime" BU_SG_REL_ RCIOM SG_ 394 ScndRrDriveAxleLeftWheelSpeed 60;
BA_REL_ "GenSigFirstTimeoutTime" BU_SG_REL_ EAS SG_ 391 PusherAxleRightWheelSpeed 3000;
BA_REL_ "GenSigTimeoutTime" BU_SG_REL_ EAS SG_ 391 PusherAxleRightWheelSpeed 60;
BA_REL_ "GenSigFirstTimeoutTime" BU_SG_REL_ VMCU SG_ 391 PusherAxleRightWheelSpeed 3000;
BA_REL_ "GenSigTimeoutTime" BU_SG_REL_ VMCU SG_ 391 PusherAxleRightWheelSpeed 60;
BA_REL_ "GenSigFirstTimeoutTime" BU_SG_REL_ EAS SG_ 391 TagAxleRightWheelSpeed 3000;
BA_REL_ "GenSigTimeoutTime" BU_SG_REL_ EAS SG_ 391 TagAxleRightWheelSpeed 60;
BA_REL_ "GenSigFirstTimeoutTime" BU_SG_REL_ VMCU SG_ 391 TagAxleRightWheelSpeed 3000;
BA_REL_ "GenSigTimeoutTime" BU_SG_REL_ VMCU SG_ 391 TagAxleRightWheelSpeed 60;
BA_REL_ "GenSigFirstTimeoutTime" BU_SG_REL_ EAS SG_ 391 TagAxleLeftWheelSpeed 3000;
BA_REL_ "GenSigTimeoutTime" BU_SG_REL_ EAS SG_ 391 TagAxleLeftWheelSpeed 60;
BA_REL_ "GenSigFirstTimeoutTime" BU_SG_REL_ VMCU SG_ 391 TagAxleLeftWheelSpeed 3000;
BA_REL_ "GenSigTimeoutTime" BU_SG_REL_ VMCU SG_ 391 TagAxleLeftWheelSpeed 60;
BA_REL_ "GenSigFirstTimeoutTime" BU_SG_REL_ EAS SG_ 391 PusherAxleLeftWheelSpeed 3000;
BA_REL_ "GenSigTimeoutTime" BU_SG_REL_ EAS SG_ 391 PusherAxleLeftWheelSpeed 60;
BA_REL_ "GenSigFirstTimeoutTime" BU_SG_REL_ VMCU SG_ 391 PusherAxleLeftWheelSpeed 3000;
BA_REL_ "GenSigTimeoutTime" BU_SG_REL_ VMCU SG_ 391 PusherAxleLeftWheelSpeed 60;
BA_REL_ "GenSigFirstTimeoutTime" BU_SG_REL_ VMCU SG_ 386 LongitudinalAcceleration_ISig_6 3000;
BA_REL_ "GenSigTimeoutTime" BU_SG_REL_ VMCU SG_ 386 LongitudinalAcceleration_ISig_6 60;
BA_REL_ "GenSigFirstTimeoutTime" BU_SG_REL_ RCIOM SG_ 386 LongitudinalAcceleration_ISig_6 3000;
BA_REL_ "GenSigTimeoutTime" BU_SG_REL_ RCIOM SG_ 386 LongitudinalAcceleration_ISig_6 60;
BA_REL_ "GenSigFirstTimeoutTime" BU_SG_REL_ APM SG_ 386 EBSBrakeSwitch 3000;
BA_REL_ "GenSigTimeoutTime" BU_SG_REL_ APM SG_ 386 EBSBrakeSwitch 60;
BA_REL_ "GenSigFirstTimeoutTime" BU_SG_REL_ VMCU SG_ 386 EBSBrakeSwitch 3000;
BA_REL_ "GenSigTimeoutTime" BU_SG_REL_ VMCU SG_ 386 EBSBrakeSwitch 60;
BA_REL_ "GenSigFirstTimeoutTime" BU_SG_REL_ RCIOM SG_ 386 BrakeLightActivationRequest 3000;
BA_REL_ "GenSigTimeoutTime" BU_SG_REL_ RCIOM SG_ 386 BrakeLightActivationRequest 60;
BA_REL_ "GenSigFirstTimeoutTime" BU_SG_REL_ FAS SG_ 386 YawRate_ISig_6 3000;
BA_REL_ "GenSigTimeoutTime" BU_SG_REL_ FAS SG_ 386 YawRate_ISig_6 60;
BA_REL_ "GenSigFirstTimeoutTime" BU_SG_REL_ RCIOM SG_ 386 VDCBrakeLightRequest 3000;
BA_REL_ "GenSigTimeoutTime" BU_SG_REL_ RCIOM SG_ 386 VDCBrakeLightRequest 60;
BA_REL_ "GenSigFirstTimeoutTime" BU_SG_REL_ VMCU SG_ 386 LateralAcceleration_ISig_6 3000;
BA_REL_ "GenSigTimeoutTime" BU_SG_REL_ VMCU SG_ 386 LateralAcceleration_ISig_6 60;
BA_REL_ "GenSigFirstTimeoutTime" BU_SG_REL_ RCIOM SG_ 386 LateralAcceleration_ISig_6 3000;
BA_REL_ "GenSigTimeoutTime" BU_SG_REL_ RCIOM SG_ 386 LateralAcceleration_ISig_6 60;
BA_REL_ "GenSigFirstTimeoutTime" BU_SG_REL_ FAS SG_ 386 LateralAcceleration_ISig_6 3000;
BA_REL_ "GenSigTimeoutTime" BU_SG_REL_ FAS SG_ 386 LateralAcceleration_ISig_6 60;
BA_REL_ "GenSigFirstTimeoutTime" BU_SG_REL_ VMCU SG_ 386 EBSBrakePedalPosition 3000;
BA_REL_ "GenSigTimeoutTime" BU_SG_REL_ VMCU SG_ 386 EBSBrakePedalPosition 60;
BA_REL_ "GenSigFirstTimeoutTime" BU_SG_REL_ APM SG_ 386 EBSBrakePedalPosition 3000;
BA_REL_ "GenSigTimeoutTime" BU_SG_REL_ APM SG_ 386 EBSBrakePedalPosition 60;
BA_REL_ "GenSigFirstTimeoutTime" BU_SG_REL_ RCIOM SG_ 824 TrailerEBSAmberWarning 3000;
BA_REL_ "GenSigTimeoutTime" BU_SG_REL_ RCIOM SG_ 824 TrailerEBSAmberWarning 180;
BA_REL_ "GenSigFirstTimeoutTime" BU_SG_REL_ APM SG_ 824 HSAState_ISig_6 3000;
BA_REL_ "GenSigTimeoutTime" BU_SG_REL_ APM SG_ 824 HSAState_ISig_6 180;
BA_REL_ "GenSigFirstTimeoutTime" BU_SG_REL_ RCIOM SG_ 824 PusherLiftAxleLoweringInhibit 3000;
BA_REL_ "GenSigTimeoutTime" BU_SG_REL_ RCIOM SG_ 824 PusherLiftAxleLoweringInhibit 180;
BA_REL_ "GenSigFirstTimeoutTime" BU_SG_REL_ RCIOM SG_ 824 TrailersConnected_ISig_6 3000;
BA_REL_ "GenSigTimeoutTime" BU_SG_REL_ RCIOM SG_ 824 TrailersConnected_ISig_6 180;
BA_REL_ "GenSigFirstTimeoutTime" BU_SG_REL_ FAS SG_ 824 YCBrakeControlActive_ISig_6 3000;
BA_REL_ "GenSigTimeoutTime" BU_SG_REL_ FAS SG_ 824 YCBrakeControlActive_ISig_6 180;
BA_REL_ "GenSigFirstTimeoutTime" BU_SG_REL_ APM SG_ 824 YCBrakeControlActive_ISig_6 3000;
BA_REL_ "GenSigTimeoutTime" BU_SG_REL_ APM SG_ 824 YCBrakeControlActive_ISig_6 180;
BA_REL_ "GenSigFirstTimeoutTime" BU_SG_REL_ EAS SG_ 824 YCBrakeControlActive_ISig_6 3000;
BA_REL_ "GenSigTimeoutTime" BU_SG_REL_ EAS SG_ 824 YCBrakeControlActive_ISig_6 180;
BA_REL_ "GenSigFirstTimeoutTime" BU_SG_REL_ FAS SG_ 824 YCEngineControlActive_ISig_6 3000;
BA_REL_ "GenSigTimeoutTime" BU_SG_REL_ FAS SG_ 824 YCEngineControlActive_ISig_6 180;
BA_REL_ "GenSigFirstTimeoutTime" BU_SG_REL_ RCIOM SG_ 824 StretchBrake_Stat_ISig_6 3000;
BA_REL_ "GenSigTimeoutTime" BU_SG_REL_ RCIOM SG_ 824 StretchBrake_Stat_ISig_6 180;
BA_REL_ "GenSigFirstTimeoutTime" BU_SG_REL_ RCIOM SG_ 824 Trailer1LiftAxle1Pos_ISig_6 3000;
BA_REL_ "GenSigTimeoutTime" BU_SG_REL_ RCIOM SG_ 824 Trailer1LiftAxle1Pos_ISig_6 180;
BA_REL_ "GenSigFirstTimeoutTime" BU_SG_REL_ RCIOM SG_ 824 Trailer1LiftAxle2Pos_ISig_6 3000;
BA_REL_ "GenSigTimeoutTime" BU_SG_REL_ RCIOM SG_ 824 Trailer1LiftAxle2Pos_ISig_6 180;
BA_REL_ "GenSigFirstTimeoutTime" BU_SG_REL_ FAS SG_ 824 SteeringWheelAngleComp 3000;
BA_REL_ "GenSigTimeoutTime" BU_SG_REL_ FAS SG_ 824 SteeringWheelAngleComp 180;
BA_REL_ "GenSigFirstTimeoutTime" BU_SG_REL_ RCIOM SG_ 824 FrontParkBrakeOverrideStatus 3000;
BA_REL_ "GenSigTimeoutTime" BU_SG_REL_ RCIOM SG_ 824 FrontParkBrakeOverrideStatus 180;
BA_REL_ "GenSigFirstTimeoutTime" BU_SG_REL_ CCIOM SG_ 824 BrakingSystemPressureLim_rqst 3000;
BA_REL_ "GenSigTimeoutTime" BU_SG_REL_ CCIOM SG_ 824 BrakingSystemPressureLim_rqst 180;
BA_REL_ "GenSigFirstTimeoutTime" BU_SG_REL_ APM SG_ 824 BrakingSystemPressureLim_rqst 3000;
BA_REL_ "GenSigTimeoutTime" BU_SG_REL_ APM SG_ 824 BrakingSystemPressureLim_rqst 180;
BA_REL_ "GenSigFirstTimeoutTime" BU_SG_REL_ FAS SG_ 824 ROPEngineControlActive_ISig_6 3000;
BA_REL_ "GenSigTimeoutTime" BU_SG_REL_ FAS SG_ 824 ROPEngineControlActive_ISig_6 180;
BA_REL_ "GenSigFirstTimeoutTime" BU_SG_REL_ APM SG_ 824 TrailerControlPressure 3000;
BA_REL_ "GenSigTimeoutTime" BU_SG_REL_ APM SG_ 824 TrailerControlPressure 180;
BA_REL_ "GenSigFirstTimeoutTime" BU_SG_REL_ VMCU SG_ 824 TrailerControlPressure 3000;
BA_REL_ "GenSigTimeoutTime" BU_SG_REL_ VMCU SG_ 824 TrailerControlPressure 180;
BA_REL_ "GenSigFirstTimeoutTime" BU_SG_REL_ RCIOM SG_ 824 Trailer1TractionHelp_ISig_6 3000;
BA_REL_ "GenSigTimeoutTime" BU_SG_REL_ RCIOM SG_ 824 Trailer1TractionHelp_ISig_6 180;
BA_REL_ "GenSigFirstTimeoutTime" BU_SG_REL_ RCIOM SG_ 824 TagLiftAxleLoweringInhibit 3000;
BA_REL_ "GenSigTimeoutTime" BU_SG_REL_ RCIOM SG_ 824 TagLiftAxleLoweringInhibit 180;
BA_REL_ "GenSigFirstTimeoutTime" BU_SG_REL_ FAS SG_ 824 ROPBrakeControlActive_ISig_6 3000;
BA_REL_ "GenSigTimeoutTime" BU_SG_REL_ FAS SG_ 824 ROPBrakeControlActive_ISig_6 180;
BA_REL_ "GenSigFirstTimeoutTime" BU_SG_REL_ APM SG_ 824 ROPBrakeControlActive_ISig_6 3000;
BA_REL_ "GenSigTimeoutTime" BU_SG_REL_ APM SG_ 824 ROPBrakeControlActive_ISig_6 180;
BA_REL_ "GenSigFirstTimeoutTime" BU_SG_REL_ VMCU SG_ 824 SplitBoxDiffLockActvnFuncReq 3000;
BA_REL_ "GenSigTimeoutTime" BU_SG_REL_ VMCU SG_ 824 SplitBoxDiffLockActvnFuncReq 180;
BA_REL_ "GenSigFirstTimeoutTime" BU_SG_REL_ CCIOM SG_ 824 SplitBoxDiffLockActvnFuncReq 3000;
BA_REL_ "GenSigTimeoutTime" BU_SG_REL_ CCIOM SG_ 824 SplitBoxDiffLockActvnFuncReq 180;
BA_REL_ "GenSigFirstTimeoutTime" BU_SG_REL_ VMCU SG_ 824 TrailerBrake_Stat 3000;
BA_REL_ "GenSigTimeoutTime" BU_SG_REL_ VMCU SG_ 824 TrailerBrake_Stat 180;
BA_REL_ "GenSigFirstTimeoutTime" BU_SG_REL_ RCIOM SG_ 824 TrailerBrake_Stat 3000;
BA_REL_ "GenSigTimeoutTime" BU_SG_REL_ RCIOM SG_ 824 TrailerBrake_Stat 180;
BA_REL_ "GenSigFirstTimeoutTime" BU_SG_REL_ FAS SG_ 529 RrAxle3LtWhlBrakeApplPrsHiRng 3000;
BA_REL_ "GenSigTimeoutTime" BU_SG_REL_ FAS SG_ 529 RrAxle3LtWhlBrakeApplPrsHiRng 600;
BA_REL_ "GenSigFirstTimeoutTime" BU_SG_REL_ APM SG_ 529 RrAxle3LtWhlBrakeApplPrsHiRng 3000;
BA_REL_ "GenSigTimeoutTime" BU_SG_REL_ APM SG_ 529 RrAxle3LtWhlBrakeApplPrsHiRng 600;
BA_REL_ "GenSigFirstTimeoutTime" BU_SG_REL_ VMCU SG_ 529 RrAxle3LtWhlBrakeApplPrsHiRng 3000;
BA_REL_ "GenSigTimeoutTime" BU_SG_REL_ VMCU SG_ 529 RrAxle3LtWhlBrakeApplPrsHiRng 120;
BA_REL_ "GenSigFirstTimeoutTime" BU_SG_REL_ FAS SG_ 529 RrAxle1LtWhlBrakeApplPrsHiRng 3000;
BA_REL_ "GenSigTimeoutTime" BU_SG_REL_ FAS SG_ 529 RrAxle1LtWhlBrakeApplPrsHiRng 600;
BA_REL_ "GenSigFirstTimeoutTime" BU_SG_REL_ APM SG_ 529 RrAxle1LtWhlBrakeApplPrsHiRng 3000;
BA_REL_ "GenSigTimeoutTime" BU_SG_REL_ APM SG_ 529 RrAxle1LtWhlBrakeApplPrsHiRng 600;
BA_REL_ "GenSigFirstTimeoutTime" BU_SG_REL_ VMCU SG_ 529 RrAxle1LtWhlBrakeApplPrsHiRng 3000;
BA_REL_ "GenSigTimeoutTime" BU_SG_REL_ VMCU SG_ 529 RrAxle1LtWhlBrakeApplPrsHiRng 120;
BA_REL_ "GenSigFirstTimeoutTime" BU_SG_REL_ VMCU SG_ 529 FrAxleLtWhlBrakeApplPrsHiRng 3000;
BA_REL_ "GenSigTimeoutTime" BU_SG_REL_ VMCU SG_ 529 FrAxleLtWhlBrakeApplPrsHiRng 120;
BA_REL_ "GenSigFirstTimeoutTime" BU_SG_REL_ FAS SG_ 529 FrAxleLtWhlBrakeApplPrsHiRng 3000;
BA_REL_ "GenSigTimeoutTime" BU_SG_REL_ FAS SG_ 529 FrAxleLtWhlBrakeApplPrsHiRng 600;
BA_REL_ "GenSigFirstTimeoutTime" BU_SG_REL_ APM SG_ 529 FrAxleLtWhlBrakeApplPrsHiRng 3000;
BA_REL_ "GenSigTimeoutTime" BU_SG_REL_ APM SG_ 529 FrAxleLtWhlBrakeApplPrsHiRng 600;
BA_REL_ "GenSigFirstTimeoutTime" BU_SG_REL_ VMCU SG_ 529 RrAxle1RtWhlBrakeApplPrsHiRng 3000;
BA_REL_ "GenSigTimeoutTime" BU_SG_REL_ VMCU SG_ 529 RrAxle1RtWhlBrakeApplPrsHiRng 120;
BA_REL_ "GenSigFirstTimeoutTime" BU_SG_REL_ FAS SG_ 529 RrAxle1RtWhlBrakeApplPrsHiRng 3000;
BA_REL_ "GenSigTimeoutTime" BU_SG_REL_ FAS SG_ 529 RrAxle1RtWhlBrakeApplPrsHiRng 600;
BA_REL_ "GenSigFirstTimeoutTime" BU_SG_REL_ APM SG_ 529 RrAxle1RtWhlBrakeApplPrsHiRng 3000;
BA_REL_ "GenSigTimeoutTime" BU_SG_REL_ APM SG_ 529 RrAxle1RtWhlBrakeApplPrsHiRng 600;
BA_REL_ "GenSigFirstTimeoutTime" BU_SG_REL_ FAS SG_ 529 RrAxle3RtWhlBrakeApplPrsHiRng 3000;
BA_REL_ "GenSigTimeoutTime" BU_SG_REL_ FAS SG_ 529 RrAxle3RtWhlBrakeApplPrsHiRng 600;
BA_REL_ "GenSigFirstTimeoutTime" BU_SG_REL_ APM SG_ 529 RrAxle3RtWhlBrakeApplPrsHiRng 3000;
BA_REL_ "GenSigTimeoutTime" BU_SG_REL_ APM SG_ 529 RrAxle3RtWhlBrakeApplPrsHiRng 600;
BA_REL_ "GenSigFirstTimeoutTime" BU_SG_REL_ VMCU SG_ 529 RrAxle3RtWhlBrakeApplPrsHiRng 3000;
BA_REL_ "GenSigTimeoutTime" BU_SG_REL_ VMCU SG_ 529 RrAxle3RtWhlBrakeApplPrsHiRng 120;
BA_REL_ "GenSigFirstTimeoutTime" BU_SG_REL_ APM SG_ 529 RrAxle2LtWhlBrakeApplPrsHiRng 3000;
BA_REL_ "GenSigTimeoutTime" BU_SG_REL_ APM SG_ 529 RrAxle2LtWhlBrakeApplPrsHiRng 600;
BA_REL_ "GenSigFirstTimeoutTime" BU_SG_REL_ FAS SG_ 529 RrAxle2LtWhlBrakeApplPrsHiRng 3000;
BA_REL_ "GenSigTimeoutTime" BU_SG_REL_ FAS SG_ 529 RrAxle2LtWhlBrakeApplPrsHiRng 600;
BA_REL_ "GenSigFirstTimeoutTime" BU_SG_REL_ VMCU SG_ 529 RrAxle2LtWhlBrakeApplPrsHiRng 3000;
BA_REL_ "GenSigTimeoutTime" BU_SG_REL_ VMCU SG_ 529 RrAxle2LtWhlBrakeApplPrsHiRng 120;
BA_REL_ "GenSigFirstTimeoutTime" BU_SG_REL_ FAS SG_ 529 FrAxleRtWhlBrakeApplPrsHiRng 3000;
BA_REL_ "GenSigTimeoutTime" BU_SG_REL_ FAS SG_ 529 FrAxleRtWhlBrakeApplPrsHiRng 600;
BA_REL_ "GenSigFirstTimeoutTime" BU_SG_REL_ VMCU SG_ 529 FrAxleRtWhlBrakeApplPrsHiRng 3000;
BA_REL_ "GenSigTimeoutTime" BU_SG_REL_ VMCU SG_ 529 FrAxleRtWhlBrakeApplPrsHiRng 120;
BA_REL_ "GenSigFirstTimeoutTime" BU_SG_REL_ APM SG_ 529 FrAxleRtWhlBrakeApplPrsHiRng 3000;
BA_REL_ "GenSigTimeoutTime" BU_SG_REL_ APM SG_ 529 FrAxleRtWhlBrakeApplPrsHiRng 600;
BA_REL_ "GenSigFirstTimeoutTime" BU_SG_REL_ APM SG_ 529 RrAxle2RtWhlBrakeApplPrsHiRng 3000;
BA_REL_ "GenSigTimeoutTime" BU_SG_REL_ APM SG_ 529 RrAxle2RtWhlBrakeApplPrsHiRng 600;
BA_REL_ "GenSigFirstTimeoutTime" BU_SG_REL_ VMCU SG_ 529 RrAxle2RtWhlBrakeApplPrsHiRng 3000;
BA_REL_ "GenSigTimeoutTime" BU_SG_REL_ VMCU SG_ 529 RrAxle2RtWhlBrakeApplPrsHiRng 120;
BA_REL_ "GenSigFirstTimeoutTime" BU_SG_REL_ FAS SG_ 529 RrAxle2RtWhlBrakeApplPrsHiRng 3000;
BA_REL_ "GenSigTimeoutTime" BU_SG_REL_ FAS SG_ 529 RrAxle2RtWhlBrakeApplPrsHiRng 600;
BA_REL_ "GenSigFirstTimeoutTime" BU_SG_REL_ FAS SG_ 516 EASActualTagWheelAngle 3000;
BA_REL_ "GenSigTimeoutTime" BU_SG_REL_ FAS SG_ 516 EASActualTagWheelAngle 120;
BA_REL_ "GenSigFirstTimeoutTime" BU_SG_REL_ RCIOM SG_ 516 EASPusherLiftAxleLoweringInhib 3000;
BA_REL_ "GenSigTimeoutTime" BU_SG_REL_ RCIOM SG_ 516 EASPusherLiftAxleLoweringInhib 120;
BA_REL_ "GenSigFirstTimeoutTime" BU_SG_REL_ VMCU SG_ 516 ExtraAxleSteeringFunctionStat_IS 3000;
BA_REL_ "GenSigTimeoutTime" BU_SG_REL_ VMCU SG_ 516 ExtraAxleSteeringFunctionStat_IS 120;
BA_REL_ "GenSigFirstTimeoutTime" BU_SG_REL_ RCIOM SG_ 516 EASTagLiftAxleLoweringInhibit 3000;
BA_REL_ "GenSigTimeoutTime" BU_SG_REL_ RCIOM SG_ 516 EASTagLiftAxleLoweringInhibit 120;
BA_REL_ "GenSigFirstTimeoutTime" BU_SG_REL_ FAS SG_ 516 EASActualPusherWheelAngle 3000;
BA_REL_ "GenSigTimeoutTime" BU_SG_REL_ FAS SG_ 516 EASActualPusherWheelAngle 120;
VAL_ 952 DirIndSideLamp1_stat 7 "LampCheckLeftRight_stat_NotAvailable" 6 "LampCheckLeftRight_stat_Error" 5 "LampCheckLeftRight_stat_Spare" 4 "LampCheckLeftRight_stat_TestedLeftAndRightLampNOK" 3 "LampCheckLeftRight_stat_TestedRightLampNOK" 2 "LampCheckLeftRight_stat_TestedLeftLampNOK" 1 "LampCheckLeftRight_stat_TestedLampOK" 0 "LampCheckLeftRight_stat_NotTested" ;
VAL_ 952 MainBeamLamp_stat_ISig_6 7 "LampCheckLeftRight_stat_NotAvailable" 6 "LampCheckLeftRight_stat_Error" 5 "LampCheckLeftRight_stat_Spare" 4 "LampCheckLeftRight_stat_TestedLeftAndRightLampNOK" 3 "LampCheckLeftRight_stat_TestedRightLampNOK" 2 "LampCheckLeftRight_stat_TestedLeftLampNOK" 1 "LampCheckLeftRight_stat_TestedLampOK" 0 "LampCheckLeftRight_stat_NotTested" ;
VAL_ 952 FogLamp_Front_Status 3 "InactiveActive_NotAvailable" 2 "InactiveActive_Error" 1 "InactiveActive_Active" 0 "InactiveActive_Inactive" ;
VAL_ 952 DirInd_Front_Status_ISig_6 7 "DirIndFaultStatus_NotAvailable" 6 "DirIndFaultStatus_Error" 5 "DirIndFaultStatus_SpareValue_01" 4 "DirIndFaultStatus_SpareValue" 3 "DirIndFaultStatus_BothLeftAndRightDirectionIndicatorsFault" 2 "DirIndFaultStatus_RightDirectionIndicatorLampFault" 1 "DirIndFaultStatus_LeftDirectionIndicatorLampFault" 0 "DirIndFaultStatus_NoError" ;
VAL_ 952 AuxLamp_Front_Status 3 "InactiveActive_NotAvailable" 2 "InactiveActive_Error" 1 "InactiveActive_Active" 0 "InactiveActive_Inactive" ;
VAL_ 952 WasherFluidLevel_ISig_6 7 "WasherFluidLevel_NotAvailable" 6 "WasherFluidLevel_ErrorIndicator" 5 "WasherFluidLevel_Spare_02" 4 "WasherFluidLevel_Spare_01" 3 "WasherFluidLevel_Spare" 2 "WasherFluidLevel_Level2" 1 "WasherFluidLevel_Level1" 0 "WasherFluidLevel_Level0" ;
VAL_ 952 StaticCornerLightLamp_stat_ISig_ 7 "LampCheckLeftRight_stat_NotAvailable" 6 "LampCheckLeftRight_stat_Error" 5 "LampCheckLeftRight_stat_Spare" 4 "LampCheckLeftRight_stat_TestedLeftAndRightLampNOK" 3 "LampCheckLeftRight_stat_TestedRightLampNOK" 2 "LampCheckLeftRight_stat_TestedLeftLampNOK" 1 "LampCheckLeftRight_stat_TestedLampOK" 0 "LampCheckLeftRight_stat_NotTested" ;
VAL_ 952 DippedBeamLamp_stat_ISig_6 7 "LampCheckLeftRight_stat_NotAvailable" 6 "LampCheckLeftRight_stat_Error" 5 "LampCheckLeftRight_stat_Spare" 4 "LampCheckLeftRight_stat_TestedLeftAndRightLampNOK" 3 "LampCheckLeftRight_stat_TestedRightLampNOK" 2 "LampCheckLeftRight_stat_TestedLeftLampNOK" 1 "LampCheckLeftRight_stat_TestedLampOK" 0 "LampCheckLeftRight_stat_NotTested" ;
VAL_ 952 ChassiInstepLightsLamp_stat_ISig 7 "LampCheck_stat_NotAvailable" 6 "LampCheck_stat_Error" 5 "LampCheck_stat_Spare_02" 4 "LampCheck_stat_Spare_01" 3 "LampCheck_stat_Spare" 2 "LampCheck_stat_TestedLampNOK" 1 "LampCheck_stat_TestedLampOK" 0 "LampCheck_stat_NotTested" ;
VAL_ 952 ExtraMainBeamLamp_stat_ISig_6 7 "LampCheckLeftRight_stat_NotAvailable" 6 "LampCheckLeftRight_stat_Error" 5 "LampCheckLeftRight_stat_Spare" 4 "LampCheckLeftRight_stat_TestedLeftAndRightLampNOK" 3 "LampCheckLeftRight_stat_TestedRightLampNOK" 2 "LampCheckLeftRight_stat_TestedLeftLampNOK" 1 "LampCheckLeftRight_stat_TestedLampOK" 0 "LampCheckLeftRight_stat_NotTested" ;
VAL_ 952 AuxFogLightLamp_stat_ISig_6 7 "LampCheckLeftRight_stat_NotAvailable" 6 "LampCheckLeftRight_stat_Error" 5 "LampCheckLeftRight_stat_Spare" 4 "LampCheckLeftRight_stat_TestedLeftAndRightLampNOK" 3 "LampCheckLeftRight_stat_TestedRightLampNOK" 2 "LampCheckLeftRight_stat_TestedLeftLampNOK" 1 "LampCheckLeftRight_stat_TestedLampOK" 0 "LampCheckLeftRight_stat_NotTested" ;
VAL_ 952 PositionLightLamp_stat_ISig_6 7 "LampCheckLeftRight_stat_NotAvailable" 6 "LampCheckLeftRight_stat_Error" 5 "LampCheckLeftRight_stat_Spare" 4 "LampCheckLeftRight_stat_TestedLeftAndRightLampNOK" 3 "LampCheckLeftRight_stat_TestedRightLampNOK" 2 "LampCheckLeftRight_stat_TestedLeftLampNOK" 1 "LampCheckLeftRight_stat_TestedLampOK" 0 "LampCheckLeftRight_stat_NotTested" ;
VAL_ 952 FogLightFrontLamp_stat_ISig_6 7 "LampCheck_stat_NotAvailable" 6 "LampCheck_stat_Error" 5 "LampCheck_stat_Spare_02" 4 "LampCheck_stat_Spare_01" 3 "LampCheck_stat_Spare" 2 "LampCheck_stat_TestedLampNOK" 1 "LampCheck_stat_TestedLampOK" 0 "LampCheck_stat_NotTested" ;
VAL_ 952 DRLLamp_stat_ISig_6 7 "LampCheckLeftRight_stat_NotAvailable" 6 "LampCheckLeftRight_stat_Error" 5 "LampCheckLeftRight_stat_Spare" 4 "LampCheckLeftRight_stat_TestedLeftAndRightLampNOK" 3 "LampCheckLeftRight_stat_TestedRightLampNOK" 2 "LampCheckLeftRight_stat_TestedLeftLampNOK" 1 "LampCheckLeftRight_stat_TestedLampOK" 0 "LampCheckLeftRight_stat_NotTested" ;
VAL_ 1367 FasDriver_ISig_6 15 "FasDriver_NotAvailable" 14 "FasDriver_Error" 13 "FasDriver_Spare3" 12 "FasDriver_Spare2" 11 "FasDriver_Spare1" 10 "FasDriver_Driver10" 9 "FasDriver_Driver9" 8 "FasDriver_Driver8" 7 "FasDriver_Driver7" 6 "FasDriver_Driver6" 5 "FasDriver_Driver5" 4 "FasDriver_Driver4" 3 "FasDriver_Driver3" 2 "FasDriver_Driver2" 1 "FasDriver_Driver1" 0 "FasDriver_DefaultDriver" ;
VAL_ 1367 ActualFasPersSettingsButton_ISig 7 "FasPersSettingsButton_NotAvailable" 6 "FasPersSettingsButton_Error" 5 "FasPersSettingsButton_Spare" 4 "FasPersSettingsButton_UserDefinedButton" 3 "FasPersSettingsButton_PresetButtonHeavy" 2 "FasPersSettingsButton_PresetButtonFirm" 1 "FasPersSettingsButton_PresetButtonLight" 0 "FasPersSettingsButton_PresetButtonDefault" ;
VAL_ 520 OverSteerGuidanceStatus_ISig_6 3 "InactiveActive_NotAvailable" 2 "InactiveActive_Error" 1 "InactiveActive_Active" 0 "InactiveActive_Inactive" ;
VAL_ 520 FASFullyOperational_ISig_6 3 "FASFullyOperational_NotAvailable" 2 "FASFullyOperational_Error" 1 "FASFullyOperational_FASFullyOperational" 0 "FASFullyOperational_FASNotFullyOperational" ;
VAL_ 520 FASSaturated_ISig_6 3 "FASSaturated_NotAvailable" 2 "FASSaturated_Error" 1 "FASSaturated_FAS_IsSaturated" 0 "FASSaturated_FAS_IsNotSaturated" ;
VAL_ 520 FASFunctionInControl_ISig_6 3 "FASFunctionInControl_NotAvailable" 2 "FASFunctionInControl_Error" 1 "FASFunctionInControl_FunctionInControl" 0 "FASFunctionInControl_DriverInControl" ;
VAL_ 1232 ABSAxle5Active 3 "OffOn_NotAvailable" 2 "OffOn_Error" 1 "OffOn_On" 0 "OffOn_Off" ;
VAL_ 1232 ABSAxle4Active 3 "OffOn_NotAvailable" 2 "OffOn_Error" 1 "OffOn_On" 0 "OffOn_Off" ;
VAL_ 1232 ABSAxle2Active 3 "OffOn_NotAvailable" 2 "OffOn_Error" 1 "OffOn_On" 0 "OffOn_Off" ;
VAL_ 1232 ABSAxle3Active 3 "OffOn_NotAvailable" 2 "OffOn_Error" 1 "OffOn_On" 0 "OffOn_Off" ;
VAL_ 1232 ABSAxle1Active 3 "OffOn_NotAvailable" 2 "OffOn_Error" 1 "OffOn_On" 0 "OffOn_Off" ;
VAL_ 1232 HillHolderMode_ISig_6 7 "HillHolderMode_NotAvailable" 6 "HillHolderMode_Reserved" 5 "HillHolderMode_Spare2" 4 "HillHolderMode_Spare1" 3 "HillHolderMode_OnHold_PressureApplied" 2 "HillHolderMode_Active_WillChangeToInactiveSoon" 1 "HillHolderMode_Active" 0 "HillHolderMode_Inactive" ;
VAL_ 1501 Trailer2TireInfoISO_Warning_ISig 7 "TPMPressureWarning_NotAvailable" 6 "TPMPressureWarning_Error" 5 "TPMPressureWarning_Spare" 4 "TPMPressureWarning_ExtremeUnderPressure" 3 "TPMPressureWarning_UnderPressure" 2 "TPMPressureWarning_NoWarningPressure" 1 "TPMPressureWarning_OverPressure" 0 "TPMPressureWarning_ExtremeOverPressure" ;
VAL_ 1501 Trailer2TireInfoISO_PresSuff_ISi 3 "TPMISOPresSuff_NotAvailable" 2 "TPMISOPresSuff_Error" 1 "TPMISOPresSuff_TirePressureSufficient" 0 "TPMISOPresSuff_TirePressureInsufficient" ;
VAL_ 1501 Trailer2TireInfoISO_PowerSupply_ 3 "TPMISOPowerSupply_NotAvailable" 2 "TPMISOPowerSupply_Error" 1 "TPMISOPowerSupply_SufficientPowerSupply" 0 "TPMISOPowerSupply_InsufficientPowerSupply" ;
VAL_ 1501 Trailer2TireInfoISO_Active_ISig_ 3 "TPMTireActive_NotAvailable" 2 "TPMTireActive_Error" 1 "TPMTireActive_TireActivePositioned" 0 "TPMTireActive_TireNotActive" ;
VAL_ 1498 Trailer1TireInfoISO_Active_ISig_ 3 "TPMTireActive_NotAvailable" 2 "TPMTireActive_Error" 1 "TPMTireActive_TireActivePositioned" 0 "TPMTireActive_TireNotActive" ;
VAL_ 1498 Trailer1TireInfoISO_PresSuff_ISi 3 "TPMISOPresSuff_NotAvailable" 2 "TPMISOPresSuff_Error" 1 "TPMISOPresSuff_TirePressureSufficient" 0 "TPMISOPresSuff_TirePressureInsufficient" ;
VAL_ 1498 Trailer1TireInfoISO_PowerSupply_ 3 "TPMISOPowerSupply_NotAvailable" 2 "TPMISOPowerSupply_Error" 1 "TPMISOPowerSupply_SufficientPowerSupply" 0 "TPMISOPowerSupply_InsufficientPowerSupply" ;
VAL_ 1498 Trailer1TireInfoISO_Warning_ISig 7 "TPMPressureWarning_NotAvailable" 6 "TPMPressureWarning_Error" 5 "TPMPressureWarning_Spare" 4 "TPMPressureWarning_ExtremeUnderPressure" 3 "TPMPressureWarning_UnderPressure" 2 "TPMPressureWarning_NoWarningPressure" 1 "TPMPressureWarning_OverPressure" 0 "TPMPressureWarning_ExtremeOverPressure" ;
VAL_ 386 EBSBrakeSwitch 3 "EBSBrakeSwitch_NotAvailable" 2 "EBSBrakeSwitch_Error" 1 "EBSBrakeSwitch_BrakePedalDepressed" 0 "EBSBrakeSwitch_BrakePedalReleased" ;
VAL_ 386 BrakeLightActivationRequest 3 "OffOn_NotAvailable" 2 "OffOn_Error" 1 "OffOn_On" 0 "OffOn_Off" ;
VAL_ 386 VDCBrakeLightRequest 3 "VDCBrakeLightRequest_DontCareTakeNoAction" 2 "VDCBrakeLightRequest_Reserved" 1 "VDCBrakeLightRequest_TurnBrakeLightON" 0 "VDCBrakeLightRequest_TurnBrakeLightOFF" ;
VAL_ 824 TrailerEBSAmberWarning 3 "OffOn_NotAvailable" 2 "OffOn_Error" 1 "OffOn_On" 0 "OffOn_Off" ;
VAL_ 824 HSAState_ISig_6 3 "HSAState_NotAvailable" 2 "HSAState_HSA_FunctionFullyOperational" 1 "HSAState_HSA_FunctionnotWorking" 0 "HSAState_HSA_FunctionRestrictedFunctionalityAvailable" ;
VAL_ 824 PusherLiftAxleLoweringInhibit 3 "InhibitStatus_NotAvailable" 2 "InhibitStatus_Reserved" 1 "InhibitStatus_Inhibited" 0 "InhibitStatus_NotInhibited" ;
VAL_ 824 YCBrakeControlActive_ISig_6 3 "PassiveActive2_DontCareTakeNoAction" 2 "PassiveActive2_Reserved" 1 "PassiveActive2_Active" 0 "PassiveActive2_PassiveButInstalled" ;
VAL_ 824 YCEngineControlActive_ISig_6 3 "PassiveActive2_DontCareTakeNoAction" 2 "PassiveActive2_Reserved" 1 "PassiveActive2_Active" 0 "PassiveActive2_PassiveButInstalled" ;
VAL_ 824 StretchBrake_Stat_ISig_6 7 "StretchBrake_Stat_NotAvailable" 6 "StretchBrake_Stat_Error" 5 "StretchBrake_Stat_Spare_02" 4 "StretchBrake_Stat_Spare_01" 3 "StretchBrake_Stat_Spare" 2 "StretchBrake_Stat_Active" 1 "StretchBrake_Stat_Enabled" 0 "StretchBrake_Stat_Disabled" ;
VAL_ 824 Trailer1LiftAxle1Pos_ISig_6 3 "TrailerLiftAxlePos_NotAvailable" 2 "TrailerLiftAxlePos_Error" 1 "TrailerLiftAxlePos_AxleLifted" 0 "TrailerLiftAxlePos_AxleDown" ;
VAL_ 824 Trailer1LiftAxle2Pos_ISig_6 3 "TrailerLiftAxlePos_NotAvailable" 2 "TrailerLiftAxlePos_Error" 1 "TrailerLiftAxlePos_AxleLifted" 0 "TrailerLiftAxlePos_AxleDown" ;
VAL_ 824 FrontParkBrakeOverrideStatus 3 "InactiveActive_NotAvailable" 2 "InactiveActive_Error" 1 "InactiveActive_Active" 0 "InactiveActive_Inactive" ;
VAL_ 824 BrakingSystemPressureLim_rqst 3 "Request_NotAvailable" 2 "Request_Error" 1 "Request_RequestActive" 0 "Request_NotRequested" ;
VAL_ 824 ROPEngineControlActive_ISig_6 3 "PassiveActive2_DontCareTakeNoAction" 2 "PassiveActive2_Reserved" 1 "PassiveActive2_Active" 0 "PassiveActive2_PassiveButInstalled" ;
VAL_ 824 Trailer1TractionHelp_ISig_6 3 "InactiveActive_NotAvailable" 2 "InactiveActive_Error" 1 "InactiveActive_Active" 0 "InactiveActive_Inactive" ;
VAL_ 824 TagLiftAxleLoweringInhibit 3 "InhibitStatus_NotAvailable" 2 "InhibitStatus_Reserved" 1 "InhibitStatus_Inhibited" 0 "InhibitStatus_NotInhibited" ;
VAL_ 824 ROPBrakeControlActive_ISig_6 3 "PassiveActive2_DontCareTakeNoAction" 2 "PassiveActive2_Reserved" 1 "PassiveActive2_Active" 0 "PassiveActive2_PassiveButInstalled" ;
VAL_ 824 SplitBoxDiffLockActvnFuncReq 3 "DisengageEngage_NotAvailable" 2 "DisengageEngage_Error" 1 "DisengageEngage_Engage" 0 "DisengageEngage_Disengage" ;
VAL_ 824 TrailerBrake_Stat 3 "InactiveActive_NotAvailable" 2 "InactiveActive_Error" 1 "InactiveActive_Active" 0 "InactiveActive_Inactive" ;
VAL_ 516 EASPusherLiftAxleLoweringInhib 3 "InhibitStatus_NotAvailable" 2 "InhibitStatus_Reserved" 1 "InhibitStatus_Inhibited" 0 "InhibitStatus_NotInhibited" ;
VAL_ 516 ExtraAxleSteeringFunctionStat_IS 7 "RearAxleSteeringFunctionStatus_NotAvailable" 6 "RearAxleSteeringFunctionStatus_Error" 5 "RearAxleSteeringFunctionStatus_SpareValue_01" 4 "RearAxleSteeringFunctionStatus_SpareValue" 3 "RearAxleSteeringFunctionStatus_ActiveFailureMode" 2 "RearAxleSteeringFunctionStatus_PassiveFailureMode" 1 "RearAxleSteeringFunctionStatus_Active" 0 "RearAxleSteeringFunctionStatus_NotActive" ;
VAL_ 516 EASTagLiftAxleLoweringInhibit 3 "InhibitStatus_NotAvailable" 2 "InhibitStatus_Reserved" 1 "InhibitStatus_Inhibited" 0 "InhibitStatus_NotInhibited" ;
SIG_GROUP_ 1501 Trailer2TireInfoISO_sg_ISig_6 1 : Trailer2TireInfoISO_Leakage_ISig Trailer2TireInfoISO_TireId_ISig_ Trailer2TireInfoISO_Warning_ISig Trailer2TireInfoISO_Pressure_ISi Trailer2TireInfoISO_PresSuff_ISi Trailer2TireInfoISO_PowerSupply_ Trailer2TireInfoISO_Active_ISig_ Trailer2TireInfoISO_Temperature_;
SIG_GROUP_ 1498 Trailer1TireInfoISO_sg_ISig_6 1 : Trailer1TireInfoISO_Leakage_ISig Trailer1TireInfoISO_Pressure_ISi Trailer1TireInfoISO_Active_ISig_ Trailer1TireInfoISO_PresSuff_ISi Trailer1TireInfoISO_Temperature_ Trailer1TireInfoISO_PowerSupply_ Trailer1TireInfoISO_TireId_ISig_ Trailer1TireInfoISO_Warning_ISig;
SIG_GROUP_ 396 SteeringWheel_sg 1 : SteeringWheel_AngleValue SteeringWheel_AngleCounter SteeringWheel_AngleCRC;
SIG_GROUP_ 1502 DiagFaultStat_TPM_sg_ISig_6 1 : DiagFaultStat_TPM_FailTB_ISig_6 DiagFaultStat_TPM_EcuAdr_ISig_6 DiagFaultStat_TPM_DtcIdA_ISig_6 DiagFaultStat_TPM_FailTA_ISig_6 DiagFaultStat_TPM_DtcIdB_ISig_6;
SIG_GROUP_ 1500 DiagFaultStat_RCIOM_sg_ISig_6 1 : DiagFaultStat_RCIOM_FailTA_ISig_ DiagFaultStat_RCIOM_FailTB_ISig_ DiagFaultStat_RCIOM_DtcIdA_ISig_ DiagFaultStat_RCIOM_DtcIdB_ISig_ DiagFaultStat_RCIOM_EcuAdr_ISig_;
SIG_GROUP_ 1497 DiagFaultStat_GFHCM2_sg_ISig_6 1 : DiagFaultStat_GFHCM2_FailTB_ISig DiagFaultStat_GFHCM2_EcuAdr_ISig DiagFaultStat_GFHCM2_FailTA_ISig DiagFaultStat_GFHCM2_DtcIdA_ISig DiagFaultStat_GFHCM2_DtcIdB_ISig;
SIG_GROUP_ 1496 DiagFaultStat_GFHCM1_sg_ISig_6 1 : DiagFaultStat_GFHCM1_EcuAdr_ISig DiagFaultStat_GFHCM1_FailTB_ISig DiagFaultStat_GFHCM1_DtcIdA_ISig DiagFaultStat_GFHCM1_DtcIdB_ISig DiagFaultStat_GFHCM1_FailTA_ISig;
SIG_GROUP_ 1499 DiagFaultStat_FCIOM_sg_ISig_6 1 : DiagFaultStat_FCIOM_DtcIdA_ISig_ DiagFaultStat_FCIOM_FailTB_ISig_ DiagFaultStat_FCIOM_EcuAdr_ISig_ DiagFaultStat_FCIOM_FailTA_ISig_ DiagFaultStat_FCIOM_DtcIdB_ISig_;
SIG_GROUP_ 1491 DiagFaultStat_FAS_sg_ISig_6 1 : DiagFaultStat_FAS_FailTA_ISig_6 DiagFaultStat_FAS_DtcIdA_ISig_6 DiagFaultStat_FAS_EcuAdr_ISig_6 DiagFaultStat_FAS_FailTB_ISig_6 DiagFaultStat_FAS_DtcIdB_ISig_6;
SIG_GROUP_ 1493 DiagFaultStat_EAS_sg_ISig_6 1 : DiagFaultStat_EAS_FailTA_ISig_6 DiagFaultStat_EAS_FailTB_ISig_6 DiagFaultStat_EAS_EcuAdr_ISig_6 DiagFaultStat_EAS_DtcIdA_ISig_6 DiagFaultStat_EAS_DtcIdB_ISig_6;
SIG_GROUP_ 1490 DiagFaultStat_CCIOM_sg_ISig_6 1 : DiagFaultStat_CCIOM_FailTB_ISig_ DiagFaultStat_CCIOM_DtcIdB_ISig_ DiagFaultStat_CCIOM_EcuAdr_ISig_ DiagFaultStat_CCIOM_FailTA_ISig_ DiagFaultStat_CCIOM_DtcIdA_ISig_;
SIG_GROUP_ 1494 DiagFaultStat_BPMU_sg_ISig_6 1 : DiagFaultStat_BPMU_DtcIdB_ISig_6 DiagFaultStat_BPMU_EcuAdr_ISig_6 DiagFaultStat_BPMU_FailTA_ISig_6 DiagFaultStat_BPMU_FailTB_ISig_6 DiagFaultStat_BPMU_DtcIdA_ISig_6;
SIG_GROUP_ 1489 DiagFaultStat_APM_sg_ISig_6 1 : DiagFaultStat_APM_FailTB_ISig_6 DiagFaultStat_APM_EcuAdr_ISig_6 DiagFaultStat_APM_FailTA_ISig_6 DiagFaultStat_APM_DtcIdA_ISig_6 DiagFaultStat_APM_DtcIdB_ISig_6;
